VERSION ""

NS_ :

BS_:

BU_: WPC2 RLPSU DPSU APSU PSB SHVU_RR vHS_B2 FCS EMCU SLB ARS RCM CGW_CCU vDummy_HS_B ATS RLHV SGU PFSU ALBCU DSAU SWRC SHVU_FR RCS RRPSU BLTN_CAM SCM DLBCU OHCL RWPC RRHV WPC HOD ASAU

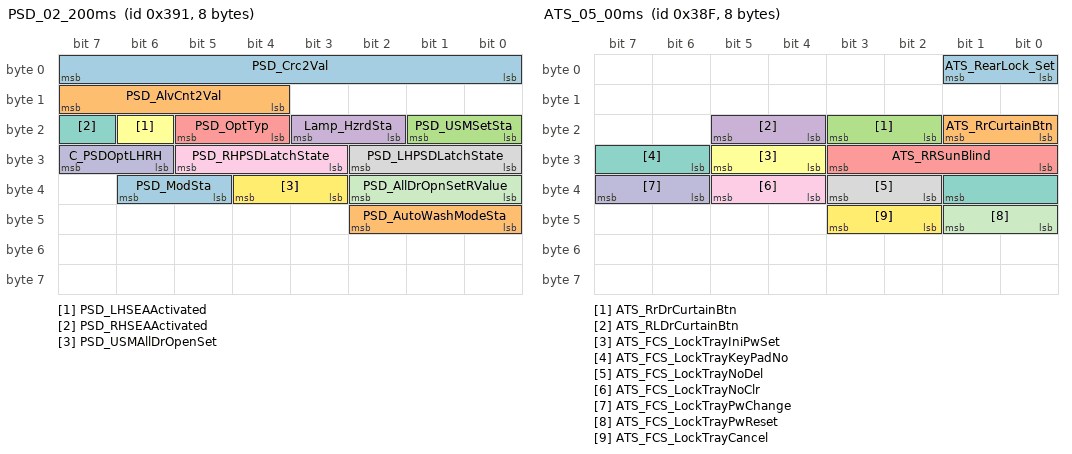
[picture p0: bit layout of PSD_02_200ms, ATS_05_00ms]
BO_ 913 PSD_02_200ms: 8 CGW_CCU
 SG_ PSD_Crc2Val : 0|8@1+ (1,0) [0|0] "" Vector__XXX
 SG_ PSD_AlvCnt2Val : 12|4@1+ (1,0) [0|0] "" Vector__XXX
 SG_ PSD_USMSetSta : 16|2@1+ (1,0) [0|0] "" Vector__XXX
 SG_ Lamp_HzrdSta : 18|2@1+ (1,0) [0|0] "" Vector__XXX
 SG_ PSD_OptTyp : 20|2@1+ (1,0) [0|0] "" Vector__XXX
 SG_ PSD_LHSEAActivated : 22|1@1+ (1,0) [0|0] "" Vector__XXX
 SG_ PSD_RHSEAActivated : 23|1@1+ (1,0) [0|0] "" Vector__XXX
 SG_ PSD_LHPSDLatchState : 24|3@1+ (1,0) [0|0] ""  ARS,PFSU,WPC2
 SG_ PSD_RHPSDLatchState : 27|3@1+ (1,0) [0|0] ""  ARS,PFSU,WPC2
 SG_ C_PSDOptLHRH : 30|2@1+ (1,0) [0|0] "" Vector__XXX
 SG_ PSD_AllDrOpnSetRValue : 32|3@1+ (1,0) [0|0] "" Vector__XXX
 SG_ PSD_USMAllDrOpenSet : 35|2@1+ (1,0) [0|0] "" Vector__XXX
 SG_ PSD_ModSta : 37|2@1+ (1,0) [0|0] "" Vector__XXX
 SG_ PSD_AutoWashModeSta : 40|3@1+ (1,0) [0|0] "" Vector__XXX

BO_ 911 ATS_05_00ms: 8 ATS
 SG_ ATS_RearLock_Set : 0|2@1+ (1,0) [0|0] ""  CGW_CCU
 SG_ ATS_RrCurtainBtn : 16|2@1+ (1,0) [0|0] ""  CGW_CCU
 SG_ ATS_RrDrCurtainBtn : 18|2@1+ (1,0) [0|0] "" Vector__XXX
 SG_ ATS_RLDrCurtainBtn : 20|2@1+ (1,0) [0|0] "" Vector__XXX
 SG_ ATS_RRSunBlind : 24|4@1+ (1,0) [0|0] ""  RCM,CGW_CCU
 SG_ ATS_FCS_LockTrayIniPwSet : 28|2@1+ (1,0) [0|0] ""  FCS
 SG_ ATS_FCS_LockTrayKeyPadNo : 30|4@1+ (1,0) [0|0] ""  FCS
 SG_ ATS_FCS_LockTrayNoDel : 34|2@1+ (1,0) [0|0] ""  FCS
 SG_ ATS_FCS_LockTrayNoClr : 36|2@1+ (1,0) [0|0] ""  FCS
 SG_ ATS_FCS_LockTrayPwChange : 38|2@1+ (1,0) [0|0] ""  FCS
 SG_ ATS_FCS_LockTrayPwReset : 40|2@1+ (1,0) [0|0] ""  FCS
 SG_ ATS_FCS_LockTrayCancel : 42|2@1+ (1,0) [0|0] ""  FCS

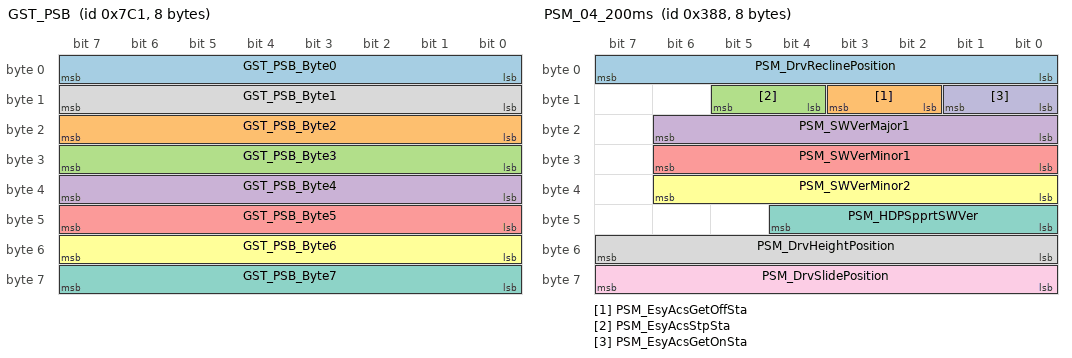
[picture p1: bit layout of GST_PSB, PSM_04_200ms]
BO_ 1985 GST_PSB: 8 CGW_CCU
 SG_ GST_PSB_Byte0 : 0|8@1+ (1,0) [0|0] ""  PSB
 SG_ GST_PSB_Byte2 : 16|8@1+ (1,0) [0|0] ""  PSB
 SG_ GST_PSB_Byte3 : 24|8@1+ (1,0) [0|0] ""  PSB
 SG_ GST_PSB_Byte4 : 32|8@1+ (1,0) [0|0] ""  PSB
 SG_ GST_PSB_Byte5 : 40|8@1+ (1,0) [0|0] ""  PSB
 SG_ GST_PSB_Byte6 : 48|8@1+ (1,0) [0|0] ""  PSB
 SG_ GST_PSB_Byte7 : 56|8@1+ (1,0) [0|0] ""  PSB
 SG_ GST_PSB_Byte1 : 8|8@1+ (1,0) [0|0] ""  PSB

BO_ 2382594817 DATC_06_200ms_1: 8 CGW_CCU
 SG_ DATC_Crc6Val : 0|16@1+ (1,0) [0|0] "" Vector__XXX
 SG_ DATC_AlvCnt6Val : 16|8@1+ (1,0) [0|0] "" Vector__XXX
 SG_ DATC_RrAcDis : 24|2@1+ (1,0) [0|0] "" Vector__XXX
 SG_ DATC_MaxAcDis : 26|2@1+ (1,0) [0|0] "" Vector__XXX
 SG_ DATC_SyncDis : 28|2@1+ (1,0) [0|0] ""  ATS
 SG_ DATC_OpSta : 32|3@1+ (1,0) [0|0] ""  ATS
 SG_ DATC_FrDfgSta : 35|2@1+ (1,0) [0|0] "" Vector__XXX
 SG_ DATC_SmrtVntDis : 37|2@1+ (1,0) [0|0] "" Vector__XXX
 SG_ DATC_AutoDfgBlnkDis : 40|2@1+ (1,0) [0|0] "" Vector__XXX
 SG_ DATC_AutoDfgSysOffDis : 42|2@1+ (1,0) [0|0] "" Vector__XXX
 SG_ DATC_SchdldVntOpSta : 50|2@1+ (1,0) [0|0] "" Vector__XXX
 SG_ DATC_3rdAcDis : 52|2@1+ (1,0) [0|0] "" Vector__XXX
 SG_ DATC_ArClnIND : 54|2@1+ (1,0) [0|0] ""  ATS
 SG_ DATC_RrDfgInd : 56|2@1+ (1,0) [0|0] "" Vector__XXX
 SG_ DATC_FrModDEFInd : 58|2@1+ (1,0) [0|0] "" Vector__XXX
 SG_ DATC_FrModVentInd : 60|2@1+ (1,0) [0|0] "" Vector__XXX
 SG_ DATC_FrModFloorInd : 62|2@1+ (1,0) [0|0] "" Vector__XXX

BO_ 905 SBCM_RR_01_200ms: 8 CGW_CCU
 SG_ SBCM_RR_Crc1Val : 0|8@1+ (1,0) [0|0] "" Vector__XXX
 SG_ RR_CrashUnlockCmd : 10|1@1+ (1,0) [0|0] ""  BLTN_CAM
 SG_ SBCM_RR_AlvCnt1Val : 12|4@1+ (1,0) [0|0] "" Vector__XXX
 SG_ Warn_RrRtDrSwSta_SBCM : 16|2@1+ (1,0) [0|0] ""  WPC,RWPC,APSU,RRPSU,ATS,BLTN_CAM,WPC2
 SG_ DoorLock_RrRtDrUnLkSta_SBCM : 18|2@1+ (1,0) [0|0] ""  ATS
 SG_ RR_SEAActivated : 20|2@1+ (1,0) [0|0] "" Vector__XXX
 SG_ RR_SEAWarn : 22|2@1+ (1,0) [0|0] "" Vector__XXX
 SG_ RR_SEWWarn : 24|2@1+ (1,0) [0|0] "" Vector__XXX
 SG_ RR_ReleaseWarn : 26|2@1+ (1,0) [0|0] "" Vector__XXX
 SG_ RR_SWFailAlarm : 28|2@1+ (1,0) [0|0] "" Vector__XXX
 SG_ RR_ChildLock_ActnFlSta : 30|2@1+ (1,0) [0|0] "" Vector__XXX
 SG_ RR_MRActivationAlarm : 32|2@1+ (1,0) [0|0] "" Vector__XXX
 SG_ RR_ChildLock_Status : 34|2@1+ (1,0) [0|0] "" Vector__XXX
 SG_ USM_RRGhostDoorSta : 36|2@1+ (1,0) [0|0] "" Vector__XXX
 SG_ DoorLock_PDSLkSwSta_RR : 40|2@1+ (1,0) [0|0] "" Vector__XXX
 SG_ PDS_TypeOption_RR : 42|2@1+ (1,0) [0|0] "" Vector__XXX
 SG_ RRDoorPushAlarm : 8|2@1+ (1,0) [0|0] "" Vector__XXX

BO_ 904 PSM_04_200ms: 8 DPSU
 SG_ PSM_DrvReclinePosition : 0|8@1+ (1,0) [0|0] ""  CGW_CCU
 SG_ PSM_EsyAcsGetOffSta : 10|2@1+ (1,0) [0|0] ""  DLBCU,DSAU
 SG_ PSM_EsyAcsStpSta : 12|2@1+ (1,0) [0|0] ""  DLBCU,DSAU
 SG_ PSM_SWVerMajor1 : 16|7@1+ (1,0) [0|0] ""  CGW_CCU
 SG_ PSM_SWVerMinor1 : 24|7@1+ (1,0) [0|0] ""  CGW_CCU
 SG_ PSM_SWVerMinor2 : 32|7@1+ (1,0) [0|0] ""  CGW_CCU
 SG_ PSM_HDPSpprtSWVer : 40|5@1+ (1,0) [0|0] ""  CGW_CCU
 SG_ PSM_DrvHeightPosition : 48|8@1+ (1,0) [0|0] ""  CGW_CCU
 SG_ PSM_DrvSlidePosition : 56|8@1+ (2,0) [0|0] ""  CGW_CCU
 SG_ PSM_EsyAcsGetOnSta : 8|2@1+ (1,0) [0|0] ""  DLBCU,DSAU

BO_ 903 PSM_03_200ms: 8 DPSU
 SG_ PSM_DrvStSldFwdDis : 0|2@1+ (1,0) [0|0] ""  CGW_CCU
 SG_ PSM_DrvStTiltDnDis : 10|2@1+ (1,0) [0|0] ""  CGW_CCU
 SG_ PSM_DrvStHghtUpDis : 12|2@1+ (1,0) [0|0] ""  CGW_CCU
 SG_ PSM_DrvStHghtDnDis : 14|2@1+ (1,0) [0|0] ""  CGW_CCU
 SG_ PSM_DrvStCushExtBckwdDis : 16|2@1+ (1,0) [0|0] ""  CGW_CCU
 SG_ PSM_DrvStCushExtFwdDis : 18|2@1+ (1,0) [0|0] ""  CGW_CCU
 SG_ PSM_DrvStSldBckwdDis : 2|2@1+ (1,0) [0|0] ""  CGW_CCU
 SG_ PSM_DrvStHdRstUpDis : 20|2@1+ (1,0) [0|0] ""  CGW_CCU
 SG_ PSM_DrvStHdRstDnDis : 22|2@1+ (1,0) [0|0] ""  CGW_CCU
 SG_ PSM_DrvStHdRstFwdDis : 24|2@1+ (1,0) [0|0] ""  CGW_CCU
 SG_ PSM_DrvStHdRstBckwdDis : 26|2@1+ (1,0) [0|0] ""  CGW_CCU
 SG_ PSM_DrvStLmbrDefDis : 32|2@1+ (1,0) [0|0] ""  CGW_CCU
 SG_ PSM_DrvStLmbrLoDis : 34|2@1+ (1,0) [0|0] ""  CGW_CCU
 SG_ PSM_DrvStLmbrMdlDis : 36|2@1+ (1,0) [0|0] ""  CGW_CCU
 SG_ PSM_DrvStLmbrUpDis : 38|2@1+ (1,0) [0|0] ""  CGW_CCU
 SG_ PSM_DrvStReclneFwdDis : 4|2@1+ (1,0) [0|0] ""  CGW_CCU
 SG_ PSM_DrvStBlstrDefDis : 40|2@1+ (1,0) [0|0] ""  CGW_CCU
 SG_ PSM_DrvStBlstrInfDis : 42|2@1+ (1,0) [0|0] ""  CGW_CCU
 SG_ PSM_DrvStReclneBckwdDis : 6|2@1+ (1,0) [0|0] ""  CGW_CCU
 SG_ PSM_DrvStTiltUpDis : 8|2@1+ (1,0) [0|0] ""  CGW_CCU

BO_ 902 PSM_02_200ms: 8 DPSU
 SG_ PSM_DrvStEsyAcsUSMSta : 0|3@1+ (1,0) [0|0] ""  DLBCU,DSAU,CGW_CCU
 SG_ PSM_SeatPosPlyBck_Sta : 10|3@1+ (1,0) [0|0] "" Vector__XXX
 SG_ PSM_SeatPos_Sta : 13|3@1+ (1,0) [0|0] "" Vector__XXX
 SG_ PSM_SeatPosSldLmt_Sta : 16|2@1+ (1,0) [0|0] ""  CGW_CCU
 SG_ PSM_SeatPosRclnLmt_Sta : 18|2@1+ (1,0) [0|0] ""  CGW_CCU
 SG_ SmrtIMS_StatureRspVal : 24|4@1+ (1,0) [0|0] ""  CGW_CCU
 SG_ SmrtIMS_SeatedHghtRspVal : 28|4@1+ (1,0) [0|0] ""  CGW_CCU
 SG_ SmrtIMS_WghtRspVal : 32|4@1+ (1,0) [0|0] ""  CGW_CCU
 SG_ SmartIMS_DisReq : 36|3@1+ (1,0) [0|0] ""  CGW_CCU
 SG_ SmrtIMS_ExitSta : 40|3@1+ (1,0) [0|0] ""  CGW_CCU
 SG_ PSM_DrvStRlxTiltUpDis : 43|2@1+ (1,0) [0|0] ""  CGW_CCU
 SG_ PSM_DrvStRlxTiltDnDis : 45|2@1+ (1,0) [0|0] ""  CGW_CCU
 SG_ PSM_DrvStLegUpDis : 47|2@1+ (1,0) [0|0] ""  CGW_CCU
 SG_ PSM_DrvStLegDnDis : 49|2@1+ (1,0) [0|0] ""  CGW_CCU
 SG_ Drv_2ndStAutoRlxEnable : 57|2@1+ (1,0) [0|0] ""  RLPSU,RRPSU
 SG_ Drv_AutoRlxSta : 59|2@1+ (1,0) [0|0] ""  RLPSU,RRPSU,CGW_CCU
 SG_ Drv_AutoReturnSta : 61|2@1+ (1,0) [0|0] ""  CGW_CCU
 SG_ PSM_IMSOptTyp : 8|2@1+ (1,0) [0|0] ""  CGW_CCU

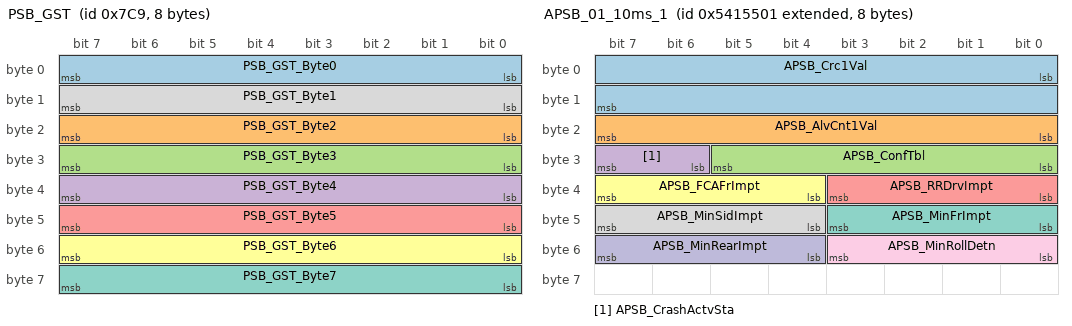
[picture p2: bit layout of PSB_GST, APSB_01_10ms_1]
BO_ 1993 PSB_GST: 8 PSB
 SG_ PSB_GST_Byte0 : 0|8@1+ (1,0) [0|0] ""  CGW_CCU
 SG_ PSB_GST_Byte2 : 16|8@1+ (1,0) [0|0] ""  CGW_CCU
 SG_ PSB_GST_Byte3 : 24|8@1+ (1,0) [0|0] ""  CGW_CCU
 SG_ PSB_GST_Byte4 : 32|8@1+ (1,0) [0|0] ""  CGW_CCU
 SG_ PSB_GST_Byte5 : 40|8@1+ (1,0) [0|0] ""  CGW_CCU
 SG_ PSB_GST_Byte6 : 48|8@1+ (1,0) [0|0] ""  CGW_CCU
 SG_ PSB_GST_Byte7 : 56|8@1+ (1,0) [0|0] ""  CGW_CCU
 SG_ PSB_GST_Byte1 : 8|8@1+ (1,0) [0|0] ""  CGW_CCU

BO_ 1016 HU_GNSS_14_1000ms: 8 CGW_CCU
 SG_ GNSS_MM_type : 0|4@1+ (1,0) [0|0] ""  BLTN_CAM

BO_ 1019 HU_MOOD_E_01: 8 CGW_CCU
 SG_ HU_MoodTherapyDrSeat : 0|2@1+ (1,0) [0|0] ""  DSAU
 SG_ HU_VitalityFragrance : 10|2@1+ (1,0) [0|0] "" Vector__XXX
 SG_ HU_VitalityCurtain : 12|2@1+ (1,0) [0|0] "" Vector__XXX
 SG_ HU_DelightMoodLamp : 14|2@1+ (1,0) [0|0] "" Vector__XXX
 SG_ HU_DelightFragrance : 16|2@1+ (1,0) [0|0] "" Vector__XXX
 SG_ HU_DelightCurtain : 18|2@1+ (1,0) [0|0] "" Vector__XXX
 SG_ HU_MoodTherapyPsSeat : 2|2@1+ (1,0) [0|0] ""  ASAU
 SG_ HU_CareMoodLamp : 20|2@1+ (1,0) [0|0] "" Vector__XXX
 SG_ HU_CareFragrance : 22|2@1+ (1,0) [0|0] "" Vector__XXX
 SG_ HU_CareMassage : 24|2@1+ (1,0) [0|0] ""  DSAU,ASAU
 SG_ HU_CareCurtain : 26|2@1+ (1,0) [0|0] "" Vector__XXX
 SG_ HU_ComfortMoodLamp : 28|2@1+ (1,0) [0|0] "" Vector__XXX
 SG_ HU_ComfortFragrance : 30|2@1+ (1,0) [0|0] "" Vector__XXX
 SG_ HU_ComfortMassage : 32|2@1+ (1,0) [0|0] ""  DSAU,ASAU
 SG_ HU_ComfortCurtain : 34|2@1+ (1,0) [0|0] "" Vector__XXX
 SG_ HU_MoodTherapyMode : 36|3@1+ (1,0) [0|0] ""  DSAU,ASAU
 SG_ HU_MoodTherapyRlSeat : 4|2@1+ (1,0) [0|0] "" Vector__XXX
 SG_ HU_MoodTherapyRrSeat : 6|2@1+ (1,0) [0|0] "" Vector__XXX
 SG_ HU_VitalityMoodLamp : 8|2@1+ (1,0) [0|0] "" Vector__XXX

BO_ 2235651330 APSB_01_10ms_2: 8 CGW_CCU

BO_ 2235651329 APSB_01_10ms_1: 8 CGW_CCU
 SG_ APSB_Crc1Val : 0|16@1+ (1,0) [0|0] "" Vector__XXX
 SG_ APSB_AlvCnt1Val : 16|8@1+ (1,0) [0|0] "" Vector__XXX
 SG_ APSB_ConfTbl : 24|6@1+ (1,0) [0|0] ""  PSB
 SG_ APSB_CrashActvSta : 30|2@1+ (1,0) [0|0] ""  PSB
 SG_ APSB_RRDrvImpt : 32|4@1+ (1,0) [0|0] ""  PSB
 SG_ APSB_FCAFrImpt : 36|4@1+ (1,0) [0|0] ""  PSB
 SG_ APSB_MinFrImpt : 40|4@1+ (1,0) [0|0] ""  PSB
 SG_ APSB_MinSidImpt : 44|4@1+ (1,0) [0|0] ""  PSB
 SG_ APSB_MinRollDetn : 48|4@1+ (1,0) [0|0] ""  PSB
 SG_ APSB_MinRearImpt : 52|4@1+ (1,0) [0|0] ""  PSB

BO_ 1015 HU_GNSS_13_1000ms: 8 CGW_CCU
 SG_ HU_MM_Altitude : 0|32@1- (0.01,0) [0|0] "m"  BLTN_CAM
 SG_ HU_MM_Heading : 32|32@1+ (1,0) [0|0] "¢ª"  BLTN_CAM

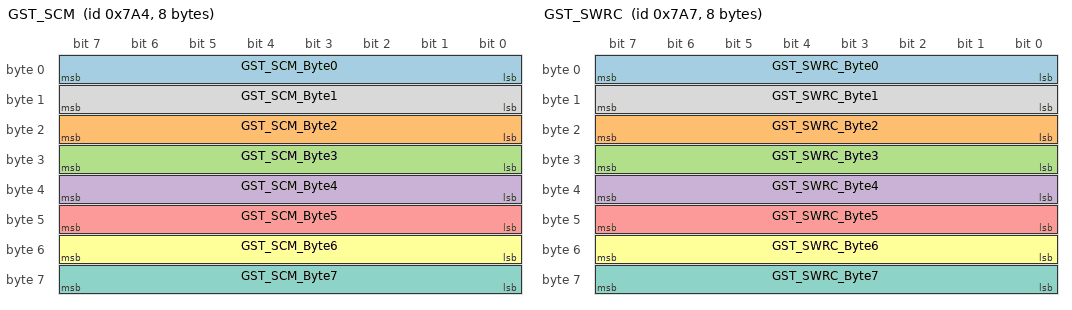
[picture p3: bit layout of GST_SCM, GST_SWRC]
BO_ 1956 GST_SCM: 8 CGW_CCU
 SG_ GST_SCM_Byte0 : 0|8@1+ (1,0) [0|0] ""  SCM
 SG_ GST_SCM_Byte2 : 16|8@1+ (1,0) [0|0] ""  SCM
 SG_ GST_SCM_Byte3 : 24|8@1+ (1,0) [0|0] ""  SCM
 SG_ GST_SCM_Byte4 : 32|8@1+ (1,0) [0|0] ""  SCM
 SG_ GST_SCM_Byte5 : 40|8@1+ (1,0) [0|0] ""  SCM
 SG_ GST_SCM_Byte6 : 48|8@1+ (1,0) [0|0] ""  SCM
 SG_ GST_SCM_Byte7 : 56|8@1+ (1,0) [0|0] ""  SCM
 SG_ GST_SCM_Byte1 : 8|8@1+ (1,0) [0|0] ""  SCM

BO_ 1959 GST_SWRC: 8 CGW_CCU
 SG_ GST_SWRC_Byte0 : 0|8@1+ (1,0) [0|0] ""  SWRC
 SG_ GST_SWRC_Byte2 : 16|8@1+ (1,0) [0|0] ""  SWRC
 SG_ GST_SWRC_Byte3 : 24|8@1+ (1,0) [0|0] ""  SWRC
 SG_ GST_SWRC_Byte4 : 32|8@1+ (1,0) [0|0] ""  SWRC
 SG_ GST_SWRC_Byte5 : 40|8@1+ (1,0) [0|0] ""  SWRC
 SG_ GST_SWRC_Byte6 : 48|8@1+ (1,0) [0|0] ""  SWRC
 SG_ GST_SWRC_Byte7 : 56|8@1+ (1,0) [0|0] ""  SWRC
 SG_ GST_SWRC_Byte1 : 8|8@1+ (1,0) [0|0] ""  SWRC

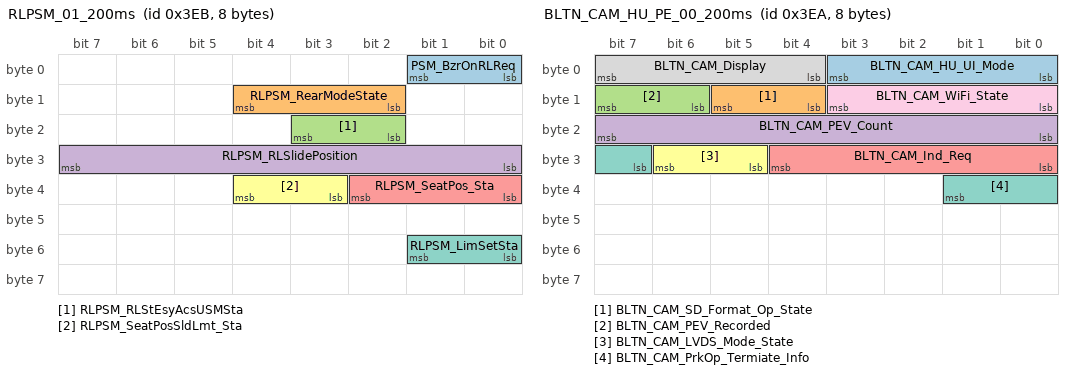
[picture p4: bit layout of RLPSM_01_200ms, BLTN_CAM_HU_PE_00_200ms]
BO_ 1003 RLPSM_01_200ms: 8 RRPSU
 SG_ PSM_BzrOnRLReq : 0|2@1+ (1,0) [0|0] ""  ATS,DPSU
 SG_ RLPSM_RearModeState : 10|3@1+ (1,0) [0|0] ""  APSU,ATS,DPSU,OHCL,CGW_CCU
 SG_ RLPSM_RLStEsyAcsUSMSta : 18|2@1+ (1,0) [0|0] ""  ATS,CGW_CCU
 SG_ RLPSM_RLSlidePosition : 24|8@1+ (2,0) [0|0] ""  APSU,RRPSU
 SG_ RLPSM_SeatPos_Sta : 32|3@1+ (1,0) [0|0] ""  RRPSU
 SG_ RLPSM_SeatPosSldLmt_Sta : 35|2@1+ (1,0) [0|0] "" Vector__XXX
 SG_ RLPSM_LimSetSta : 48|2@1+ (1,0) [0|0] "" Vector__XXX

BO_ 1002 BLTN_CAM_HU_PE_00_200ms: 8 BLTN_CAM
 SG_ BLTN_CAM_HU_UI_Mode : 0|4@1+ (1,0) [0|0] ""  CGW_CCU
 SG_ BLTN_CAM_SD_Format_Op_State : 12|2@1+ (1,0) [0|0] ""  CGW_CCU
 SG_ BLTN_CAM_PEV_Recorded : 14|2@1+ (1,0) [0|0] ""  CGW_CCU
 SG_ BLTN_CAM_PEV_Count : 16|8@1+ (1,0) [0|0] ""  CGW_CCU
 SG_ BLTN_CAM_Ind_Req : 24|5@1+ (1,0) [0|0] ""  CGW_CCU
 SG_ BLTN_CAM_LVDS_Mode_State : 29|2@1+ (1,0) [0|0] ""  CGW_CCU
 SG_ BLTN_CAM_PrkOp_Termiate_Info : 31|3@1+ (1,0) [0|0] ""  CGW_CCU
 SG_ BLTN_CAM_Display : 4|4@1+ (1,0) [0|0] ""  CGW_CCU
 SG_ BLTN_CAM_WiFi_State : 8|4@1+ (1,0) [0|0] ""  CGW_CCU

BO_ 1005 RLPSU_01_200ms: 8 RLPSU
 SG_ RLPSU_FldDis : 0|2@1+ (1,0) [0|0] ""  CGW_CCU
 SG_ RLPSU_TiltDownDis : 10|2@1+ (1,0) [0|0] ""  CGW_CCU
 SG_ RLPSU_RclFwdDis : 12|2@1+ (1,0) [0|0] ""  CGW_CCU
 SG_ RLPSU_RclBwdDis : 14|2@1+ (1,0) [0|0] ""  CGW_CCU
 SG_ RLPSU_RlxModeDis : 16|2@1+ (1,0) [0|0] "" Vector__XXX
 SG_ RLPSU_Folding_SW : 18|2@1+ (1,0) [0|0] "" Vector__XXX
 SG_ RLPSU_UnFldDis : 2|2@1+ (1,0) [0|0] "" Vector__XXX
 SG_ RLPSU_Unfolding_SW : 20|2@1+ (1,0) [0|0] "" Vector__XXX
 SG_ RLPSU_WalkIn_SW : 22|2@1+ (1,0) [0|0] "" Vector__XXX
 SG_ RLPSU_UnwalkIn_SW : 24|2@1+ (1,0) [0|0] "" Vector__XXX
 SG_ RLPSU_Folding_Postion : 26|4@1+ (1,0) [0|0] ""  CGW_CCU
 SG_ RLPSU_Folding_State_PopUp : 30|3@1+ (1,0) [0|0] "" Vector__XXX
 SG_ RLPSU_Relax_State_Popup : 33|3@1+ (1,0) [0|0] "" Vector__XXX
 SG_ RLPSU_SlideFwdDis : 36|2@1+ (1,0) [0|0] ""  CGW_CCU
 SG_ RLPSU_SlideBwdDis : 38|2@1+ (1,0) [0|0] ""  CGW_CCU
 SG_ RLPSU_WalkInDis : 4|2@1+ (1,0) [0|0] "" Vector__XXX
 SG_ RLPSU_WalkInState : 40|2@1+ (1,0) [0|0] "" Vector__XXX
 SG_ RLPSU_UnWalkInDis : 6|2@1+ (1,0) [0|0] "" Vector__XXX
 SG_ RLPSU_TiltUpDis : 8|2@1+ (1,0) [0|0] ""  CGW_CCU

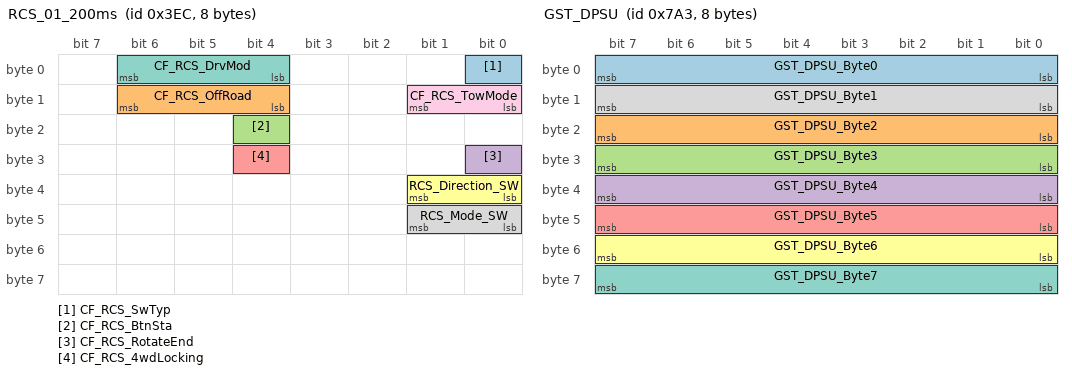
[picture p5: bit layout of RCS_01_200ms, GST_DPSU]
BO_ 1004 RCS_01_200ms: 8 RCS
 SG_ CF_RCS_SwTyp : 0|1@1+ (1,0) [0|0] "Watt"  CGW_CCU
 SG_ CF_RCS_OffRoad : 12|3@1+ (1,0) [0|0] "Watt"  CGW_CCU
 SG_ CF_RCS_BtnSta : 20|1@1+ (1,0) [0|0] "Watt"  CGW_CCU
 SG_ CF_RCS_RotateEnd : 24|1@1+ (1,0) [0|0] "Watt"  CGW_CCU
 SG_ CF_RCS_4wdLocking : 28|1@1+ (1,0) [0|0] "Watt"  CGW_CCU
 SG_ RCS_Direction_SW : 32|2@1+ (1,0) [0|0] ""  CGW_CCU
 SG_ CF_RCS_DrvMod : 4|3@1+ (1,0) [0|0] "Watt"  CGW_CCU
 SG_ RCS_Mode_SW : 40|2@1+ (1,0) [0|0] ""  CGW_CCU
 SG_ CF_RCS_TowMode : 8|2@1+ (1,0) [0|0] ""  CGW_CCU

BO_ 1955 GST_DPSU: 8 CGW_CCU
 SG_ GST_DPSU_Byte0 : 0|8@1+ (1,0) [0|0] ""  DPSU
 SG_ GST_DPSU_Byte2 : 16|8@1+ (1,0) [0|0] ""  DPSU
 SG_ GST_DPSU_Byte3 : 24|8@1+ (1,0) [0|0] ""  DPSU
 SG_ GST_DPSU_Byte4 : 32|8@1+ (1,0) [0|0] ""  DPSU
 SG_ GST_DPSU_Byte5 : 40|8@1+ (1,0) [0|0] ""  DPSU
 SG_ GST_DPSU_Byte6 : 48|8@1+ (1,0) [0|0] ""  DPSU
 SG_ GST_DPSU_Byte7 : 56|8@1+ (1,0) [0|0] ""  DPSU
 SG_ GST_DPSU_Byte1 : 8|8@1+ (1,0) [0|0] ""  DPSU

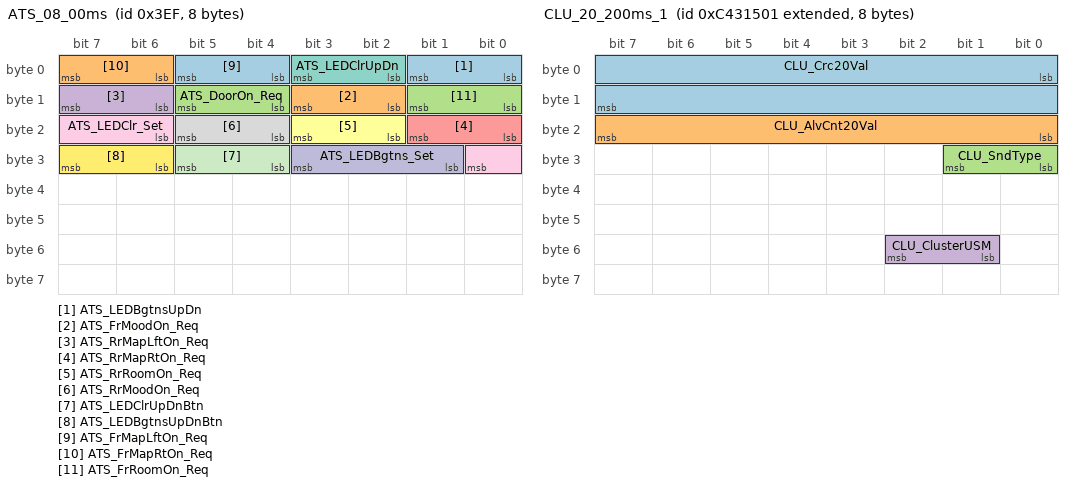
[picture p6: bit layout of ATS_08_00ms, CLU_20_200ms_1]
BO_ 1007 ATS_08_00ms: 8 ATS
 SG_ ATS_LEDBgtnsUpDn : 0|2@1+ (1,0) [0|0] ""  OHCL
 SG_ ATS_FrMoodOn_Req : 10|2@1+ (1,0) [0|0] ""  OHCL
 SG_ ATS_DoorOn_Req : 12|2@1+ (1,0) [0|0] ""  OHCL
 SG_ ATS_RrMapLftOn_Req : 14|2@1+ (1,0) [0|0] ""  OHCL
 SG_ ATS_RrMapRtOn_Req : 16|2@1+ (1,0) [0|0] ""  OHCL
 SG_ ATS_RrRoomOn_Req : 18|2@1+ (1,0) [0|0] ""  OHCL
 SG_ ATS_LEDClrUpDn : 2|2@1+ (1,0) [0|0] ""  OHCL
 SG_ ATS_RrMoodOn_Req : 20|2@1+ (1,0) [0|0] ""  OHCL
 SG_ ATS_LEDClr_Set : 22|3@1+ (1,0) [0|0] ""  OHCL
 SG_ ATS_LEDBgtns_Set : 25|3@1+ (1,0) [0|0] ""  OHCL
 SG_ ATS_LEDClrUpDnBtn : 28|2@1+ (1,0) [0|0] "" Vector__XXX
 SG_ ATS_LEDBgtnsUpDnBtn : 30|2@1+ (1,0) [0|0] "" Vector__XXX
 SG_ ATS_FrMapLftOn_Req : 4|2@1+ (1,0) [0|0] ""  OHCL
 SG_ ATS_FrMapRtOn_Req : 6|2@1+ (1,0) [0|0] ""  OHCL
 SG_ ATS_FrRoomOn_Req : 8|2@1+ (1,0) [0|0] ""  OHCL

BO_ 1006 RRPSU_01_200ms: 8 RRPSU
 SG_ RRPSU_FldDis : 0|2@1+ (1,0) [0|0] ""  CGW_CCU
 SG_ RRPSU_TiltDnDis : 10|2@1+ (1,0) [0|0] ""  CGW_CCU
 SG_ RRPSU_RecFwdDis : 12|2@1+ (1,0) [0|0] ""  CGW_CCU
 SG_ RRPSU_RecBwdDis : 14|2@1+ (1,0) [0|0] ""  CGW_CCU
 SG_ RRPSU_RlxModeDis : 16|2@1+ (1,0) [0|0] "" Vector__XXX
 SG_ RRPSU_Folding_SW : 18|2@1+ (1,0) [0|0] "" Vector__XXX
 SG_ RRPSU_UnFldDis : 2|2@1+ (1,0) [0|0] "" Vector__XXX
 SG_ RRPSU_Unfolding_SW : 20|2@1+ (1,0) [0|0] "" Vector__XXX
 SG_ RRPSU_WalkIn_SW : 22|2@1+ (1,0) [0|0] "" Vector__XXX
 SG_ RRPSU_UnwalkIn_SW : 24|2@1+ (1,0) [0|0] "" Vector__XXX
 SG_ RRPSU_Folding_Postion : 26|4@1+ (1,0) [0|0] ""  CGW_CCU
 SG_ RRPSU_Folding_State_Popup : 30|3@1+ (1,0) [0|0] "" Vector__XXX
 SG_ RRPSU_Relax_State_Popup : 33|3@1+ (1,0) [0|0] "" Vector__XXX
 SG_ RRPSU_SlideFwdDis : 36|2@1+ (1,0) [0|0] ""  CGW_CCU
 SG_ RRPSU_SlideBwdDis : 38|2@1+ (1,0) [0|0] ""  CGW_CCU
 SG_ RRPSU_WalkinDis : 4|2@1+ (1,0) [0|0] "" Vector__XXX
 SG_ RRPSU_WalkInState : 40|2@1+ (1,0) [0|0] "" Vector__XXX
 SG_ RRPSU_UnwalkinDis : 6|2@1+ (1,0) [0|0] "" Vector__XXX
 SG_ RRPSU_TiltUpDis : 8|2@1+ (1,0) [0|0] ""  CGW_CCU

BO_ 2353206529 CLU_20_200ms_1: 8 CGW_CCU
 SG_ CLU_Crc20Val : 0|16@1+ (1,0) [0|0] "" Vector__XXX
 SG_ CLU_AlvCnt20Val : 16|8@1+ (1,0) [0|0] "" Vector__XXX
 SG_ CLU_SndType : 24|2@1- (1,0) [0|0] "" Vector__XXX
 SG_ CLU_ClusterUSM : 49|2@1+ (1,0) [0|0] ""  WPC,WPC2

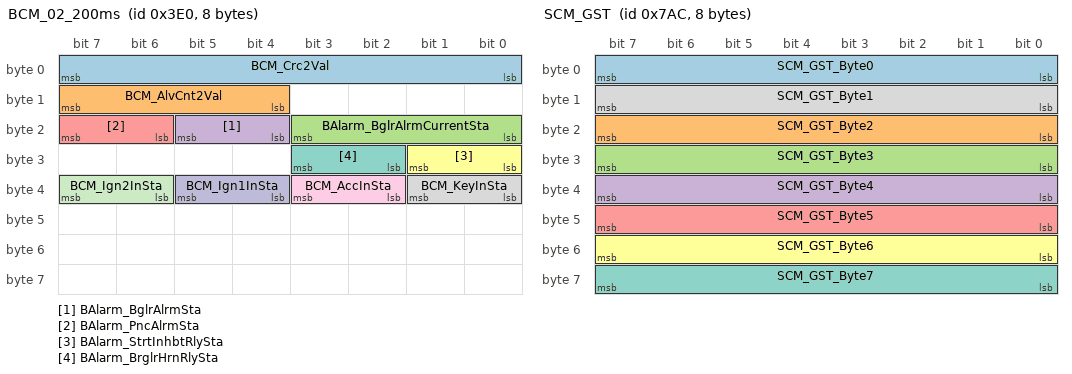
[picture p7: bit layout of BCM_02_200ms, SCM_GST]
BO_ 992 BCM_02_200ms: 8 CGW_CCU
 SG_ BCM_Crc2Val : 0|8@1+ (1,0) [0|0] "" Vector__XXX
 SG_ BCM_AlvCnt2Val : 12|4@1+ (1,0) [0|0] "" Vector__XXX
 SG_ BAlarm_BglrAlrmCurrentSta : 16|4@1+ (1,0) [0|0] ""  BLTN_CAM
 SG_ BAlarm_BglrAlrmSta : 20|2@1+ (1,0) [0|0] "" Vector__XXX
 SG_ BAlarm_PncAlrmSta : 22|2@1+ (1,0) [0|0] "" Vector__XXX
 SG_ BAlarm_StrtInhbtRlySta : 24|2@1+ (1,0) [0|0] "" Vector__XXX
 SG_ BAlarm_BrglrHrnRlySta : 26|2@1+ (1,0) [0|0] "" Vector__XXX
 SG_ BCM_KeyInSta : 32|2@1+ (1,0) [0|0] ""  SWRC,APSU,RLHV,RRHV,SHVU_FR,SHVU_RR,DPSU,DLBCU,PFSU,RRPSU,RLPSU,SGU,ALBCU
 SG_ BCM_AccInSta : 34|2@1+ (1,0) [0|0] ""  SCM,SWRC,APSU,RLHV,RRHV,SHVU_FR,SHVU_RR,DPSU,DLBCU,PFSU,RRPSU,RLPSU,ATS,DSAU,ASAU,SGU,ALBCU,WPC2
 SG_ BCM_Ign1InSta : 36|2@1+ (1,0) [0|0] ""  SCM,SWRC,APSU,RLHV,RRHV,SHVU_FR,SHVU_RR,DPSU,DLBCU,PFSU,RRPSU,RLPSU,HOD,ATS,DSAU,ASAU,RCM,SGU,ALBCU
 SG_ BCM_Ign2InSta : 38|2@1+ (1,0) [0|0] ""  SCM,SWRC,APSU,RLHV,RRHV,SHVU_FR,SHVU_RR,DPSU,DLBCU,PFSU,RRPSU,RLPSU,ATS,DSAU,ASAU,RCM,SGU,ALBCU

BO_ 1964 SCM_GST: 8 SCM
 SG_ SCM_GST_Byte0 : 0|8@1+ (1,0) [0|0] ""  CGW_CCU
 SG_ SCM_GST_Byte2 : 16|8@1+ (1,0) [0|0] ""  CGW_CCU
 SG_ SCM_GST_Byte3 : 24|8@1+ (1,0) [0|0] ""  CGW_CCU
 SG_ SCM_GST_Byte4 : 32|8@1+ (1,0) [0|0] ""  CGW_CCU
 SG_ SCM_GST_Byte5 : 40|8@1+ (1,0) [0|0] ""  CGW_CCU
 SG_ SCM_GST_Byte6 : 48|8@1+ (1,0) [0|0] ""  CGW_CCU
 SG_ SCM_GST_Byte7 : 56|8@1+ (1,0) [0|0] ""  CGW_CCU
 SG_ SCM_GST_Byte1 : 8|8@1+ (1,0) [0|0] ""  CGW_CCU

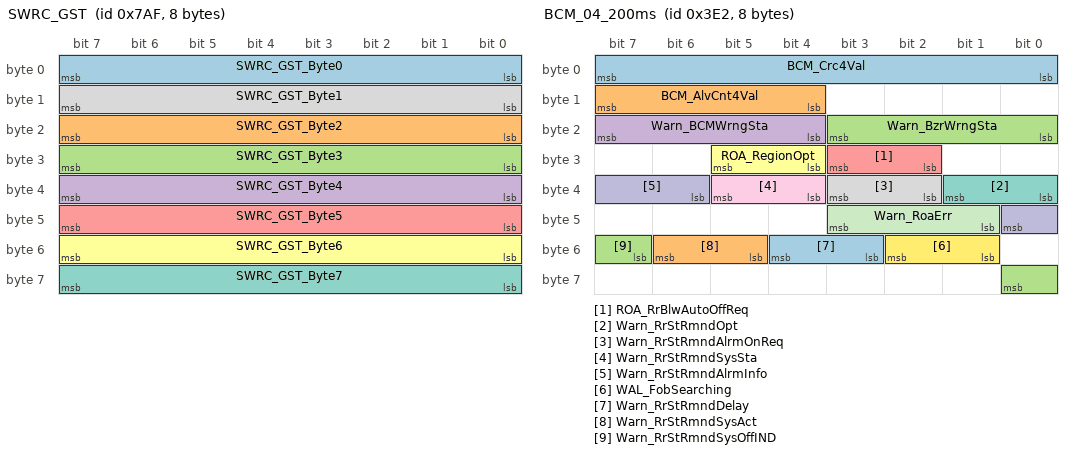
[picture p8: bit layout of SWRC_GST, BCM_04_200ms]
BO_ 1967 SWRC_GST: 8 SWRC
 SG_ SWRC_GST_Byte0 : 0|8@1+ (1,0) [0|0] ""  CGW_CCU
 SG_ SWRC_GST_Byte2 : 16|8@1+ (1,0) [0|0] ""  CGW_CCU
 SG_ SWRC_GST_Byte3 : 24|8@1+ (1,0) [0|0] ""  CGW_CCU
 SG_ SWRC_GST_Byte4 : 32|8@1+ (1,0) [0|0] ""  CGW_CCU
 SG_ SWRC_GST_Byte5 : 40|8@1+ (1,0) [0|0] ""  CGW_CCU
 SG_ SWRC_GST_Byte6 : 48|8@1+ (1,0) [0|0] ""  CGW_CCU
 SG_ SWRC_GST_Byte7 : 56|8@1+ (1,0) [0|0] ""  CGW_CCU
 SG_ SWRC_GST_Byte1 : 8|8@1+ (1,0) [0|0] ""  CGW_CCU

BO_ 2353206530 CLU_20_200ms_2: 8 CGW_CCU

BO_ 994 BCM_04_200ms: 8 CGW_CCU
 SG_ BCM_Crc4Val : 0|8@1+ (1,0) [0|0] "" Vector__XXX
 SG_ BCM_AlvCnt4Val : 12|4@1+ (1,0) [0|0] "" Vector__XXX
 SG_ Warn_BzrWrngSta : 16|4@1+ (1,0) [0|0] "" Vector__XXX
 SG_ Warn_BCMWrngSta : 20|4@1+ (1,0) [0|0] "" Vector__XXX
 SG_ ROA_RrBlwAutoOffReq : 26|2@1+ (1,0) [0|0] "" Vector__XXX
 SG_ ROA_RegionOpt : 28|2@1+ (1,0) [0|0] "" Vector__XXX
 SG_ Warn_RrStRmndOpt : 32|2@1+ (1,0) [0|0] "" Vector__XXX
 SG_ Warn_RrStRmndAlrmOnReq : 34|2@1+ (1,0) [0|0] "" Vector__XXX
 SG_ Warn_RrStRmndSysSta : 36|2@1+ (1,0) [0|0] "" Vector__XXX
 SG_ Warn_RrStRmndAlrmInfo : 38|3@1+ (1,0) [0|0] ""  SWRC
 SG_ Warn_RoaErr : 41|3@1+ (1,0) [0|0] "" Vector__XXX
 SG_ WAL_FobSearching : 49|2@1+ (1,0) [0|0] "" Vector__XXX
 SG_ Warn_RrStRmndDelay : 51|2@1+ (1,0) [0|0] "" Vector__XXX
 SG_ Warn_RrStRmndSysAct : 53|2@1+ (1,0) [0|0] "" Vector__XXX
 SG_ Warn_RrStRmndSysOffIND : 55|2@1+ (1,0) [0|0] "" Vector__XXX

BO_TX_BU_ 1003 : RRPSU,RLPSU;
BO_TX_BU_ 1005 : RLPSU,RRPSU;
CM_ BO_ 913 "[PE] Periodic and On Event";
CM_ SG_ 913 PSD_Crc2Val "PSD_CyclicRedundancyCheck2Value";
CM_ SG_ 913 PSD_AlvCnt2Val "PSD_AliveCounter2Value";
CM_ SG_ 913 Lamp_HzrdSta "Lamp_HazardStatus";
CM_ SG_ 913 PSD_OptTyp "PSD_OptionType";
CM_ SG_ 913 PSD_AllDrOpnSetRValue "All Door(PSD PTG) Open Function by FOB Unlock Long Key USM Setting Signal";
CM_ SG_ 913 PSD_USMAllDrOpenSet "All Door Open Function by FOB Unlock Long Key Setting Signal for PTG by PSD";
CM_ SG_ 913 PSD_ModSta "PSD Module Status";
CM_ BO_ 911 "[EC] On Event and On Change";
CM_ SG_ 911 ATS_RearLock_Set "RRC and RSE Lock Touch Button";
CM_ SG_ 911 ATS_RrCurtainBtn "Rear Curtain Touch Button";
CM_ SG_ 911 ATS_RrDrCurtainBtn "Rear Door and Curtain Touch Button";
CM_ SG_ 911 ATS_RLDrCurtainBtn "Rear Door and Curtain Touch Button";
CM_ SG_ 911 ATS_RRSunBlind "SunBlind Touch Botton";
CM_ SG_ 911 ATS_FCS_LockTrayIniPwSet "Locking Tray ºñ¹Ð¹øÈ£ ¼³Á¤ ÁøÀÔ ¹öÆ°";
CM_ SG_ 911 ATS_FCS_LockTrayKeyPadNo "Locking Tray ºñ¹Ð¹øÈ£ ¼³Á¤ key Pad ¹öÆ°";
CM_ SG_ 911 ATS_FCS_LockTrayNoDel "Locking Tray ºñ¹Ð¹øÈ£ ¼³Á¤ ¼ýÀÚ »èÁ¦ ¹öÆ°";
CM_ SG_ 911 ATS_FCS_LockTrayNoClr "Locking Tray ºñ¹Ð¹øÈ£ ¼³Á¤ ¼ýÀÚ Clear ¹öÆ°";
CM_ SG_ 911 ATS_FCS_LockTrayPwChange "Locking Tray ºñ¹Ð¹øÈ£ º¯°æ ÁøÀÔ ¹öÆ°";
CM_ SG_ 911 ATS_FCS_LockTrayPwReset "Locking Tray ºñ¹Ð¹øÈ£ ÃÊ±âÈ­ ÁøÀÔ ¹öÆ° (ºñ¹Ð¹øÈ£ ¾ø´Â »óÅÂ·Î ¿øº¹)";
CM_ SG_ 911 ATS_FCS_LockTrayCancel "Locking Tray ºñ¹Ð¹øÈ£ ÀÔ·Â È­¸é Cancel ¹öÆ°";
CM_ BO_ 1985 "[TP] Transport Protocol";
CM_ BO_ 2382594817 "[PE] Periodic and On Event";
CM_ SG_ 2382594817 DATC_Crc6Val "DATC_CyclicRedundancyCheck6Value";
CM_ SG_ 2382594817 DATC_AlvCnt6Val "DATC_AliveCounter6Value";
CM_ SG_ 2382594817 DATC_RrAcDis "DATC_RearAirconDisplay";
CM_ SG_ 2382594817 DATC_MaxAcDis "DATC_MaxACDisplay";
CM_ SG_ 2382594817 DATC_SyncDis "DATC_SyncDisplay";
CM_ SG_ 2382594817 DATC_OpSta "DATC_OperationStatus";
CM_ SG_ 2382594817 DATC_FrDfgSta "DATC_FrontDefogStatus";
CM_ SG_ 2382594817 DATC_SmrtVntDis "DATC_SmartVentilationDisplay";
CM_ SG_ 2382594817 DATC_AutoDfgBlnkDis "DATC_AutoDefogBlinkDisplay";
CM_ SG_ 2382594817 DATC_AutoDfgSysOffDis "DATC_AutoDefogSystemOffDisplay";
CM_ SG_ 2382594817 DATC_SchdldVntOpSta "Operating Status of Scheduled Ventilation";
CM_ SG_ 2382594817 DATC_3rdAcDis "DATC_3rdAirconDisplay";
CM_ SG_ 2382594817 DATC_ArClnIND "DATC_AirCleanIndicator";
CM_ SG_ 2382594817 DATC_RrDfgInd "Rear Defog Switch indicator signal";
CM_ SG_ 2382594817 DATC_FrModDEFInd "Mode DEF button indicator status signal in case All Mode Button Type";
CM_ SG_ 2382594817 DATC_FrModVentInd "Mode VENT button indicator status signal in case ALL Mode Button Type";
CM_ SG_ 2382594817 DATC_FrModFloorInd "Mode FLOOR button indicator status signal in case ALL Mode Button Type";
CM_ BO_ 905 "[PE] Periodic and On Event";
CM_ SG_ 905 SBCM_RR_Crc1Val "SBCM_RR_CyclicRedundancyCheck1Value";
CM_ SG_ 905 RR_CrashUnlockCmd "Rear Right Crash Unlock Command";
CM_ SG_ 905 SBCM_RR_AlvCnt1Val "SBCM_RR_AliveCounter1Value";
CM_ SG_ 905 Warn_RrRtDrSwSta_SBCM "Warn_RearRightDoorSwitchStatus ##2G## -  - C_RRDrSw,CF_Gway_RRDrSw,Warn_RrRtDrSwSta";
CM_ SG_ 905 DoorLock_RrRtDrUnLkSta_SBCM "DoorLock_RearRightDoorUnLockStatus ##2G## -  - C_RRUnlockState,DoorLock_RrRtDrUnLkSta";
CM_ SG_ 905 RR_SEAActivated "Rear Right SEA Activated";
CM_ SG_ 905 RR_SEAWarn "Rear Righr SEA Warning";
CM_ BO_ 904 "[PE] Periodic and On Event";
CM_ SG_ 904 PSM_EsyAcsGetOffSta "Easy Access Get Off Information";
CM_ SG_ 904 PSM_EsyAcsStpSta "Easy Access Stop Information";
CM_ SG_ 904 PSM_SWVerMajor1 "First Word(ASCII) in PSM S/W Ver";
CM_ SG_ 904 PSM_SWVerMinor1 "Second Word(ASCII) in PSM S/W Ver";
CM_ SG_ 904 PSM_SWVerMinor2 "Third Word(ASCII) in PSM S/W Ver";
CM_ SG_ 904 PSM_HDPSpprtSWVer "Requirement Spec Version about PSM by HDP";
CM_ SG_ 904 PSM_EsyAcsGetOnSta "Easy Access Get On Information";
CM_ BO_ 903 "[PE] Periodic and On Event";
CM_ SG_ 903 PSM_DrvStSldFwdDis "PSM_DriverSlideForwardDisplay";
CM_ SG_ 903 PSM_DrvStTiltDnDis "PSM_DriverTiltDownSwitchDisplay";
CM_ SG_ 903 PSM_DrvStHghtUpDis "PSM_DriverHeightUpSwitchDisplay";
CM_ SG_ 903 PSM_DrvStHghtDnDis "PSM_DriverHeightDownSwitchDisplay";
CM_ SG_ 903 PSM_DrvStCushExtBckwdDis "PSM_DriverCushionExtendedBackwardSwitchDisplay";
CM_ SG_ 903 PSM_DrvStCushExtFwdDis "PSM_DriverCushionExtendedForwardSwitchDisplay";
CM_ SG_ 903 PSM_DrvStSldBckwdDis "PSM_DriverSlideBackwardSwitchDisplay";
CM_ SG_ 903 PSM_DrvStHdRstUpDis "PSM_DriverHeadRestUpSwitchDisplay";
CM_ SG_ 903 PSM_DrvStHdRstDnDis "PSM_DriverHeadRestDownSwitchDisplay";
CM_ SG_ 903 PSM_DrvStHdRstFwdDis "PSM_DriverHeadRestForwardSwitchDisplay";
CM_ SG_ 903 PSM_DrvStHdRstBckwdDis "PSM_DriverHeadRestBackwardSwitchDisplay";
CM_ SG_ 903 PSM_DrvStLmbrDefDis "PSM_DriverLumbarDeFlateSwitchDisplay";
CM_ SG_ 903 PSM_DrvStLmbrLoDis "PSM_DriverLumbarLowSwitchDisplay";
CM_ SG_ 903 PSM_DrvStLmbrMdlDis "PSM_DriverLumbarMiddleSwitchDisplay";
CM_ SG_ 903 PSM_DrvStLmbrUpDis "PSM_DriverLumbarUpSwitchDisplay";
CM_ SG_ 903 PSM_DrvStReclneFwdDis "PSM_DriverSeatReclineForwardSwitchDisplay";
CM_ SG_ 903 PSM_DrvStBlstrDefDis "PSM_DriverBolsterDeflateSwitchDisplay";
CM_ SG_ 903 PSM_DrvStBlstrInfDis "PSM_DriverBolsterInflateSwitchDisplay";
CM_ SG_ 903 PSM_DrvStReclneBckwdDis "PSM_DriverSeatReclineBackwardSwitchDisplay";
CM_ SG_ 903 PSM_DrvStTiltUpDis "PSM_DriverTiltUpSwitchDisplay";
CM_ BO_ 902 "[PE] Periodic and On Event";
CM_ SG_ 902 PSM_DrvStEsyAcsUSMSta "USM_MovingValue";
CM_ SG_ 902 PSM_SeatPosPlyBck_Sta "PSM_SeatPositionPlayBack_State";
CM_ SG_ 902 PSM_SeatPos_Sta "PSM_SeatPosition_State";
CM_ SG_ 902 PSM_SeatPosSldLmt_Sta "PSM_SeatPositionSlideLimitState";
CM_ SG_ 902 PSM_SeatPosRclnLmt_Sta "PSM_SeatPositionReclineLimitState";
CM_ SG_ 902 SmrtIMS_StatureRspVal "HCIMS_HeightRsponseValue";
CM_ SG_ 902 SmrtIMS_SeatedHghtRspVal "HCIMS_SitHeightRsponseValue";
CM_ SG_ 902 SmrtIMS_WghtRspVal "HCIMS_WeightRsponseValue";
CM_ SG_ 902 SmartIMS_DisReq "PSM_MoveStatusDisplay";
CM_ SG_ 902 SmrtIMS_ExitSta "Smart IMS exit condition";
CM_ SG_ 902 PSM_DrvStRlxTiltUpDis "PSM_DriverSeatRelexTiltUpDisplay";
CM_ SG_ 902 PSM_DrvStRlxTiltDnDis "PSM_DriverSeatRelexTiltDownDisplay";
CM_ SG_ 902 PSM_DrvStLegUpDis "PSM_DriverSeatLegUpDisplay";
CM_ SG_ 902 PSM_DrvStLegDnDis "PSM_DriverSeatLegDownDisplay";
CM_ SG_ 902 PSM_IMSOptTyp "Option flag for IMS system";
CM_ BO_ 1993 "[TP] Transport Protocol";
CM_ BO_ 1016 "[P] Periodic";
CM_ SG_ 1016 GNSS_MM_type "Map matching type info.";
CM_ BO_ 1019 "[EC] On Event and On Change";
CM_ SG_ 1019 HU_MoodTherapyDrSeat "Moodtherapy Driver Seat On/Off";
CM_ SG_ 1019 HU_VitalityFragrance "Vitality Fragrance On/Off";
CM_ SG_ 1019 HU_VitalityCurtain "Vitality Curtain On/Off";
CM_ SG_ 1019 HU_DelightMoodLamp "Delight MoodLamp On/Off";
CM_ SG_ 1019 HU_DelightFragrance "Delight Fragrance On/Off";
CM_ SG_ 1019 HU_DelightCurtain "Delight Curtain On/Off";
CM_ SG_ 1019 HU_MoodTherapyPsSeat "Moodtherapy Passenger Seat On/Off";
CM_ SG_ 1019 HU_CareMoodLamp "Care MoodLamp On/Off";
CM_ SG_ 1019 HU_CareFragrance "Care Fragrance On/Off";
CM_ SG_ 1019 HU_CareMassage "Care Massage On/Off";
CM_ SG_ 1019 HU_CareCurtain "Care Curtain On/Off";
CM_ SG_ 1019 HU_ComfortMoodLamp "Comfort MoodLamp On/Off";
CM_ SG_ 1019 HU_ComfortFragrance "Comfort Fragrance On/Off";
CM_ SG_ 1019 HU_ComfortMassage "Comfort Massage On/Off";
CM_ SG_ 1019 HU_ComfortCurtain "Comfort Curtain On/Off";
CM_ SG_ 1019 HU_MoodTherapyMode "Moodtherapy Mode Change Signal";
CM_ SG_ 1019 HU_MoodTherapyRlSeat "Moodtherapy RearLeft Seat On/Off";
CM_ SG_ 1019 HU_MoodTherapyRrSeat "Moodtherapy Rear Right Seat On/Off";
CM_ SG_ 1019 HU_VitalityMoodLamp "Vitality MoodLamp On/Off";
CM_ BO_ 2235651330 "[P] Periodic";
CM_ BO_ 2235651329 "[P] Periodic";
CM_ SG_ 2235651329 APSB_Crc1Val "APSB_CyclicRedundancyCheck1Value";
CM_ SG_ 2235651329 APSB_AlvCnt1Val "APSB_AliveCounter1Value";
CM_ SG_ 2235651329 APSB_ConfTbl "APSB_ConfigurationTable";
CM_ SG_ 2235651329 APSB_CrashActvSta "APSB_CrashActiveStatus";
CM_ SG_ 2235651329 APSB_RRDrvImpt "APSB RoughRoadDrvingImpact";
CM_ SG_ 2235651329 APSB_FCAFrImpt "APSB FCAFrontImpact";
CM_ SG_ 2235651329 APSB_MinFrImpt "APSB MinorFrontImpact";
CM_ SG_ 2235651329 APSB_MinSidImpt "APSB MinorSideImpact";
CM_ SG_ 2235651329 APSB_MinRollDetn "APSB MinorRollDetection";
CM_ SG_ 2235651329 APSB_MinRearImpt "APSB MinorRearImpact";
CM_ BO_ 1015 "[P] Periodic";
CM_ SG_ 1015 HU_MM_Altitude "Mapmatching Altitude";
CM_ SG_ 1015 HU_MM_Heading "Map matching heading";
CM_ BO_ 1956 "[TP] Transport Protocol";
CM_ BO_ 1959 "[TP] Transport Protocol";
CM_ BO_ 1003 "[PE] Periodic and On Event";
CM_ SG_ 1003 PSM_BzrOnRLReq "PSM_BuzzerOnRLRequest";
CM_ SG_ 1003 RLPSM_RLStEsyAcsUSMSta "RLPSM_USM_MovingValue";
CM_ SG_ 1003 RLPSM_SeatPos_Sta "RLPSM_SeatPosition_State";
CM_ SG_ 1003 RLPSM_SeatPosSldLmt_Sta "RLPSM_SeatPositionSlideLimitState";
CM_ SG_ 1003 RLPSM_LimSetSta "RLPSM limit setting state";
CM_ BO_ 1002 "[PE] Periodic and On Event";
CM_ SG_ 1002 BLTN_CAM_HU_UI_Mode "Display control of Built-in Cam UI mode. This Signal for Ethernet Type Built-in Cam.";
CM_ SG_ 1002 BLTN_CAM_SD_Format_Op_State "BLTN_CAM SD card format operation status.";
CM_ SG_ 1002 BLTN_CAM_PEV_Recorded "This Signal is sent just after the park event recorded.";
CM_ SG_ 1002 BLTN_CAM_PEV_Count "This Signal is count of park event record.";
CM_ SG_ 1002 BLTN_CAM_Ind_Req "This Signal is for HU Display Built-in Cam Indicator.";
CM_ SG_ 1002 BLTN_CAM_LVDS_Mode_State "This Signal is for LVDS output status";
CM_ SG_ 1002 BLTN_CAM_PrkOp_Termiate_Info "0x0:Default/0x01: Park operation terminated earlier than user set because of Bat. SoC/0x2 : Park operation terminated earlier than user set because of SD Card Problem /0x3 : Park operation terminated earlier than user set because of Built-in Cam internal Error /0x04~0x6:Reserved/0x07 : Park operation terminate on time which user se";
CM_ SG_ 1002 BLTN_CAM_Display "Display control of Built-in Cam UI mode. This Signal for CAN Type Built-in Cam.(with Standard 5th Wide AVNT)";
CM_ SG_ 1002 BLTN_CAM_WiFi_State "BLTN_CAM WiFi Stattus";
CM_ BO_ 1005 "[PE] Periodic and On Event";
CM_ SG_ 1005 RLPSU_FldDis "2nd Left side seat moving state  : Folding";
CM_ SG_ 1005 RLPSU_TiltDownDis "2nd Left side seat moving state  : Tilt down";
CM_ SG_ 1005 RLPSU_RclFwdDis "2nd Left side seat moving state  : Recline Forward";
CM_ SG_ 1005 RLPSU_RclBwdDis "2nd Left side seat moving state  : Recline Backward";
CM_ SG_ 1005 RLPSU_RlxModeDis "2nd Left side seat moving state  : Relax mode";
CM_ SG_ 1005 RLPSU_Folding_SW "Interlocking signal between DPSM and RLPSU";
CM_ SG_ 1005 RLPSU_UnFldDis "2nd Left side seat moving state  : UnFolding";
CM_ SG_ 1005 RLPSU_Unfolding_SW "Interlocking signal between DPSM and RLPSU";
CM_ SG_ 1005 RLPSU_WalkIn_SW "Interlocking signal between DPSM and RLPSU";
CM_ SG_ 1005 RLPSU_UnwalkIn_SW "Interlocking signal between DPSM and RLPSU";
CM_ SG_ 1005 RLPSU_Folding_Postion "RLPSU Position Information";
CM_ SG_ 1005 RLPSU_Folding_State_PopUp "Rear LH seat Folding State information";
CM_ SG_ 1005 RLPSU_Relax_State_Popup "Rear LH seat Relax State information";
CM_ SG_ 1005 RLPSU_SlideFwdDis "2nd Left side seat moving state  : Slide Forward";
CM_ SG_ 1005 RLPSU_SlideBwdDis "2nd Left side seat moving state  : Slide Backward";
CM_ SG_ 1005 RLPSU_WalkInDis "2nd Left side seat moving state : Walk In";
CM_ SG_ 1005 RLPSU_WalkInState "2nd Left side seat Walk-in Ready state";
CM_ SG_ 1005 RLPSU_UnWalkInDis "2nd Left side seat moving state : Un Walk In";
CM_ SG_ 1005 RLPSU_TiltUpDis "2nd Left side seat moving state  : Tilt up";
CM_ BO_ 1004 "[PE] Periodic and On Event";
CM_ SG_ 1004 CF_RCS_SwTyp "RCS type";
CM_ SG_ 1004 CF_RCS_OffRoad "OffRoad mode";
CM_ SG_ 1004 CF_RCS_BtnSta "RCS Button Status";
CM_ SG_ 1004 CF_RCS_RotateEnd "signal to inform end of rotate";
CM_ SG_ 1004 CF_RCS_4wdLocking "4wd locking on/off signal";
CM_ SG_ 1004 RCS_Direction_SW "RCS_Direction_SW";
CM_ SG_ 1004 CF_RCS_DrvMod "Drive mode select";
CM_ SG_ 1004 RCS_Mode_SW "RCS_Mode_SW";
CM_ BO_ 1955 "[TP] Transport Protocol";
CM_ BO_ 1007 "[EC] On Event and On Change";
CM_ SG_ 1007 ATS_LEDBgtnsUpDn "Interior Light Brightness Up/Down Request";
CM_ SG_ 1007 ATS_FrMoodOn_Req "Front mood lamp On/Off request";
CM_ SG_ 1007 ATS_DoorOn_Req "Front Door switch On/Off request";
CM_ SG_ 1007 ATS_RrMapLftOn_Req "Rear left map lamp On/Off request";
CM_ SG_ 1007 ATS_RrMapRtOn_Req "Rear right map lamp On/Off request";
CM_ SG_ 1007 ATS_RrRoomOn_Req "Rear room lamp On/Off request";
CM_ SG_ 1007 ATS_LEDClrUpDn "Interior Light Color Up/Down Request";
CM_ SG_ 1007 ATS_RrMoodOn_Req "Rear mood lamp On/Off request";
CM_ SG_ 1007 ATS_LEDClr_Set "Interior Lamp LED Color Request";
CM_ SG_ 1007 ATS_LEDBgtns_Set "Interior Lamp LED Brightness Request";
CM_ SG_ 1007 ATS_LEDClrUpDnBtn "Interior Light Color Up/Down Request";
CM_ SG_ 1007 ATS_LEDBgtnsUpDnBtn "Interior Light Brightness Up/Down Request";
CM_ SG_ 1007 ATS_FrMapLftOn_Req "Front left map lamp On/Off request";
CM_ SG_ 1007 ATS_FrMapRtOn_Req "Front right map lamp On/Off request";
CM_ SG_ 1007 ATS_FrRoomOn_Req "Front room lamp On/Off request";
CM_ BO_ 1006 "[PE] Periodic and On Event";
CM_ SG_ 1006 RRPSU_FldDis "2nd Right side seat moving state  : Folding";
CM_ SG_ 1006 RRPSU_TiltDnDis "2nd Right side seat moving state  : Tilt down";
CM_ SG_ 1006 RRPSU_RecFwdDis "2nd Right side seat moving state  : Recline Forward";
CM_ SG_ 1006 RRPSU_RecBwdDis "2nd Right side seat moving state  : Recline Backward";
CM_ SG_ 1006 RRPSU_RlxModeDis "2nd Right side seat moving state  : Relax mode";
CM_ SG_ 1006 RRPSU_Folding_SW "Interlocking signal between DPSM and RRPSU";
CM_ SG_ 1006 RRPSU_UnFldDis "2nd Right side seat moving state  : UnFolding";
CM_ SG_ 1006 RRPSU_Unfolding_SW "Interlocking signal between DPSM and RRPSU";
CM_ SG_ 1006 RRPSU_WalkIn_SW "Interlocking signal between DPSM and RRPSU";
CM_ SG_ 1006 RRPSU_UnwalkIn_SW "Interlocking signal between DPSM and RRPSU";
CM_ SG_ 1006 RRPSU_Folding_Postion "RRPSU Position Information";
CM_ SG_ 1006 RRPSU_Folding_State_Popup "Rear RH seat Folding State information";
CM_ SG_ 1006 RRPSU_Relax_State_Popup "Rear RH seat Relax State information";
CM_ SG_ 1006 RRPSU_SlideFwdDis "2nd Right side seat moving state  : Slide Forward";
CM_ SG_ 1006 RRPSU_SlideBwdDis "2nd Right side seat moving state  : Slide Backward";
CM_ SG_ 1006 RRPSU_WalkinDis "2nd Right side seat moving state : Walk In";
CM_ SG_ 1006 RRPSU_WalkInState "2nd Right side seat Walk-in Ready state";
CM_ SG_ 1006 RRPSU_UnwalkinDis "2nd Right side seat moving state : Un Walk In";
CM_ SG_ 1006 RRPSU_TiltUpDis "2nd Right side seat moving state  : Tilt up";
CM_ BO_ 2353206529 "[P] Periodic";
CM_ SG_ 2353206529 CLU_Crc20Val "CLU_CyclicRedundancyCheck20Value";
CM_ SG_ 2353206529 CLU_AlvCnt20Val "CLU_AliveCounter20Value";
CM_ SG_ 2353206529 CLU_SndType "CLU_SoundType";
CM_ BO_ 992 "[PE] Periodic and On Event";
CM_ SG_ 992 BCM_Crc2Val "BCM_CyclicRedundancyCheck2Value";
CM_ SG_ 992 BCM_AlvCnt2Val "BCM_AliveCounter2Value";
CM_ SG_ 992 BAlarm_BglrAlrmCurrentSta "BAlarm_BuglarAlarmCurrentStatus ##2G##BCM - BCMmsg17 - C_BAlarmState";
CM_ SG_ 992 BAlarm_BglrAlrmSta "BAlarm_BuglarAlarmStatus ##2G##BCM - BCMmsg17 - C_BAState";
CM_ SG_ 992 BAlarm_PncAlrmSta "BAlarm_PanicAlarmStatus ##2G##BCM - BCMmsg17 - C_PanicState";
CM_ SG_ 992 BAlarm_StrtInhbtRlySta "BAlarm_StartInhibitRelayStatus ##2G##BCM - BCMmsg19 - C_StartINHRly";
CM_ SG_ 992 BAlarm_BrglrHrnRlySta "BAlarm_BurglarHornRelayStatus ##2G##BCM - BCMmsg19 - C_BurglarHornRly";
CM_ SG_ 992 BCM_KeyInSta "BCM_KeyInStatus ##2G##BCM - BCMmsg17 - C_KeyInSW";
CM_ SG_ 992 BCM_AccInSta "BCM_AccInputStatus ##2G##BCM - BCMmsg17 - C_Acc";
CM_ SG_ 992 BCM_Ign1InSta "BCM_Ignition1InputStatus ##2G##BCM - BCMmsg17 - C_Ign1";
CM_ SG_ 992 BCM_Ign2InSta "BCM_Ignition1InputStatus ##2G##BCM - BCMmsg17 - C_Ign2";
CM_ BO_ 1964 "[TP] Transport Protocol";
CM_ BO_ 1967 "[TP] Transport Protocol";
CM_ BO_ 2353206530 "[P] Periodic";
CM_ BO_ 994 "[PE] Periodic and On Event";
CM_ SG_ 994 BCM_Crc4Val "BCM_CyclicRedundancyCheck4Value";
CM_ SG_ 994 BCM_AlvCnt4Val "BCM_AliveCounter4Value";
CM_ SG_ 994 Warn_BzrWrngSta "Warn_BuzzerWarningStatus ##2G##BCM - BCMmsg18 - C_WngBuz";
CM_ SG_ 994 Warn_BCMWrngSta "Warn_BCMWarningStatus ##2G##BCM - BCMmsg19 - C_BCMWarning";
CM_ SG_ 994 ROA_RegionOpt "A Euro NCAP Option signal (BDC only)";
CM_ SG_ 994 Warn_RrStRmndOpt "Warn_RearSeatReminderOption ##2G##BCM - BCMmsg22 - C_RrSeatRemindOpt";
CM_ SG_ 994 Warn_RrStRmndAlrmOnReq "Warn_RearSeatReminderAlarmOnRequest ##2G##BCM - BCMmsg22 - C_RrSeatRemindAlarm";
CM_ SG_ 994 Warn_RrStRmndSysSta "Warn_RearSeatReminderSystemStatus ##2G##BCM - BCMmsg22 - C_RrSeatRemindState";
CM_ SG_ 994 Warn_RrStRmndAlrmInfo "Warn_RearSeatReminderAlarmInformaion ##2G##BCM - BCMmsg22 - C_RrSeatRemindInfo";
CM_ SG_ 994 Warn_RoaErr "Warn_RoaError##2G##BCM - BCMmsg22 - C_RoaError";
CM_ SG_ 994 WAL_FobSearching "IBU Walk Away Lock Fob Searching State for Radar ROA";
CM_ SG_ 994 Warn_RrStRmndDelay "Warn_RStRmndDelay";
CM_ SG_ 994 Warn_RrStRmndSysAct "Warn_RrStRmndSysAct";
CM_ SG_ 994 Warn_RrStRmndSysOffIND "Warning_RearSeatRemindSystemOffIND";
BA_DEF_ BO_  "DiagState" ENUM  "No","Yes";
BA_DEF_ BO_  "DiagResponse" ENUM  "No","Yes";
BA_DEF_ BO_  "DiagRequest" ENUM  "No","Yes";
BA_DEF_ BO_  "TpMessage" ENUM  "No","Yes";
BA_DEF_ BO_  "UsrMsgIDSforwardDeviation" INT 0 100;
BA_DEF_ BO_  "UsrMsgIDSbackwardDeviation" INT 50 1000;
BA_DEF_ BO_  "GenMsgCycleTime" INT 0 2000;
BA_DEF_ BO_  "GenMsgStartDelayTime" INT 0 2000;
BA_DEF_ BO_  "GenMsgSendType" ENUM  "Cyclic","NoMsgSendType";
BA_DEF_ BO_  "GenMsgCycleTimeFast" INT 0 500;
BA_DEF_ BO_  "GenMsgDelayTime" INT 0 20;
BA_DEF_ BO_  "GenMsgILSupport" ENUM  "No","Yes";
BA_DEF_ BO_  "GenMsgNrOfRepetition" INT 0 3;
BA_DEF_ BO_  "NmMessage" ENUM  "No","Yes";
BA_DEF_ BO_  "NWM-Botschaft" ENUM  "No","Yes";
BA_DEF_ BO_  "TpTxIndex" INT 0 65535;
BA_DEF_ BO_  "VFrameFormat" ENUM  "StandardCAN","ExtendedCAN","reserved","reserved","reserved","reserved","reserved","reserved","reserved","reserved","reserved","reserved","reserved","reserved","StandardCAN_FD","ExtendedCAN_FD";
BA_DEF_ SG_  "UserSigValidity" ENUM  "B+","ACC","IG","IG1","IG2","IG3","IG1 or IG2","IG1 or IG3","Undef";
BA_DEF_ SG_  "TimeoutValue" STRING ;
BA_DEF_ SG_  "UsrSigPurpose" ENUM  "Undef","FN","DIAG","DIAG(Req)","DIAG(Res)","DIAG(Phy)","DEV","CCP(Req)","CCP(Res)","NM","TP";
BA_DEF_ SG_  "GenSigStartValue" INT 0 1215752192;
BA_DEF_ SG_  "NetworkRequest" ENUM  "Yes","No";
BA_DEF_ SG_  "NetworkRequestHoldingTime" INT 0 65535;
BA_DEF_ SG_  "Description" STRING ;
BA_DEF_ SG_  "Version" STRING ;
BA_DEF_ SG_  "GenSigEnvVarType" ENUM  "Int","Float","Undef";
BA_DEF_ SG_  "GenSigSendType" ENUM  "Cyclic","OnWrite","OnWriteWithRepetition","OnChange","OnChangeWithRepetition","IfActive","IfActiveWithRepetition","NoSigSendType","OnChangeAndIfActive","OnChangeAndIfActiveWithRepetition";
BA_DEF_ SG_  "GwSigLatencyTime" INT 0 65536;
BA_DEF_ SG_  "GwSigMissingSourceType" ENUM  "Undef","OldValue","DefaultValue","InitialValue";
BA_DEF_ SG_  "NWM-WakeupAllowed" ENUM  "<n.a.>";
BA_DEF_ SG_  "RoutingFactor" INT 1 1215752192;
BA_DEF_ SG_  "SystemSignalLongSymbol" STRING ;
BA_DEF_REL_ BU_SG_REL_  "GenSigTimeoutTime" INT 0 7000;
BA_DEF_DEF_  "DiagState" "No";
BA_DEF_DEF_  "DiagResponse" "No";
BA_DEF_DEF_  "DiagRequest" "No";
BA_DEF_DEF_  "TpMessage" "No";
BA_DEF_DEF_  "UsrMsgIDSforwardDeviation" 10;
BA_DEF_DEF_  "UsrMsgIDSbackwardDeviation" 100;
BA_DEF_DEF_  "GenMsgCycleTime" 200;
BA_DEF_DEF_  "GenMsgStartDelayTime" 0;
BA_DEF_DEF_  "GenMsgSendType" "NoMsgSendType";
BA_DEF_DEF_  "GenMsgCycleTimeFast" 40;
BA_DEF_DEF_  "GenMsgDelayTime" 20;
BA_DEF_DEF_  "GenMsgILSupport" "Yes";
BA_DEF_DEF_  "GenMsgNrOfRepetition" 3;
BA_DEF_DEF_  "NmMessage" "No";
BA_DEF_DEF_  "NWM-Botschaft" "No";
BA_DEF_DEF_  "TpTxIndex" 0;
BA_DEF_DEF_  "VFrameFormat" "StandardCAN";
BA_DEF_DEF_  "UserSigValidity" "IG";
BA_DEF_DEF_  "TimeoutValue" "";
BA_DEF_DEF_  "UsrSigPurpose" "FN";
BA_DEF_DEF_  "GenSigStartValue" 0;
BA_DEF_DEF_  "NetworkRequest" "No";
BA_DEF_DEF_  "NetworkRequestHoldingTime" 0;
BA_DEF_DEF_  "Description" "";
BA_DEF_DEF_  "Version" "";
BA_DEF_DEF_  "GenSigEnvVarType" "Undef";
BA_DEF_DEF_  "GenSigSendType" "NoSigSendType";
BA_DEF_DEF_  "GwSigLatencyTime" 40;
BA_DEF_DEF_  "GwSigMissingSourceType" "Undef";
BA_DEF_DEF_  "NWM-WakeupAllowed" "<n.a.>";
BA_DEF_DEF_  "RoutingFactor" 1;
BA_DEF_DEF_REL_ "GenSigTimeoutTime" 500;
BA_DEF_DEF_  "SystemSignalLongSymbol" "";
BA_ "GenMsgSendType" BO_ 913 0;
BA_ "GenMsgCycleTime" BO_ 911 0;
BA_ "GenMsgCycleTime" BO_ 1985 0;
BA_ "GenMsgCycleTimeFast" BO_ 1985 0;
BA_ "GenMsgNrOfRepetition" BO_ 1985 0;
BA_ "DiagRequest" BO_ 1985 1;
BA_ "GenMsgILSupport" BO_ 1985 0;
BA_ "TpMessage" BO_ 1985 1;
BA_ "TpTxIndex" BO_ 1985 154;
BA_ "GenMsgSendType" BO_ 2382594817 0;
BA_ "VFrameFormat" BO_ 2382594817 1;
BA_ "GenMsgSendType" BO_ 905 0;
BA_ "GenMsgSendType" BO_ 904 0;
BA_ "GenMsgSendType" BO_ 903 0;
BA_ "GenMsgSendType" BO_ 902 0;
BA_ "GenMsgCycleTime" BO_ 1993 0;
BA_ "GenMsgCycleTimeFast" BO_ 1993 0;
BA_ "GenMsgNrOfRepetition" BO_ 1993 0;
BA_ "DiagResponse" BO_ 1993 1;
BA_ "GenMsgILSupport" BO_ 1993 0;
BA_ "TpMessage" BO_ 1993 1;
BA_ "TpTxIndex" BO_ 1993 154;
BA_ "GenMsgSendType" BO_ 1016 0;
BA_ "GenMsgCycleTime" BO_ 1016 1000;
BA_ "GenMsgCycleTimeFast" BO_ 1016 0;
BA_ "GenMsgNrOfRepetition" BO_ 1016 0;
BA_ "GenMsgCycleTime" BO_ 1019 0;
BA_ "GenMsgSendType" BO_ 2235651330 0;
BA_ "GenMsgCycleTime" BO_ 2235651330 10;
BA_ "GenMsgCycleTimeFast" BO_ 2235651330 0;
BA_ "GenMsgNrOfRepetition" BO_ 2235651330 0;
BA_ "GenMsgDelayTime" BO_ 2235651330 0;
BA_ "VFrameFormat" BO_ 2235651330 1;
BA_ "GenMsgSendType" BO_ 2235651329 0;
BA_ "GenMsgCycleTime" BO_ 2235651329 10;
BA_ "GenMsgCycleTimeFast" BO_ 2235651329 0;
BA_ "GenMsgNrOfRepetition" BO_ 2235651329 0;
BA_ "GenMsgDelayTime" BO_ 2235651329 0;
BA_ "VFrameFormat" BO_ 2235651329 1;
BA_ "GenMsgSendType" BO_ 1015 0;
BA_ "GenMsgCycleTime" BO_ 1015 1000;
BA_ "GenMsgCycleTimeFast" BO_ 1015 0;
BA_ "GenMsgNrOfRepetition" BO_ 1015 0;
BA_ "GenMsgCycleTime" BO_ 1956 0;
BA_ "GenMsgCycleTimeFast" BO_ 1956 0;
BA_ "GenMsgNrOfRepetition" BO_ 1956 0;
BA_ "DiagRequest" BO_ 1956 1;
BA_ "GenMsgILSupport" BO_ 1956 0;
BA_ "TpMessage" BO_ 1956 1;
BA_ "TpTxIndex" BO_ 1956 172;
BA_ "GenMsgCycleTime" BO_ 1959 0;
BA_ "GenMsgCycleTimeFast" BO_ 1959 0;
BA_ "GenMsgNrOfRepetition" BO_ 1959 0;
BA_ "DiagRequest" BO_ 1959 1;
BA_ "GenMsgILSupport" BO_ 1959 0;
BA_ "TpMessage" BO_ 1959 1;
BA_ "TpTxIndex" BO_ 1959 175;
BA_ "GenMsgSendType" BO_ 1003 0;
BA_ "GenMsgSendType" BO_ 1002 0;
BA_ "GenMsgSendType" BO_ 1005 0;
BA_ "GenMsgSendType" BO_ 1004 0;
BA_ "GenMsgCycleTime" BO_ 1955 0;
BA_ "GenMsgCycleTimeFast" BO_ 1955 0;
BA_ "GenMsgNrOfRepetition" BO_ 1955 0;
BA_ "DiagRequest" BO_ 1955 1;
BA_ "GenMsgILSupport" BO_ 1955 0;
BA_ "TpMessage" BO_ 1955 1;
BA_ "TpTxIndex" BO_ 1955 156;
BA_ "GenMsgCycleTime" BO_ 1007 0;
BA_ "GenMsgSendType" BO_ 1006 0;
BA_ "GenMsgSendType" BO_ 2353206529 0;
BA_ "GenMsgCycleTimeFast" BO_ 2353206529 0;
BA_ "GenMsgNrOfRepetition" BO_ 2353206529 0;
BA_ "VFrameFormat" BO_ 2353206529 1;
BA_ "GenMsgSendType" BO_ 992 0;
BA_ "GenMsgCycleTime" BO_ 1964 0;
BA_ "GenMsgCycleTimeFast" BO_ 1964 0;
BA_ "GenMsgNrOfRepetition" BO_ 1964 0;
BA_ "DiagResponse" BO_ 1964 1;
BA_ "GenMsgILSupport" BO_ 1964 0;
BA_ "TpMessage" BO_ 1964 1;
BA_ "TpTxIndex" BO_ 1964 172;
BA_ "GenMsgCycleTime" BO_ 1967 0;
BA_ "GenMsgCycleTimeFast" BO_ 1967 0;
BA_ "GenMsgNrOfRepetition" BO_ 1967 0;
BA_ "DiagResponse" BO_ 1967 1;
BA_ "GenMsgILSupport" BO_ 1967 0;
BA_ "TpMessage" BO_ 1967 1;
BA_ "TpTxIndex" BO_ 1967 175;
BA_ "GenMsgSendType" BO_ 2353206530 0;
BA_ "GenMsgCycleTimeFast" BO_ 2353206530 0;
BA_ "GenMsgNrOfRepetition" BO_ 2353206530 0;
BA_ "VFrameFormat" BO_ 2353206530 1;
BA_ "GenMsgSendType" BO_ 994 0;
BA_ "Description" SG_ 913 PSD_Crc2Val "The data area for CRC calculation is based on the data length (DLC) of the message DB.

The CRC shall be calculated over the entire data block (excluding the CRC bytes) including the user data, alive counter and Data ID 

 

- CRC Polynomial (0x1D) , Ini";
BA_ "GenSigSendType" SG_ 913 PSD_Crc2Val 4;
BA_ "GenSigStartValue" SG_ 913 PSD_Crc2Val 255;
BA_ "UserSigValidity" SG_ 913 PSD_Crc2Val 0;
BA_ "NetworkRequest" SG_ 913 PSD_Crc2Val 0;
BA_ "NetworkRequestHoldingTime" SG_ 913 PSD_Crc2Val 5000;
BA_ "Version" SG_ 913 PSD_Crc2Val "19.01.09";
BA_ "Description" SG_ 913 PSD_AlvCnt2Val "For the first transmission request for a data element the counter shall be initialized with 0 and shall be incremented by 1

for every subsequent send request. When the counter reaches the maximum value(0xE), then it shall restart with 0 for the next sen";
BA_ "GenSigSendType" SG_ 913 PSD_AlvCnt2Val 4;
BA_ "UserSigValidity" SG_ 913 PSD_AlvCnt2Val 0;
BA_ "NetworkRequest" SG_ 913 PSD_AlvCnt2Val 0;
BA_ "NetworkRequestHoldingTime" SG_ 913 PSD_AlvCnt2Val 5000;
BA_ "Version" SG_ 913 PSD_AlvCnt2Val "19.01.09";
BA_ "Description" SG_ 913 PSD_USMSetSta "PSD USM Setting Signal";
BA_ "GenSigSendType" SG_ 913 PSD_USMSetSta 4;
BA_ "UserSigValidity" SG_ 913 PSD_USMSetSta 3;
BA_ "NetworkRequest" SG_ 913 PSD_USMSetSta 0;
BA_ "NetworkRequestHoldingTime" SG_ 913 PSD_USMSetSta 5000;
BA_ "Version" SG_ 913 PSD_USMSetSta "18.12.07";
BA_ "Description" SG_ 913 Lamp_HzrdSta "- Hazard Flashing when PSD is opening

- Initial Value: 2";
BA_ "GenSigSendType" SG_ 913 Lamp_HzrdSta 4;
BA_ "GenSigStartValue" SG_ 913 Lamp_HzrdSta 2;
BA_ "UserSigValidity" SG_ 913 Lamp_HzrdSta 0;
BA_ "NetworkRequest" SG_ 913 Lamp_HzrdSta 0;
BA_ "NetworkRequestHoldingTime" SG_ 913 Lamp_HzrdSta 5000;
BA_ "Version" SG_ 913 Lamp_HzrdSta "21.07.05";
BA_ "GenSigSendType" SG_ 913 PSD_OptTyp 4;
BA_ "UserSigValidity" SG_ 913 PSD_OptTyp 0;
BA_ "NetworkRequest" SG_ 913 PSD_OptTyp 0;
BA_ "NetworkRequestHoldingTime" SG_ 913 PSD_OptTyp 5000;
BA_ "Version" SG_ 913 PSD_OptTyp "21.07.05";
BA_ "Description" SG_ 913 PSD_LHSEAActivated "LH SEA Activation State";
BA_ "GenSigSendType" SG_ 913 PSD_LHSEAActivated 4;
BA_ "UserSigValidity" SG_ 913 PSD_LHSEAActivated 0;
BA_ "NetworkRequest" SG_ 913 PSD_LHSEAActivated 0;
BA_ "NetworkRequestHoldingTime" SG_ 913 PSD_LHSEAActivated 5000;
BA_ "Version" SG_ 913 PSD_LHSEAActivated "19.01.08";
BA_ "Description" SG_ 913 PSD_RHSEAActivated "RH SEA Activation State";
BA_ "GenSigSendType" SG_ 913 PSD_RHSEAActivated 4;
BA_ "UserSigValidity" SG_ 913 PSD_RHSEAActivated 0;
BA_ "NetworkRequest" SG_ 913 PSD_RHSEAActivated 0;
BA_ "NetworkRequestHoldingTime" SG_ 913 PSD_RHSEAActivated 5000;
BA_ "Version" SG_ 913 PSD_RHSEAActivated "19.01.08";
BA_ "Description" SG_ 913 PSD_LHPSDLatchState "LH PSD LatchState

- 0x0 : Close status

- 0x1~0x4 : Open status

- 0x5 : Unknown status

- 0x6 : Error status";
BA_ "GenSigSendType" SG_ 913 PSD_LHPSDLatchState 4;
BA_ "GenSigStartValue" SG_ 913 PSD_LHPSDLatchState 5;
BA_ "UserSigValidity" SG_ 913 PSD_LHPSDLatchState 0;
BA_ "NetworkRequest" SG_ 913 PSD_LHPSDLatchState 0;
BA_ "NetworkRequestHoldingTime" SG_ 913 PSD_LHPSDLatchState 5000;
BA_ "Version" SG_ 913 PSD_LHPSDLatchState "21.07.05";
BA_ "Description" SG_ 913 PSD_RHPSDLatchState "RH PSD Latch state

- 0x0 : Close status

- 0x1~0x4 : Open status

- 0x5 : Unknown status

- 0x6 : Error status";
BA_ "GenSigSendType" SG_ 913 PSD_RHPSDLatchState 4;
BA_ "GenSigStartValue" SG_ 913 PSD_RHPSDLatchState 5;
BA_ "UserSigValidity" SG_ 913 PSD_RHPSDLatchState 0;
BA_ "NetworkRequest" SG_ 913 PSD_RHPSDLatchState 0;
BA_ "NetworkRequestHoldingTime" SG_ 913 PSD_RHPSDLatchState 5000;
BA_ "Version" SG_ 913 PSD_RHPSDLatchState "21.07.05";
BA_ "Description" SG_ 913 C_PSDOptLHRH "PSD LH/RH Option";
BA_ "GenSigSendType" SG_ 913 C_PSDOptLHRH 4;
BA_ "UserSigValidity" SG_ 913 C_PSDOptLHRH 0;
BA_ "Version" SG_ 913 C_PSDOptLHRH "21.07.05";
BA_ "Description" SG_ 913 PSD_AllDrOpnSetRValue "All Door(PSD PTG) Open Function by FOB Unlock Long Key USM Setting Signal

0x0 : Not Display in USM

0x1 : All Door Open Function Off

0x2 : Only PSD Open by FOB Unlock Long Key

0x3 : PSD and PTG Open by FOB Unlock Long Key

0x4~0x6 : Reserved

0x7 : Gr";
BA_ "GenSigSendType" SG_ 913 PSD_AllDrOpnSetRValue 4;
BA_ "UserSigValidity" SG_ 913 PSD_AllDrOpnSetRValue 0;
BA_ "NetworkRequest" SG_ 913 PSD_AllDrOpnSetRValue 0;
BA_ "NetworkRequestHoldingTime" SG_ 913 PSD_AllDrOpnSetRValue 5000;
BA_ "Version" SG_ 913 PSD_AllDrOpnSetRValue "21.07.05";
BA_ "Description" SG_ 913 PSD_USMAllDrOpenSet "All Door Open Function by FOB Unlock Long Key Setting Signal for PTG by PSD";
BA_ "GenSigSendType" SG_ 913 PSD_USMAllDrOpenSet 4;
BA_ "UserSigValidity" SG_ 913 PSD_USMAllDrOpenSet 0;
BA_ "NetworkRequest" SG_ 913 PSD_USMAllDrOpenSet 0;
BA_ "NetworkRequestHoldingTime" SG_ 913 PSD_USMAllDrOpenSet 5000;
BA_ "Version" SG_ 913 PSD_USMAllDrOpenSet "19.11.05";
BA_ "Description" SG_ 913 PSD_ModSta "PSD Moudule Status";
BA_ "GenSigSendType" SG_ 913 PSD_ModSta 4;
BA_ "UserSigValidity" SG_ 913 PSD_ModSta 0;
BA_ "NetworkRequest" SG_ 913 PSD_ModSta 0;
BA_ "NetworkRequestHoldingTime" SG_ 913 PSD_ModSta 5000;
BA_ "Version" SG_ 913 PSD_ModSta "21.07.05";
BA_ "Description" SG_ 913 PSD_AutoWashModeSta "PSD Auto Wash Mode Status";
BA_ "GenSigSendType" SG_ 913 PSD_AutoWashModeSta 4;
BA_ "TimeoutValue" SG_ 913 PSD_AutoWashModeSta "0x0";
BA_ "UserSigValidity" SG_ 913 PSD_AutoWashModeSta 0;
BA_ "Version" SG_ 913 PSD_AutoWashModeSta "22.01.03";
BA_ "Description" SG_ 911 ATS_RearLock_Set "RRC and RSE Lock Touch Button";
BA_ "GenSigSendType" SG_ 911 ATS_RearLock_Set 4;
BA_ "GenSigStartValue" SG_ 911 ATS_RearLock_Set 3;
BA_ "UserSigValidity" SG_ 911 ATS_RearLock_Set 3;
BA_ "NetworkRequest" SG_ 911 ATS_RearLock_Set 0;
BA_ "NetworkRequestHoldingTime" SG_ 911 ATS_RearLock_Set 5000;
BA_ "Version" SG_ 911 ATS_RearLock_Set "20.07.08";
BA_ "Description" SG_ 911 ATS_RrCurtainBtn "Rear Curtain Touch Button";
BA_ "GenSigSendType" SG_ 911 ATS_RrCurtainBtn 4;
BA_ "UserSigValidity" SG_ 911 ATS_RrCurtainBtn 3;
BA_ "NetworkRequest" SG_ 911 ATS_RrCurtainBtn 0;
BA_ "NetworkRequestHoldingTime" SG_ 911 ATS_RrCurtainBtn 5000;
BA_ "Version" SG_ 911 ATS_RrCurtainBtn "20.07.05";
BA_ "Description" SG_ 911 ATS_RrDrCurtainBtn "Rear Door and Curtain Touch Button";
BA_ "GenSigSendType" SG_ 911 ATS_RrDrCurtainBtn 4;
BA_ "UserSigValidity" SG_ 911 ATS_RrDrCurtainBtn 3;
BA_ "NetworkRequest" SG_ 911 ATS_RrDrCurtainBtn 0;
BA_ "NetworkRequestHoldingTime" SG_ 911 ATS_RrDrCurtainBtn 5000;
BA_ "Version" SG_ 911 ATS_RrDrCurtainBtn "20.07.05";
BA_ "Description" SG_ 911 ATS_RLDrCurtainBtn "Rear Door and Curtain Touch Button";
BA_ "GenSigSendType" SG_ 911 ATS_RLDrCurtainBtn 4;
BA_ "UserSigValidity" SG_ 911 ATS_RLDrCurtainBtn 3;
BA_ "NetworkRequest" SG_ 911 ATS_RLDrCurtainBtn 0;
BA_ "NetworkRequestHoldingTime" SG_ 911 ATS_RLDrCurtainBtn 5000;
BA_ "Version" SG_ 911 ATS_RLDrCurtainBtn "20.07.05";
BA_ "Description" SG_ 911 ATS_RRSunBlind "SunBlind Touch Botton";
BA_ "GenSigSendType" SG_ 911 ATS_RRSunBlind 4;
BA_ "UserSigValidity" SG_ 911 ATS_RRSunBlind 3;
BA_ "NetworkRequest" SG_ 911 ATS_RRSunBlind 0;
BA_ "NetworkRequestHoldingTime" SG_ 911 ATS_RRSunBlind 5000;
BA_ "Version" SG_ 911 ATS_RRSunBlind "20.07.05";
BA_ "Description" SG_ 911 ATS_FCS_LockTrayIniPwSet "Locking Tray ºñ¹Ð¹øÈ£ ¼³Á¤ ÁøÀÔ ¹öÆ°";
BA_ "GenSigSendType" SG_ 911 ATS_FCS_LockTrayIniPwSet 4;
BA_ "UserSigValidity" SG_ 911 ATS_FCS_LockTrayIniPwSet 3;
BA_ "NetworkRequest" SG_ 911 ATS_FCS_LockTrayIniPwSet 0;
BA_ "NetworkRequestHoldingTime" SG_ 911 ATS_FCS_LockTrayIniPwSet 5000;
BA_ "Version" SG_ 911 ATS_FCS_LockTrayIniPwSet "21.01.02";
BA_ "Description" SG_ 911 ATS_FCS_LockTrayKeyPadNo "Locking Tray ºñ¹Ð¹øÈ£ ¼³Á¤ key Pad ¹öÆ°";
BA_ "GenSigSendType" SG_ 911 ATS_FCS_LockTrayKeyPadNo 4;
BA_ "UserSigValidity" SG_ 911 ATS_FCS_LockTrayKeyPadNo 3;
BA_ "NetworkRequest" SG_ 911 ATS_FCS_LockTrayKeyPadNo 0;
BA_ "NetworkRequestHoldingTime" SG_ 911 ATS_FCS_LockTrayKeyPadNo 5000;
BA_ "Version" SG_ 911 ATS_FCS_LockTrayKeyPadNo "21.01.02";
BA_ "Description" SG_ 911 ATS_FCS_LockTrayNoDel "Locking Tray ºñ¹Ð¹øÈ£ ¼³Á¤ ¼ýÀÚ »èÁ¦ ¹öÆ°";
BA_ "GenSigSendType" SG_ 911 ATS_FCS_LockTrayNoDel 4;
BA_ "UserSigValidity" SG_ 911 ATS_FCS_LockTrayNoDel 3;
BA_ "NetworkRequest" SG_ 911 ATS_FCS_LockTrayNoDel 0;
BA_ "NetworkRequestHoldingTime" SG_ 911 ATS_FCS_LockTrayNoDel 5000;
BA_ "Version" SG_ 911 ATS_FCS_LockTrayNoDel "21.01.02";
BA_ "Description" SG_ 911 ATS_FCS_LockTrayNoClr "Locking Tray ºñ¹Ð¹øÈ£ ¼³Á¤ ¼ýÀÚ Clear ¹öÆ°";
BA_ "GenSigSendType" SG_ 911 ATS_FCS_LockTrayNoClr 4;
BA_ "UserSigValidity" SG_ 911 ATS_FCS_LockTrayNoClr 3;
BA_ "NetworkRequest" SG_ 911 ATS_FCS_LockTrayNoClr 0;
BA_ "NetworkRequestHoldingTime" SG_ 911 ATS_FCS_LockTrayNoClr 5000;
BA_ "Version" SG_ 911 ATS_FCS_LockTrayNoClr "21.01.02";
BA_ "Description" SG_ 911 ATS_FCS_LockTrayPwChange "Locking Tray ºñ¹Ð¹øÈ£ º¯°æ ÁøÀÔ ¹öÆ°";
BA_ "GenSigSendType" SG_ 911 ATS_FCS_LockTrayPwChange 4;
BA_ "UserSigValidity" SG_ 911 ATS_FCS_LockTrayPwChange 3;
BA_ "NetworkRequest" SG_ 911 ATS_FCS_LockTrayPwChange 0;
BA_ "NetworkRequestHoldingTime" SG_ 911 ATS_FCS_LockTrayPwChange 5000;
BA_ "Version" SG_ 911 ATS_FCS_LockTrayPwChange "21.01.02";
BA_ "Description" SG_ 911 ATS_FCS_LockTrayPwReset "Locking Tray ºñ¹Ð¹øÈ£ ÃÊ±âÈ­ ÁøÀÔ ¹öÆ° (ºñ¹Ð¹øÈ£ ¾ø´Â »óÅÂ·Î ¿øº¹)";
BA_ "GenSigSendType" SG_ 911 ATS_FCS_LockTrayPwReset 4;
BA_ "UserSigValidity" SG_ 911 ATS_FCS_LockTrayPwReset 3;
BA_ "NetworkRequest" SG_ 911 ATS_FCS_LockTrayPwReset 0;
BA_ "NetworkRequestHoldingTime" SG_ 911 ATS_FCS_LockTrayPwReset 5000;
BA_ "Version" SG_ 911 ATS_FCS_LockTrayPwReset "21.01.02";
BA_ "Description" SG_ 911 ATS_FCS_LockTrayCancel "Locking Tray ºñ¹Ð¹øÈ£ ÀÔ·Â È­¸é Cancel ¹öÆ°";
BA_ "GenSigSendType" SG_ 911 ATS_FCS_LockTrayCancel 4;
BA_ "UserSigValidity" SG_ 911 ATS_FCS_LockTrayCancel 3;
BA_ "NetworkRequest" SG_ 911 ATS_FCS_LockTrayCancel 0;
BA_ "NetworkRequestHoldingTime" SG_ 911 ATS_FCS_LockTrayCancel 5000;
BA_ "Version" SG_ 911 ATS_FCS_LockTrayCancel "21.01.02";
BA_ "Description" SG_ 1985 GST_PSB_Byte0 "TP Index : 154";
BA_ "UsrSigPurpose" SG_ 1985 GST_PSB_Byte0 3;
BA_ "UserSigValidity" SG_ 1985 GST_PSB_Byte0 0;
BA_ "NetworkRequest" SG_ 1985 GST_PSB_Byte0 0;
BA_ "NetworkRequestHoldingTime" SG_ 1985 GST_PSB_Byte0 5000;
BA_ "Version" SG_ 1985 GST_PSB_Byte0 "21.02.04";
BA_ "Description" SG_ 1985 GST_PSB_Byte2 "TP Index : 154";
BA_ "UsrSigPurpose" SG_ 1985 GST_PSB_Byte2 3;
BA_ "UserSigValidity" SG_ 1985 GST_PSB_Byte2 0;
BA_ "NetworkRequest" SG_ 1985 GST_PSB_Byte2 0;
BA_ "NetworkRequestHoldingTime" SG_ 1985 GST_PSB_Byte2 5000;
BA_ "Version" SG_ 1985 GST_PSB_Byte2 "21.02.04";
BA_ "Description" SG_ 1985 GST_PSB_Byte3 "TP Index : 154";
BA_ "UsrSigPurpose" SG_ 1985 GST_PSB_Byte3 3;
BA_ "UserSigValidity" SG_ 1985 GST_PSB_Byte3 0;
BA_ "NetworkRequest" SG_ 1985 GST_PSB_Byte3 0;
BA_ "NetworkRequestHoldingTime" SG_ 1985 GST_PSB_Byte3 5000;
BA_ "Version" SG_ 1985 GST_PSB_Byte3 "21.02.04";
BA_ "Description" SG_ 1985 GST_PSB_Byte4 "TP Index : 154";
BA_ "UsrSigPurpose" SG_ 1985 GST_PSB_Byte4 3;
BA_ "UserSigValidity" SG_ 1985 GST_PSB_Byte4 0;
BA_ "NetworkRequest" SG_ 1985 GST_PSB_Byte4 0;
BA_ "NetworkRequestHoldingTime" SG_ 1985 GST_PSB_Byte4 5000;
BA_ "Version" SG_ 1985 GST_PSB_Byte4 "21.02.04";
BA_ "Description" SG_ 1985 GST_PSB_Byte5 "TP Index : 154";
BA_ "UsrSigPurpose" SG_ 1985 GST_PSB_Byte5 3;
BA_ "UserSigValidity" SG_ 1985 GST_PSB_Byte5 0;
BA_ "NetworkRequest" SG_ 1985 GST_PSB_Byte5 0;
BA_ "NetworkRequestHoldingTime" SG_ 1985 GST_PSB_Byte5 5000;
BA_ "Version" SG_ 1985 GST_PSB_Byte5 "21.02.04";
BA_ "Description" SG_ 1985 GST_PSB_Byte6 "TP Index : 154";
BA_ "UsrSigPurpose" SG_ 1985 GST_PSB_Byte6 3;
BA_ "UserSigValidity" SG_ 1985 GST_PSB_Byte6 0;
BA_ "NetworkRequest" SG_ 1985 GST_PSB_Byte6 0;
BA_ "NetworkRequestHoldingTime" SG_ 1985 GST_PSB_Byte6 5000;
BA_ "Version" SG_ 1985 GST_PSB_Byte6 "21.02.04";
BA_ "Description" SG_ 1985 GST_PSB_Byte7 "TP Index : 154";
BA_ "UsrSigPurpose" SG_ 1985 GST_PSB_Byte7 3;
BA_ "UserSigValidity" SG_ 1985 GST_PSB_Byte7 0;
BA_ "NetworkRequest" SG_ 1985 GST_PSB_Byte7 0;
BA_ "NetworkRequestHoldingTime" SG_ 1985 GST_PSB_Byte7 5000;
BA_ "Version" SG_ 1985 GST_PSB_Byte7 "21.02.04";
BA_ "Description" SG_ 1985 GST_PSB_Byte1 "TP Index : 154";
BA_ "UsrSigPurpose" SG_ 1985 GST_PSB_Byte1 3;
BA_ "UserSigValidity" SG_ 1985 GST_PSB_Byte1 0;
BA_ "NetworkRequest" SG_ 1985 GST_PSB_Byte1 0;
BA_ "NetworkRequestHoldingTime" SG_ 1985 GST_PSB_Byte1 5000;
BA_ "Version" SG_ 1985 GST_PSB_Byte1 "21.02.04";
BA_ "Description" SG_ 2382594817 DATC_Crc6Val "The data area for CRC calculation is based on the data length (DLC) of the message DB.

The CRC shall be calculated over the entire data block (excluding the CRC bytes) including the user data, alive counter and Data ID



- CRC Polynomial (0x1021) , Ini";
BA_ "GenSigSendType" SG_ 2382594817 DATC_Crc6Val 4;
BA_ "GenSigStartValue" SG_ 2382594817 DATC_Crc6Val 65535;
BA_ "UserSigValidity" SG_ 2382594817 DATC_Crc6Val 3;
BA_ "Version" SG_ 2382594817 DATC_Crc6Val "21.09.03";
BA_ "Description" SG_ 2382594817 DATC_AlvCnt6Val "For the first transmission request for a data element the counter shall be initialized with 0 and shall be incremented by 1 for every subsequent send request. 

When the counter reaches the maximum value(0xFF), then it shall restart with 0 for the next s";
BA_ "GenSigSendType" SG_ 2382594817 DATC_AlvCnt6Val 4;
BA_ "UserSigValidity" SG_ 2382594817 DATC_AlvCnt6Val 3;
BA_ "Version" SG_ 2382594817 DATC_AlvCnt6Val "21.09.03";
BA_ "Description" SG_ 2382594817 DATC_RrAcDis "This signal indicates Status of Rear A/C Button Indicator for MultiKeyboard.";
BA_ "GenSigSendType" SG_ 2382594817 DATC_RrAcDis 4;
BA_ "UserSigValidity" SG_ 2382594817 DATC_RrAcDis 7;
BA_ "Version" SG_ 2382594817 DATC_RrAcDis "22.02.08";
BA_ "Description" SG_ 2382594817 DATC_MaxAcDis "This signal indicates Max A/C Graphic On & Off.

This signal occurs when Max A/C switch(button) is selected manually.";
BA_ "GenSigSendType" SG_ 2382594817 DATC_MaxAcDis 4;
BA_ "UserSigValidity" SG_ 2382594817 DATC_MaxAcDis 3;
BA_ "Version" SG_ 2382594817 DATC_MaxAcDis "17.11.00";
BA_ "Description" SG_ 2382594817 DATC_SyncDis "This signal indicates DUAL Graphic On & Off.

This signal occurs when DUAL switch(button) is selected either manually or automatically.";
BA_ "GenSigSendType" SG_ 2382594817 DATC_SyncDis 4;
BA_ "UserSigValidity" SG_ 2382594817 DATC_SyncDis 6;
BA_ "Version" SG_ 2382594817 DATC_SyncDis "17.11.00";
BA_ "Description" SG_ 2382594817 DATC_OpSta "This signal indicates Operating status of DATC.";
BA_ "GenSigSendType" SG_ 2382594817 DATC_OpSta 4;
BA_ "UserSigValidity" SG_ 2382594817 DATC_OpSta 6;
BA_ "Version" SG_ 2382594817 DATC_OpSta "17.11.00";
BA_ "Description" SG_ 2382594817 DATC_FrDfgSta "This signal indicates DEF LED On & Off.

This signal occurs when DEF switch(button) is selected manually.";
BA_ "GenSigSendType" SG_ 2382594817 DATC_FrDfgSta 4;
BA_ "UserSigValidity" SG_ 2382594817 DATC_FrDfgSta 6;
BA_ "Version" SG_ 2382594817 DATC_FrDfgSta "17.11.00";
BA_ "Description" SG_ 2382594817 DATC_SmrtVntDis "Display Smart  Ventilation / Smart CO2  Ventilation";
BA_ "GenSigSendType" SG_ 2382594817 DATC_SmrtVntDis 4;
BA_ "UserSigValidity" SG_ 2382594817 DATC_SmrtVntDis 3;
BA_ "Version" SG_ 2382594817 DATC_SmrtVntDis "17.11.00";
BA_ "Description" SG_ 2382594817 DATC_AutoDfgBlnkDis "This signal indicates that Auto Defog LED blinks On & Off.

This signal occurs when Auto Defog system operates automatically.";
BA_ "GenSigSendType" SG_ 2382594817 DATC_AutoDfgBlnkDis 4;
BA_ "UserSigValidity" SG_ 2382594817 DATC_AutoDfgBlnkDis 6;
BA_ "Version" SG_ 2382594817 DATC_AutoDfgBlnkDis "17.11.00";
BA_ "Description" SG_ 2382594817 DATC_AutoDfgSysOffDis "Display Auto Defog System Off (When the user does not  use Auto Defog System on purpose)";
BA_ "GenSigSendType" SG_ 2382594817 DATC_AutoDfgSysOffDis 4;
BA_ "GenSigStartValue" SG_ 2382594817 DATC_AutoDfgSysOffDis 2;
BA_ "UserSigValidity" SG_ 2382594817 DATC_AutoDfgSysOffDis 3;
BA_ "Version" SG_ 2382594817 DATC_AutoDfgSysOffDis "17.11.00";
BA_ "Description" SG_ 2382594817 DATC_SchdldVntOpSta "Operating Status of Scheduled Ventilation";
BA_ "GenSigSendType" SG_ 2382594817 DATC_SchdldVntOpSta 4;
BA_ "UserSigValidity" SG_ 2382594817 DATC_SchdldVntOpSta 7;
BA_ "Version" SG_ 2382594817 DATC_SchdldVntOpSta "22.05.02";
BA_ "Description" SG_ 2382594817 DATC_3rdAcDis "This signal indicates Status of 3rd  A/C Button Indicator for MultiKeyboard.";
BA_ "GenSigSendType" SG_ 2382594817 DATC_3rdAcDis 4;
BA_ "UserSigValidity" SG_ 2382594817 DATC_3rdAcDis 7;
BA_ "Version" SG_ 2382594817 DATC_3rdAcDis "22.07.05";
BA_ "Description" SG_ 2382594817 DATC_ArClnIND "This signal indicates Status of AirClean Button Indicator for MultiKeyboard.";
BA_ "GenSigSendType" SG_ 2382594817 DATC_ArClnIND 4;
BA_ "UserSigValidity" SG_ 2382594817 DATC_ArClnIND 7;
BA_ "Version" SG_ 2382594817 DATC_ArClnIND "19.08.03";
BA_ "Description" SG_ 2382594817 DATC_RrDfgInd "Rear Defog Switch indicator signal";
BA_ "GenSigSendType" SG_ 2382594817 DATC_RrDfgInd 4;
BA_ "UserSigValidity" SG_ 2382594817 DATC_RrDfgInd 7;
BA_ "Version" SG_ 2382594817 DATC_RrDfgInd "18.12.08";
BA_ "Description" SG_ 2382594817 DATC_FrModDEFInd "DATC_FrontModeDefIndicator

Mode DEF button indicator status signal in case All Mode Button Type";
BA_ "GenSigSendType" SG_ 2382594817 DATC_FrModDEFInd 4;
BA_ "UserSigValidity" SG_ 2382594817 DATC_FrModDEFInd 7;
BA_ "Version" SG_ 2382594817 DATC_FrModDEFInd "18.12.08";
BA_ "Description" SG_ 2382594817 DATC_FrModVentInd "DATC_FrontModeVentIndicator

Mode VENT button indicator status signal in case ALL Mode Button Type";
BA_ "GenSigSendType" SG_ 2382594817 DATC_FrModVentInd 4;
BA_ "UserSigValidity" SG_ 2382594817 DATC_FrModVentInd 7;
BA_ "Version" SG_ 2382594817 DATC_FrModVentInd "18.12.08";
BA_ "Description" SG_ 2382594817 DATC_FrModFloorInd "DATC_FrontModeFloorIndicator

Mode FLOOR button indicator status signal in case ALL Mode Button Type";
BA_ "GenSigSendType" SG_ 2382594817 DATC_FrModFloorInd 4;
BA_ "UserSigValidity" SG_ 2382594817 DATC_FrModFloorInd 7;
BA_ "Version" SG_ 2382594817 DATC_FrModFloorInd "18.12.08";
BA_ "Description" SG_ 905 SBCM_RR_Crc1Val "The data area for CRC calculation is based on the data length (DLC) of the message DB.

The CRC shall be calculated over the entire data block (excluding the CRC bytes) including the user data, alive counter and Data ID 

 

- CRC Polynomial (0x1D) , Ini";
BA_ "GenSigSendType" SG_ 905 SBCM_RR_Crc1Val 4;
BA_ "GenSigStartValue" SG_ 905 SBCM_RR_Crc1Val 255;
BA_ "UserSigValidity" SG_ 905 SBCM_RR_Crc1Val 0;
BA_ "Version" SG_ 905 SBCM_RR_Crc1Val "19.07.06";
BA_ "Description" SG_ 905 RR_CrashUnlockCmd "RearRightCrashUnlockCommand";
BA_ "GenSigSendType" SG_ 905 RR_CrashUnlockCmd 4;
BA_ "UserSigValidity" SG_ 905 RR_CrashUnlockCmd 0;
BA_ "NetworkRequest" SG_ 905 RR_CrashUnlockCmd 0;
BA_ "Version" SG_ 905 RR_CrashUnlockCmd "20.09.00";
BA_ "Description" SG_ 905 SBCM_RR_AlvCnt1Val "For the first transmission request for a data element the counter shall be initialized with 0 and shall be incremented by 1

for every subsequent send request. When the counter reaches the maximum value(0xE), then it shall restart with 0 for the next sen";
BA_ "GenSigSendType" SG_ 905 SBCM_RR_AlvCnt1Val 4;
BA_ "UserSigValidity" SG_ 905 SBCM_RR_AlvCnt1Val 0;
BA_ "Version" SG_ 905 SBCM_RR_AlvCnt1Val "19.07.06";
BA_ "Description" SG_ 905 Warn_RrRtDrSwSta_SBCM "Warning Rear Right Door Switch Status";
BA_ "GenSigSendType" SG_ 905 Warn_RrRtDrSwSta_SBCM 4;
BA_ "UserSigValidity" SG_ 905 Warn_RrRtDrSwSta_SBCM 0;
BA_ "NetworkRequest" SG_ 905 Warn_RrRtDrSwSta_SBCM 0;
BA_ "Version" SG_ 905 Warn_RrRtDrSwSta_SBCM "21.07.07";
BA_ "Description" SG_ 905 DoorLock_RrRtDrUnLkSta_SBCM "Rear Right Door Unlock Status";
BA_ "GenSigSendType" SG_ 905 DoorLock_RrRtDrUnLkSta_SBCM 4;
BA_ "UserSigValidity" SG_ 905 DoorLock_RrRtDrUnLkSta_SBCM 0;
BA_ "NetworkRequest" SG_ 905 DoorLock_RrRtDrUnLkSta_SBCM 0;
BA_ "Version" SG_ 905 DoorLock_RrRtDrUnLkSta_SBCM "19.07.06";
BA_ "Description" SG_ 905 RR_SEAActivated "RearRightSEAActivated";
BA_ "GenSigSendType" SG_ 905 RR_SEAActivated 4;
BA_ "UserSigValidity" SG_ 905 RR_SEAActivated 0;
BA_ "NetworkRequest" SG_ 905 RR_SEAActivated 0;
BA_ "Version" SG_ 905 RR_SEAActivated "19.07.06";
BA_ "Description" SG_ 905 RR_SEAWarn "RearRighrSEAWarning";
BA_ "GenSigSendType" SG_ 905 RR_SEAWarn 4;
BA_ "UserSigValidity" SG_ 905 RR_SEAWarn 0;
BA_ "NetworkRequest" SG_ 905 RR_SEAWarn 0;
BA_ "Version" SG_ 905 RR_SEAWarn "19.07.06";
BA_ "GenSigSendType" SG_ 905 RR_SEWWarn 4;
BA_ "UserSigValidity" SG_ 905 RR_SEWWarn 0;
BA_ "NetworkRequest" SG_ 905 RR_SEWWarn 0;
BA_ "Version" SG_ 905 RR_SEWWarn "20.09.00";
BA_ "GenSigSendType" SG_ 905 RR_ReleaseWarn 4;
BA_ "UserSigValidity" SG_ 905 RR_ReleaseWarn 0;
BA_ "NetworkRequest" SG_ 905 RR_ReleaseWarn 0;
BA_ "NetworkRequestHoldingTime" SG_ 905 RR_ReleaseWarn 5000;
BA_ "Version" SG_ 905 RR_ReleaseWarn "20.09.00";
BA_ "GenSigSendType" SG_ 905 RR_SWFailAlarm 4;
BA_ "UserSigValidity" SG_ 905 RR_SWFailAlarm 0;
BA_ "NetworkRequest" SG_ 905 RR_SWFailAlarm 0;
BA_ "NetworkRequestHoldingTime" SG_ 905 RR_SWFailAlarm 5000;
BA_ "Version" SG_ 905 RR_SWFailAlarm "20.09.00";
BA_ "GenSigSendType" SG_ 905 RR_ChildLock_ActnFlSta 4;
BA_ "UserSigValidity" SG_ 905 RR_ChildLock_ActnFlSta 0;
BA_ "NetworkRequest" SG_ 905 RR_ChildLock_ActnFlSta 0;
BA_ "NetworkRequestHoldingTime" SG_ 905 RR_ChildLock_ActnFlSta 5000;
BA_ "Version" SG_ 905 RR_ChildLock_ActnFlSta "19.11.05";
BA_ "GenSigSendType" SG_ 905 RR_MRActivationAlarm 4;
BA_ "UserSigValidity" SG_ 905 RR_MRActivationAlarm 0;
BA_ "NetworkRequest" SG_ 905 RR_MRActivationAlarm 0;
BA_ "NetworkRequestHoldingTime" SG_ 905 RR_MRActivationAlarm 5000;
BA_ "Version" SG_ 905 RR_MRActivationAlarm "19.11.05";
BA_ "GenSigSendType" SG_ 905 RR_ChildLock_Status 4;
BA_ "UserSigValidity" SG_ 905 RR_ChildLock_Status 0;
BA_ "NetworkRequest" SG_ 905 RR_ChildLock_Status 0;
BA_ "NetworkRequestHoldingTime" SG_ 905 RR_ChildLock_Status 5000;
BA_ "Version" SG_ 905 RR_ChildLock_Status "21.07.07";
BA_ "GenSigSendType" SG_ 905 USM_RRGhostDoorSta 4;
BA_ "UserSigValidity" SG_ 905 USM_RRGhostDoorSta 0;
BA_ "NetworkRequest" SG_ 905 USM_RRGhostDoorSta 0;
BA_ "NetworkRequestHoldingTime" SG_ 905 USM_RRGhostDoorSta 5000;
BA_ "Version" SG_ 905 USM_RRGhostDoorSta "21.03.11";
BA_ "GenSigSendType" SG_ 905 DoorLock_PDSLkSwSta_RR 4;
BA_ "UserSigValidity" SG_ 905 DoorLock_PDSLkSwSta_RR 0;
BA_ "NetworkRequest" SG_ 905 DoorLock_PDSLkSwSta_RR 0;
BA_ "Version" SG_ 905 DoorLock_PDSLkSwSta_RR "19.12.00";
BA_ "GenSigSendType" SG_ 905 PDS_TypeOption_RR 4;
BA_ "UserSigValidity" SG_ 905 PDS_TypeOption_RR 0;
BA_ "NetworkRequest" SG_ 905 PDS_TypeOption_RR 0;
BA_ "Version" SG_ 905 PDS_TypeOption_RR "19.12.00";
BA_ "GenSigSendType" SG_ 905 RRDoorPushAlarm 4;
BA_ "UserSigValidity" SG_ 905 RRDoorPushAlarm 0;
BA_ "NetworkRequest" SG_ 905 RRDoorPushAlarm 0;
BA_ "NetworkRequestHoldingTime" SG_ 905 RRDoorPushAlarm 5000;
BA_ "Version" SG_ 905 RRDoorPushAlarm "20.09.00";
BA_ "Description" SG_ 904 PSM_DrvReclinePosition "DRIVER SEAT RECLINE POSITION (UNIT: ¢ª)";
BA_ "GenSigSendType" SG_ 904 PSM_DrvReclinePosition 4;
BA_ "UserSigValidity" SG_ 904 PSM_DrvReclinePosition 0;
BA_ "NetworkRequest" SG_ 904 PSM_DrvReclinePosition 0;
BA_ "NetworkRequestHoldingTime" SG_ 904 PSM_DrvReclinePosition 5000;
BA_ "Version" SG_ 904 PSM_DrvReclinePosition "19.08.06";
BA_ "Description" SG_ 904 PSM_EsyAcsGetOffSta "-(Old)C_EasyAccessGetOff";
BA_ "GenSigSendType" SG_ 904 PSM_EsyAcsGetOffSta 4;
BA_ "UserSigValidity" SG_ 904 PSM_EsyAcsGetOffSta 0;
BA_ "NetworkRequest" SG_ 904 PSM_EsyAcsGetOffSta 0;
BA_ "NetworkRequestHoldingTime" SG_ 904 PSM_EsyAcsGetOffSta 5000;
BA_ "Version" SG_ 904 PSM_EsyAcsGetOffSta "17.11.00";
BA_ "Description" SG_ 904 PSM_EsyAcsStpSta "-(Old)C_EasyAccessStop";
BA_ "GenSigSendType" SG_ 904 PSM_EsyAcsStpSta 4;
BA_ "UserSigValidity" SG_ 904 PSM_EsyAcsStpSta 0;
BA_ "NetworkRequest" SG_ 904 PSM_EsyAcsStpSta 0;
BA_ "NetworkRequestHoldingTime" SG_ 904 PSM_EsyAcsStpSta 5000;
BA_ "Version" SG_ 904 PSM_EsyAcsStpSta "17.11.00";
BA_ "Description" SG_ 904 PSM_SWVerMajor1 "Indicate the PSM software version as follows:

- The software version is displayed in three digits.

- The Major and Minor digits are separated by '.'

- Signal values are transmitted to ASCII codes.



¡Ø Example

PSM_SWVerMajor1 : 0x41 (HEX) -> ASCII C";
BA_ "GenSigSendType" SG_ 904 PSM_SWVerMajor1 4;
BA_ "UserSigValidity" SG_ 904 PSM_SWVerMajor1 0;
BA_ "Version" SG_ 904 PSM_SWVerMajor1 "20.12.04";
BA_ "Description" SG_ 904 PSM_SWVerMinor1 "Indicate the PSM software version as follows:

- The software version is displayed in three digits.

- The Major and Minor digits are separated by '.'

- Signal values are transmitted to ASCII codes.



¡Ø Example

PSM_SWVerMajor1 : 0x41 (HEX) -> ASCII C";
BA_ "GenSigSendType" SG_ 904 PSM_SWVerMinor1 4;
BA_ "UserSigValidity" SG_ 904 PSM_SWVerMinor1 0;
BA_ "Version" SG_ 904 PSM_SWVerMinor1 "18.10.06";
BA_ "Description" SG_ 904 PSM_SWVerMinor2 "Indicate the PSM software version as follows:

- The software version is displayed in three digits.

- The Major and Minor digits are separated by '.'

- Signal values are transmitted to ASCII codes.



¡Ø Example

PSM_SWVerMajor1 : 0x41 (HEX) -> ASCII C";
BA_ "GenSigSendType" SG_ 904 PSM_SWVerMinor2 4;
BA_ "UserSigValidity" SG_ 904 PSM_SWVerMinor2 0;
BA_ "Version" SG_ 904 PSM_SWVerMinor2 "18.10.06";
BA_ "Description" SG_ 904 PSM_HDPSpprtSWVer "This signal indicates Requirement Spec Version about PSM by HDP";
BA_ "GenSigSendType" SG_ 904 PSM_HDPSpprtSWVer 4;
BA_ "UserSigValidity" SG_ 904 PSM_HDPSpprtSWVer 0;
BA_ "Version" SG_ 904 PSM_HDPSpprtSWVer "22.01.00";
BA_ "Description" SG_ 904 PSM_DrvHeightPosition "DRIVER SEAT HEIGHT POSITION (UNIT: mm)";
BA_ "GenSigSendType" SG_ 904 PSM_DrvHeightPosition 4;
BA_ "UserSigValidity" SG_ 904 PSM_DrvHeightPosition 0;
BA_ "NetworkRequest" SG_ 904 PSM_DrvHeightPosition 0;
BA_ "NetworkRequestHoldingTime" SG_ 904 PSM_DrvHeightPosition 5000;
BA_ "Version" SG_ 904 PSM_DrvHeightPosition "20.03.03";
BA_ "Description" SG_ 904 PSM_DrvSlidePosition "DRIVER SEAT SLIDE POSITION (UNIT: mm, 1 Value ´ç 2mm)";
BA_ "GenSigSendType" SG_ 904 PSM_DrvSlidePosition 4;
BA_ "UserSigValidity" SG_ 904 PSM_DrvSlidePosition 0;
BA_ "NetworkRequest" SG_ 904 PSM_DrvSlidePosition 0;
BA_ "NetworkRequestHoldingTime" SG_ 904 PSM_DrvSlidePosition 5000;
BA_ "Version" SG_ 904 PSM_DrvSlidePosition "22.06.05";
BA_ "Description" SG_ 904 PSM_EsyAcsGetOnSta "-(Old)C_EasyAccessGetOn";
BA_ "GenSigSendType" SG_ 904 PSM_EsyAcsGetOnSta 4;
BA_ "UserSigValidity" SG_ 904 PSM_EsyAcsGetOnSta 0;
BA_ "NetworkRequest" SG_ 904 PSM_EsyAcsGetOnSta 0;
BA_ "NetworkRequestHoldingTime" SG_ 904 PSM_EsyAcsGetOnSta 5000;
BA_ "Version" SG_ 904 PSM_EsyAcsGetOnSta "17.11.00";
BA_ "Description" SG_ 903 PSM_DrvStSldFwdDis "This signal is used to display the seat movement to AVN";
BA_ "GenSigSendType" SG_ 903 PSM_DrvStSldFwdDis 4;
BA_ "UserSigValidity" SG_ 903 PSM_DrvStSldFwdDis 1;
BA_ "NetworkRequest" SG_ 903 PSM_DrvStSldFwdDis 0;
BA_ "NetworkRequestHoldingTime" SG_ 903 PSM_DrvStSldFwdDis 5000;
BA_ "Version" SG_ 903 PSM_DrvStSldFwdDis "17.11.00";
BA_ "Description" SG_ 903 PSM_DrvStTiltDnDis "This signal is used to display the seat movement to AVN";
BA_ "GenSigSendType" SG_ 903 PSM_DrvStTiltDnDis 4;
BA_ "UserSigValidity" SG_ 903 PSM_DrvStTiltDnDis 1;
BA_ "NetworkRequest" SG_ 903 PSM_DrvStTiltDnDis 0;
BA_ "NetworkRequestHoldingTime" SG_ 903 PSM_DrvStTiltDnDis 5000;
BA_ "Version" SG_ 903 PSM_DrvStTiltDnDis "17.11.00";
BA_ "Description" SG_ 903 PSM_DrvStHghtUpDis "This signal is used to display the seat movement to AVN";
BA_ "GenSigSendType" SG_ 903 PSM_DrvStHghtUpDis 4;
BA_ "UserSigValidity" SG_ 903 PSM_DrvStHghtUpDis 1;
BA_ "NetworkRequest" SG_ 903 PSM_DrvStHghtUpDis 0;
BA_ "NetworkRequestHoldingTime" SG_ 903 PSM_DrvStHghtUpDis 5000;
BA_ "Version" SG_ 903 PSM_DrvStHghtUpDis "17.11.00";
BA_ "Description" SG_ 903 PSM_DrvStHghtDnDis "This signal is used to display the seat movement to AVN";
BA_ "GenSigSendType" SG_ 903 PSM_DrvStHghtDnDis 4;
BA_ "UserSigValidity" SG_ 903 PSM_DrvStHghtDnDis 1;
BA_ "NetworkRequest" SG_ 903 PSM_DrvStHghtDnDis 0;
BA_ "NetworkRequestHoldingTime" SG_ 903 PSM_DrvStHghtDnDis 5000;
BA_ "Version" SG_ 903 PSM_DrvStHghtDnDis "17.11.00";
BA_ "Description" SG_ 903 PSM_DrvStCushExtBckwdDis "This signal is used to display the seat movement to AVN";
BA_ "GenSigSendType" SG_ 903 PSM_DrvStCushExtBckwdDis 4;
BA_ "UserSigValidity" SG_ 903 PSM_DrvStCushExtBckwdDis 1;
BA_ "NetworkRequest" SG_ 903 PSM_DrvStCushExtBckwdDis 0;
BA_ "NetworkRequestHoldingTime" SG_ 903 PSM_DrvStCushExtBckwdDis 5000;
BA_ "Version" SG_ 903 PSM_DrvStCushExtBckwdDis "17.11.00";
BA_ "Description" SG_ 903 PSM_DrvStCushExtFwdDis "This signal is used to display the seat movement to AVN";
BA_ "GenSigSendType" SG_ 903 PSM_DrvStCushExtFwdDis 4;
BA_ "UserSigValidity" SG_ 903 PSM_DrvStCushExtFwdDis 1;
BA_ "NetworkRequest" SG_ 903 PSM_DrvStCushExtFwdDis 0;
BA_ "NetworkRequestHoldingTime" SG_ 903 PSM_DrvStCushExtFwdDis 5000;
BA_ "Version" SG_ 903 PSM_DrvStCushExtFwdDis "17.11.00";
BA_ "Description" SG_ 903 PSM_DrvStSldBckwdDis "This signal is used to display the seat movement to AVN";
BA_ "GenSigSendType" SG_ 903 PSM_DrvStSldBckwdDis 4;
BA_ "UserSigValidity" SG_ 903 PSM_DrvStSldBckwdDis 1;
BA_ "NetworkRequest" SG_ 903 PSM_DrvStSldBckwdDis 0;
BA_ "NetworkRequestHoldingTime" SG_ 903 PSM_DrvStSldBckwdDis 5000;
BA_ "Version" SG_ 903 PSM_DrvStSldBckwdDis "17.11.00";
BA_ "Description" SG_ 903 PSM_DrvStHdRstUpDis "This signal is used to display the seat movement to AVN";
BA_ "GenSigSendType" SG_ 903 PSM_DrvStHdRstUpDis 4;
BA_ "UserSigValidity" SG_ 903 PSM_DrvStHdRstUpDis 1;
BA_ "NetworkRequest" SG_ 903 PSM_DrvStHdRstUpDis 0;
BA_ "NetworkRequestHoldingTime" SG_ 903 PSM_DrvStHdRstUpDis 5000;
BA_ "Version" SG_ 903 PSM_DrvStHdRstUpDis "20.07.05";
BA_ "Description" SG_ 903 PSM_DrvStHdRstDnDis "This signal is used to display the seat movement to AVN";
BA_ "GenSigSendType" SG_ 903 PSM_DrvStHdRstDnDis 4;
BA_ "UserSigValidity" SG_ 903 PSM_DrvStHdRstDnDis 1;
BA_ "NetworkRequest" SG_ 903 PSM_DrvStHdRstDnDis 0;
BA_ "NetworkRequestHoldingTime" SG_ 903 PSM_DrvStHdRstDnDis 5000;
BA_ "Version" SG_ 903 PSM_DrvStHdRstDnDis "17.11.00";
BA_ "Description" SG_ 903 PSM_DrvStHdRstFwdDis "This signal is used to display the seat movement to AVN";
BA_ "GenSigSendType" SG_ 903 PSM_DrvStHdRstFwdDis 4;
BA_ "UserSigValidity" SG_ 903 PSM_DrvStHdRstFwdDis 1;
BA_ "NetworkRequest" SG_ 903 PSM_DrvStHdRstFwdDis 0;
BA_ "NetworkRequestHoldingTime" SG_ 903 PSM_DrvStHdRstFwdDis 5000;
BA_ "Version" SG_ 903 PSM_DrvStHdRstFwdDis "17.11.00";
BA_ "Description" SG_ 903 PSM_DrvStHdRstBckwdDis "This signal is used to display the seat movement to AVN";
BA_ "GenSigSendType" SG_ 903 PSM_DrvStHdRstBckwdDis 4;
BA_ "UserSigValidity" SG_ 903 PSM_DrvStHdRstBckwdDis 1;
BA_ "NetworkRequest" SG_ 903 PSM_DrvStHdRstBckwdDis 0;
BA_ "NetworkRequestHoldingTime" SG_ 903 PSM_DrvStHdRstBckwdDis 5000;
BA_ "Version" SG_ 903 PSM_DrvStHdRstBckwdDis "17.11.00";
BA_ "Description" SG_ 903 PSM_DrvStLmbrDefDis "This signal is used to display the seat movement to AVN";
BA_ "GenSigSendType" SG_ 903 PSM_DrvStLmbrDefDis 4;
BA_ "UserSigValidity" SG_ 903 PSM_DrvStLmbrDefDis 1;
BA_ "NetworkRequest" SG_ 903 PSM_DrvStLmbrDefDis 0;
BA_ "NetworkRequestHoldingTime" SG_ 903 PSM_DrvStLmbrDefDis 5000;
BA_ "Version" SG_ 903 PSM_DrvStLmbrDefDis "17.11.00";
BA_ "Description" SG_ 903 PSM_DrvStLmbrLoDis "This signal is used to display the seat movement to AVN";
BA_ "GenSigSendType" SG_ 903 PSM_DrvStLmbrLoDis 4;
BA_ "UserSigValidity" SG_ 903 PSM_DrvStLmbrLoDis 1;
BA_ "NetworkRequest" SG_ 903 PSM_DrvStLmbrLoDis 0;
BA_ "NetworkRequestHoldingTime" SG_ 903 PSM_DrvStLmbrLoDis 5000;
BA_ "Version" SG_ 903 PSM_DrvStLmbrLoDis "17.11.00";
BA_ "Description" SG_ 903 PSM_DrvStLmbrMdlDis "This signal is used to display the seat movement to AVN";
BA_ "GenSigSendType" SG_ 903 PSM_DrvStLmbrMdlDis 4;
BA_ "UserSigValidity" SG_ 903 PSM_DrvStLmbrMdlDis 1;
BA_ "NetworkRequest" SG_ 903 PSM_DrvStLmbrMdlDis 0;
BA_ "NetworkRequestHoldingTime" SG_ 903 PSM_DrvStLmbrMdlDis 5000;
BA_ "Version" SG_ 903 PSM_DrvStLmbrMdlDis "17.11.00";
BA_ "Description" SG_ 903 PSM_DrvStLmbrUpDis "This signal is used to display the seat movement to AVN";
BA_ "GenSigSendType" SG_ 903 PSM_DrvStLmbrUpDis 4;
BA_ "UserSigValidity" SG_ 903 PSM_DrvStLmbrUpDis 1;
BA_ "NetworkRequest" SG_ 903 PSM_DrvStLmbrUpDis 0;
BA_ "NetworkRequestHoldingTime" SG_ 903 PSM_DrvStLmbrUpDis 5000;
BA_ "Version" SG_ 903 PSM_DrvStLmbrUpDis "17.11.00";
BA_ "Description" SG_ 903 PSM_DrvStReclneFwdDis "This signal is used to display the seat movement to AVN";
BA_ "GenSigSendType" SG_ 903 PSM_DrvStReclneFwdDis 4;
BA_ "UserSigValidity" SG_ 903 PSM_DrvStReclneFwdDis 1;
BA_ "NetworkRequest" SG_ 903 PSM_DrvStReclneFwdDis 0;
BA_ "NetworkRequestHoldingTime" SG_ 903 PSM_DrvStReclneFwdDis 5000;
BA_ "Version" SG_ 903 PSM_DrvStReclneFwdDis "17.11.00";
BA_ "Description" SG_ 903 PSM_DrvStBlstrDefDis "This signal is used to display the seat movement to AVN";
BA_ "GenSigSendType" SG_ 903 PSM_DrvStBlstrDefDis 4;
BA_ "UserSigValidity" SG_ 903 PSM_DrvStBlstrDefDis 1;
BA_ "NetworkRequest" SG_ 903 PSM_DrvStBlstrDefDis 0;
BA_ "NetworkRequestHoldingTime" SG_ 903 PSM_DrvStBlstrDefDis 5000;
BA_ "Version" SG_ 903 PSM_DrvStBlstrDefDis "17.11.00";
BA_ "Description" SG_ 903 PSM_DrvStBlstrInfDis "This signal is used to display the seat movement to AVN";
BA_ "GenSigSendType" SG_ 903 PSM_DrvStBlstrInfDis 4;
BA_ "UserSigValidity" SG_ 903 PSM_DrvStBlstrInfDis 1;
BA_ "NetworkRequest" SG_ 903 PSM_DrvStBlstrInfDis 0;
BA_ "NetworkRequestHoldingTime" SG_ 903 PSM_DrvStBlstrInfDis 5000;
BA_ "Version" SG_ 903 PSM_DrvStBlstrInfDis "17.11.00";
BA_ "Description" SG_ 903 PSM_DrvStReclneBckwdDis "This signal is used to display the seat movement to AVN";
BA_ "GenSigSendType" SG_ 903 PSM_DrvStReclneBckwdDis 4;
BA_ "UserSigValidity" SG_ 903 PSM_DrvStReclneBckwdDis 1;
BA_ "NetworkRequest" SG_ 903 PSM_DrvStReclneBckwdDis 0;
BA_ "NetworkRequestHoldingTime" SG_ 903 PSM_DrvStReclneBckwdDis 5000;
BA_ "Version" SG_ 903 PSM_DrvStReclneBckwdDis "17.11.00";
BA_ "Description" SG_ 903 PSM_DrvStTiltUpDis "This signal is used to display the seat movement to AVN";
BA_ "GenSigSendType" SG_ 903 PSM_DrvStTiltUpDis 4;
BA_ "UserSigValidity" SG_ 903 PSM_DrvStTiltUpDis 1;
BA_ "NetworkRequest" SG_ 903 PSM_DrvStTiltUpDis 0;
BA_ "NetworkRequestHoldingTime" SG_ 903 PSM_DrvStTiltUpDis 5000;
BA_ "Version" SG_ 903 PSM_DrvStTiltUpDis "17.11.00";
BA_ "GenSigSendType" SG_ 902 PSM_DrvStEsyAcsUSMSta 4;
BA_ "UserSigValidity" SG_ 902 PSM_DrvStEsyAcsUSMSta 0;
BA_ "NetworkRequest" SG_ 902 PSM_DrvStEsyAcsUSMSta 0;
BA_ "NetworkRequestHoldingTime" SG_ 902 PSM_DrvStEsyAcsUSMSta 5000;
BA_ "Version" SG_ 902 PSM_DrvStEsyAcsUSMSta "17.11.00";
BA_ "Description" SG_ 902 PSM_SeatPosPlyBck_Sta "The signal indicates the state of Driver's seat position playing back.";
BA_ "GenSigSendType" SG_ 902 PSM_SeatPosPlyBck_Sta 4;
BA_ "UserSigValidity" SG_ 902 PSM_SeatPosPlyBck_Sta 0;
BA_ "Version" SG_ 902 PSM_SeatPosPlyBck_Sta "20.03.01";
BA_ "Description" SG_ 902 PSM_SeatPos_Sta "The signal indicates the state of  Driver seat Meomry State";
BA_ "GenSigSendType" SG_ 902 PSM_SeatPos_Sta 4;
BA_ "UserSigValidity" SG_ 902 PSM_SeatPos_Sta 0;
BA_ "Version" SG_ 902 PSM_SeatPos_Sta "20.03.01";
BA_ "Description" SG_ 902 PSM_SeatPosSldLmt_Sta "PSM Slide end Position and limit Initialize State information";
BA_ "GenSigSendType" SG_ 902 PSM_SeatPosSldLmt_Sta 4;
BA_ "UserSigValidity" SG_ 902 PSM_SeatPosSldLmt_Sta 0;
BA_ "NetworkRequest" SG_ 902 PSM_SeatPosSldLmt_Sta 0;
BA_ "NetworkRequestHoldingTime" SG_ 902 PSM_SeatPosSldLmt_Sta 5000;
BA_ "Version" SG_ 902 PSM_SeatPosSldLmt_Sta "20.03.01";
BA_ "Description" SG_ 902 PSM_SeatPosRclnLmt_Sta "PSM Recline end Position and limit Initialize State information";
BA_ "GenSigSendType" SG_ 902 PSM_SeatPosRclnLmt_Sta 4;
BA_ "UserSigValidity" SG_ 902 PSM_SeatPosRclnLmt_Sta 0;
BA_ "NetworkRequest" SG_ 902 PSM_SeatPosRclnLmt_Sta 0;
BA_ "NetworkRequestHoldingTime" SG_ 902 PSM_SeatPosRclnLmt_Sta 5000;
BA_ "Version" SG_ 902 PSM_SeatPosRclnLmt_Sta "20.03.01";
BA_ "Description" SG_ 902 SmrtIMS_StatureRspVal "User height information response value for Health Care IMS";
BA_ "GenSigSendType" SG_ 902 SmrtIMS_StatureRspVal 4;
BA_ "UserSigValidity" SG_ 902 SmrtIMS_StatureRspVal 0;
BA_ "NetworkRequest" SG_ 902 SmrtIMS_StatureRspVal 0;
BA_ "NetworkRequestHoldingTime" SG_ 902 SmrtIMS_StatureRspVal 5000;
BA_ "Version" SG_ 902 SmrtIMS_StatureRspVal "17.11.00";
BA_ "Description" SG_ 902 SmrtIMS_SeatedHghtRspVal "User sit height information response value for Health Care IMS";
BA_ "GenSigSendType" SG_ 902 SmrtIMS_SeatedHghtRspVal 4;
BA_ "UserSigValidity" SG_ 902 SmrtIMS_SeatedHghtRspVal 0;
BA_ "NetworkRequest" SG_ 902 SmrtIMS_SeatedHghtRspVal 0;
BA_ "NetworkRequestHoldingTime" SG_ 902 SmrtIMS_SeatedHghtRspVal 5000;
BA_ "Version" SG_ 902 SmrtIMS_SeatedHghtRspVal "17.11.00";
BA_ "Description" SG_ 902 SmrtIMS_WghtRspVal "User weight information repsponse value for Health Care IMS";
BA_ "GenSigSendType" SG_ 902 SmrtIMS_WghtRspVal 4;
BA_ "UserSigValidity" SG_ 902 SmrtIMS_WghtRspVal 0;
BA_ "NetworkRequest" SG_ 902 SmrtIMS_WghtRspVal 0;
BA_ "NetworkRequestHoldingTime" SG_ 902 SmrtIMS_WghtRspVal 5000;
BA_ "Version" SG_ 902 SmrtIMS_WghtRspVal "17.11.00";
BA_ "Description" SG_ 902 SmartIMS_DisReq "For displaying the state of seat moving";
BA_ "GenSigSendType" SG_ 902 SmartIMS_DisReq 4;
BA_ "UserSigValidity" SG_ 902 SmartIMS_DisReq 0;
BA_ "NetworkRequest" SG_ 902 SmartIMS_DisReq 0;
BA_ "NetworkRequestHoldingTime" SG_ 902 SmartIMS_DisReq 5000;
BA_ "Version" SG_ 902 SmartIMS_DisReq "17.11.00";
BA_ "Description" SG_ 902 SmrtIMS_ExitSta "-(Old)C_SmartIMSExit";
BA_ "GenSigSendType" SG_ 902 SmrtIMS_ExitSta 4;
BA_ "UserSigValidity" SG_ 902 SmrtIMS_ExitSta 0;
BA_ "NetworkRequest" SG_ 902 SmrtIMS_ExitSta 0;
BA_ "NetworkRequestHoldingTime" SG_ 902 SmrtIMS_ExitSta 5000;
BA_ "Version" SG_ 902 SmrtIMS_ExitSta "17.11.00";
BA_ "Description" SG_ 902 PSM_DrvStRlxTiltUpDis "This signal is used to display the seat movement to AVN";
BA_ "GenSigSendType" SG_ 902 PSM_DrvStRlxTiltUpDis 4;
BA_ "UserSigValidity" SG_ 902 PSM_DrvStRlxTiltUpDis 1;
BA_ "NetworkRequest" SG_ 902 PSM_DrvStRlxTiltUpDis 0;
BA_ "NetworkRequestHoldingTime" SG_ 902 PSM_DrvStRlxTiltUpDis 5000;
BA_ "Version" SG_ 902 PSM_DrvStRlxTiltUpDis "20.01.02";
BA_ "Description" SG_ 902 PSM_DrvStRlxTiltDnDis "This signal is used to display the seat movement to AVN";
BA_ "GenSigSendType" SG_ 902 PSM_DrvStRlxTiltDnDis 4;
BA_ "UserSigValidity" SG_ 902 PSM_DrvStRlxTiltDnDis 1;
BA_ "NetworkRequest" SG_ 902 PSM_DrvStRlxTiltDnDis 0;
BA_ "NetworkRequestHoldingTime" SG_ 902 PSM_DrvStRlxTiltDnDis 5000;
BA_ "Version" SG_ 902 PSM_DrvStRlxTiltDnDis "20.01.02";
BA_ "Description" SG_ 902 PSM_DrvStLegUpDis "This signal is used to display the seat movement to AVN";
BA_ "GenSigSendType" SG_ 902 PSM_DrvStLegUpDis 4;
BA_ "UserSigValidity" SG_ 902 PSM_DrvStLegUpDis 1;
BA_ "NetworkRequest" SG_ 902 PSM_DrvStLegUpDis 0;
BA_ "NetworkRequestHoldingTime" SG_ 902 PSM_DrvStLegUpDis 5000;
BA_ "Version" SG_ 902 PSM_DrvStLegUpDis "20.01.02";
BA_ "Description" SG_ 902 PSM_DrvStLegDnDis "This signal is used to display the seat movement to AVN";
BA_ "GenSigSendType" SG_ 902 PSM_DrvStLegDnDis 4;
BA_ "UserSigValidity" SG_ 902 PSM_DrvStLegDnDis 1;
BA_ "NetworkRequest" SG_ 902 PSM_DrvStLegDnDis 0;
BA_ "NetworkRequestHoldingTime" SG_ 902 PSM_DrvStLegDnDis 5000;
BA_ "Version" SG_ 902 PSM_DrvStLegDnDis "20.01.02";
BA_ "Description" SG_ 902 Drv_2ndStAutoRlxEnable "¿îÀü¼® ½ÃÆ® À§Ä¡¿¡ µû¸¥ ÈÄ¼® ¿ÀÅä ¸±·º¼Ç ÀÛµ¿ °¡´É ¿©ºÎ";
BA_ "GenSigSendType" SG_ 902 Drv_2ndStAutoRlxEnable 4;
BA_ "TimeoutValue" SG_ 902 Drv_2ndStAutoRlxEnable "0x0";
BA_ "UserSigValidity" SG_ 902 Drv_2ndStAutoRlxEnable 0;
BA_ "NetworkRequest" SG_ 902 Drv_2ndStAutoRlxEnable 0;
BA_ "NetworkRequestHoldingTime" SG_ 902 Drv_2ndStAutoRlxEnable 5000;
BA_ "Version" SG_ 902 Drv_2ndStAutoRlxEnable "21.06.10";
BA_ "Description" SG_ 902 Drv_AutoRlxSta "¿îÀü¼® ¿ÀÅä ¸±·º¼Ç µ¿ÀÛ Á¤º¸";
BA_ "GenSigSendType" SG_ 902 Drv_AutoRlxSta 4;
BA_ "TimeoutValue" SG_ 902 Drv_AutoRlxSta "0x0";
BA_ "UserSigValidity" SG_ 902 Drv_AutoRlxSta 0;
BA_ "NetworkRequest" SG_ 902 Drv_AutoRlxSta 0;
BA_ "NetworkRequestHoldingTime" SG_ 902 Drv_AutoRlxSta 5000;
BA_ "Version" SG_ 902 Drv_AutoRlxSta "21.06.10";
BA_ "Description" SG_ 902 Drv_AutoReturnSta "Driver Seat Auto Return Status Information";
BA_ "GenSigSendType" SG_ 902 Drv_AutoReturnSta 4;
BA_ "TimeoutValue" SG_ 902 Drv_AutoReturnSta "0x0";
BA_ "UserSigValidity" SG_ 902 Drv_AutoReturnSta 0;
BA_ "NetworkRequest" SG_ 902 Drv_AutoReturnSta 0;
BA_ "NetworkRequestHoldingTime" SG_ 902 Drv_AutoReturnSta 5000;
BA_ "Version" SG_ 902 Drv_AutoReturnSta "21.11.04";
BA_ "Description" SG_ 902 PSM_IMSOptTyp "-(Old)C_IMSOption";
BA_ "GenSigSendType" SG_ 902 PSM_IMSOptTyp 4;
BA_ "UserSigValidity" SG_ 902 PSM_IMSOptTyp 0;
BA_ "NetworkRequest" SG_ 902 PSM_IMSOptTyp 0;
BA_ "NetworkRequestHoldingTime" SG_ 902 PSM_IMSOptTyp 5000;
BA_ "Version" SG_ 902 PSM_IMSOptTyp "17.11.00";
BA_ "Description" SG_ 1993 PSB_GST_Byte0 "TP Index : 154";
BA_ "UsrSigPurpose" SG_ 1993 PSB_GST_Byte0 4;
BA_ "UserSigValidity" SG_ 1993 PSB_GST_Byte0 0;
BA_ "NetworkRequest" SG_ 1993 PSB_GST_Byte0 0;
BA_ "NetworkRequestHoldingTime" SG_ 1993 PSB_GST_Byte0 5000;
BA_ "Version" SG_ 1993 PSB_GST_Byte0 "22.07.01";
BA_ "Description" SG_ 1993 PSB_GST_Byte2 "TP Index : 154";
BA_ "UsrSigPurpose" SG_ 1993 PSB_GST_Byte2 4;
BA_ "UserSigValidity" SG_ 1993 PSB_GST_Byte2 0;
BA_ "NetworkRequest" SG_ 1993 PSB_GST_Byte2 0;
BA_ "NetworkRequestHoldingTime" SG_ 1993 PSB_GST_Byte2 5000;
BA_ "Version" SG_ 1993 PSB_GST_Byte2 "22.07.01";
BA_ "Description" SG_ 1993 PSB_GST_Byte3 "TP Index : 154";
BA_ "UsrSigPurpose" SG_ 1993 PSB_GST_Byte3 4;
BA_ "UserSigValidity" SG_ 1993 PSB_GST_Byte3 0;
BA_ "NetworkRequest" SG_ 1993 PSB_GST_Byte3 0;
BA_ "NetworkRequestHoldingTime" SG_ 1993 PSB_GST_Byte3 5000;
BA_ "Version" SG_ 1993 PSB_GST_Byte3 "22.07.01";
BA_ "Description" SG_ 1993 PSB_GST_Byte4 "TP Index : 154";
BA_ "UsrSigPurpose" SG_ 1993 PSB_GST_Byte4 4;
BA_ "UserSigValidity" SG_ 1993 PSB_GST_Byte4 0;
BA_ "NetworkRequest" SG_ 1993 PSB_GST_Byte4 0;
BA_ "NetworkRequestHoldingTime" SG_ 1993 PSB_GST_Byte4 5000;
BA_ "Version" SG_ 1993 PSB_GST_Byte4 "22.07.01";
BA_ "Description" SG_ 1993 PSB_GST_Byte5 "TP Index : 154";
BA_ "UsrSigPurpose" SG_ 1993 PSB_GST_Byte5 4;
BA_ "UserSigValidity" SG_ 1993 PSB_GST_Byte5 0;
BA_ "NetworkRequest" SG_ 1993 PSB_GST_Byte5 0;
BA_ "NetworkRequestHoldingTime" SG_ 1993 PSB_GST_Byte5 5000;
BA_ "Version" SG_ 1993 PSB_GST_Byte5 "22.07.01";
BA_ "Description" SG_ 1993 PSB_GST_Byte6 "TP Index : 154";
BA_ "UsrSigPurpose" SG_ 1993 PSB_GST_Byte6 4;
BA_ "UserSigValidity" SG_ 1993 PSB_GST_Byte6 0;
BA_ "NetworkRequest" SG_ 1993 PSB_GST_Byte6 0;
BA_ "NetworkRequestHoldingTime" SG_ 1993 PSB_GST_Byte6 5000;
BA_ "Version" SG_ 1993 PSB_GST_Byte6 "22.07.01";
BA_ "Description" SG_ 1993 PSB_GST_Byte7 "TP Index : 154";
BA_ "UsrSigPurpose" SG_ 1993 PSB_GST_Byte7 4;
BA_ "UserSigValidity" SG_ 1993 PSB_GST_Byte7 0;
BA_ "NetworkRequest" SG_ 1993 PSB_GST_Byte7 0;
BA_ "NetworkRequestHoldingTime" SG_ 1993 PSB_GST_Byte7 5000;
BA_ "Version" SG_ 1993 PSB_GST_Byte7 "22.07.01";
BA_ "Description" SG_ 1993 PSB_GST_Byte1 "TP Index : 154";
BA_ "UsrSigPurpose" SG_ 1993 PSB_GST_Byte1 4;
BA_ "UserSigValidity" SG_ 1993 PSB_GST_Byte1 0;
BA_ "NetworkRequest" SG_ 1993 PSB_GST_Byte1 0;
BA_ "NetworkRequestHoldingTime" SG_ 1993 PSB_GST_Byte1 5000;
BA_ "Version" SG_ 1993 PSB_GST_Byte1 "22.07.01";
BA_ "GenSigStartValue" SG_ 1016 GNSS_MM_type 15;
BA_ "UserSigValidity" SG_ 1016 GNSS_MM_type 1;
BA_ "Version" SG_ 1016 GNSS_MM_type "21.08.01";
BA_ "Description" SG_ 1019 HU_MoodTherapyDrSeat "Moodtherapy Driver Seat On/Off";
BA_ "GenSigSendType" SG_ 1019 HU_MoodTherapyDrSeat 4;
BA_ "UserSigValidity" SG_ 1019 HU_MoodTherapyDrSeat 3;
BA_ "RoutingFactor" SG_ 1019 HU_MoodTherapyDrSeat 0;
BA_ "Version" SG_ 1019 HU_MoodTherapyDrSeat "20.07.13";
BA_ "Description" SG_ 1019 HU_VitalityFragrance "Vitality Fragrance On/Off";
BA_ "GenSigSendType" SG_ 1019 HU_VitalityFragrance 4;
BA_ "UserSigValidity" SG_ 1019 HU_VitalityFragrance 3;
BA_ "RoutingFactor" SG_ 1019 HU_VitalityFragrance 0;
BA_ "Version" SG_ 1019 HU_VitalityFragrance "20.07.13";
BA_ "Description" SG_ 1019 HU_VitalityCurtain "Vitality Curtain On/Off";
BA_ "GenSigSendType" SG_ 1019 HU_VitalityCurtain 4;
BA_ "UserSigValidity" SG_ 1019 HU_VitalityCurtain 3;
BA_ "RoutingFactor" SG_ 1019 HU_VitalityCurtain 0;
BA_ "Version" SG_ 1019 HU_VitalityCurtain "20.07.13";
BA_ "Description" SG_ 1019 HU_DelightMoodLamp "Delight MoodLamp On/Off";
BA_ "GenSigSendType" SG_ 1019 HU_DelightMoodLamp 4;
BA_ "UserSigValidity" SG_ 1019 HU_DelightMoodLamp 3;
BA_ "RoutingFactor" SG_ 1019 HU_DelightMoodLamp 0;
BA_ "Version" SG_ 1019 HU_DelightMoodLamp "20.07.13";
BA_ "Description" SG_ 1019 HU_DelightFragrance "Delight Fragrance On/Off";
BA_ "GenSigSendType" SG_ 1019 HU_DelightFragrance 4;
BA_ "UserSigValidity" SG_ 1019 HU_DelightFragrance 3;
BA_ "RoutingFactor" SG_ 1019 HU_DelightFragrance 0;
BA_ "Version" SG_ 1019 HU_DelightFragrance "20.07.13";
BA_ "Description" SG_ 1019 HU_DelightCurtain "Delight Curtain On/Off";
BA_ "GenSigSendType" SG_ 1019 HU_DelightCurtain 4;
BA_ "UserSigValidity" SG_ 1019 HU_DelightCurtain 3;
BA_ "RoutingFactor" SG_ 1019 HU_DelightCurtain 0;
BA_ "Version" SG_ 1019 HU_DelightCurtain "20.07.13";
BA_ "Description" SG_ 1019 HU_MoodTherapyPsSeat "Moodtherapy Passenger Seat On/Off";
BA_ "GenSigSendType" SG_ 1019 HU_MoodTherapyPsSeat 4;
BA_ "UserSigValidity" SG_ 1019 HU_MoodTherapyPsSeat 3;
BA_ "RoutingFactor" SG_ 1019 HU_MoodTherapyPsSeat 0;
BA_ "Version" SG_ 1019 HU_MoodTherapyPsSeat "20.07.13";
BA_ "Description" SG_ 1019 HU_CareMoodLamp "Care MoodLamp On/Off";
BA_ "GenSigSendType" SG_ 1019 HU_CareMoodLamp 4;
BA_ "UserSigValidity" SG_ 1019 HU_CareMoodLamp 3;
BA_ "RoutingFactor" SG_ 1019 HU_CareMoodLamp 0;
BA_ "Version" SG_ 1019 HU_CareMoodLamp "20.07.13";
BA_ "Description" SG_ 1019 HU_CareFragrance "Care Fragrance On/Off";
BA_ "GenSigSendType" SG_ 1019 HU_CareFragrance 4;
BA_ "UserSigValidity" SG_ 1019 HU_CareFragrance 3;
BA_ "RoutingFactor" SG_ 1019 HU_CareFragrance 0;
BA_ "Version" SG_ 1019 HU_CareFragrance "20.07.13";
BA_ "Description" SG_ 1019 HU_CareMassage "Care Massage On/Off";
BA_ "GenSigSendType" SG_ 1019 HU_CareMassage 4;
BA_ "UserSigValidity" SG_ 1019 HU_CareMassage 3;
BA_ "RoutingFactor" SG_ 1019 HU_CareMassage 0;
BA_ "Version" SG_ 1019 HU_CareMassage "20.07.13";
BA_ "Description" SG_ 1019 HU_CareCurtain "Care Curtain On/Off";
BA_ "GenSigSendType" SG_ 1019 HU_CareCurtain 4;
BA_ "UserSigValidity" SG_ 1019 HU_CareCurtain 3;
BA_ "RoutingFactor" SG_ 1019 HU_CareCurtain 0;
BA_ "Version" SG_ 1019 HU_CareCurtain "20.07.13";
BA_ "Description" SG_ 1019 HU_ComfortMoodLamp "Comfort MoodLamp On/Off";
BA_ "GenSigSendType" SG_ 1019 HU_ComfortMoodLamp 4;
BA_ "UserSigValidity" SG_ 1019 HU_ComfortMoodLamp 3;
BA_ "RoutingFactor" SG_ 1019 HU_ComfortMoodLamp 0;
BA_ "Version" SG_ 1019 HU_ComfortMoodLamp "20.07.13";
BA_ "Description" SG_ 1019 HU_ComfortFragrance "Comfort Fragrance On/Off";
BA_ "GenSigSendType" SG_ 1019 HU_ComfortFragrance 4;
BA_ "UserSigValidity" SG_ 1019 HU_ComfortFragrance 3;
BA_ "RoutingFactor" SG_ 1019 HU_ComfortFragrance 0;
BA_ "Version" SG_ 1019 HU_ComfortFragrance "20.07.13";
BA_ "Description" SG_ 1019 HU_ComfortMassage "Comfort Massage On/Off";
BA_ "GenSigSendType" SG_ 1019 HU_ComfortMassage 4;
BA_ "UserSigValidity" SG_ 1019 HU_ComfortMassage 3;
BA_ "RoutingFactor" SG_ 1019 HU_ComfortMassage 0;
BA_ "Version" SG_ 1019 HU_ComfortMassage "20.07.13";
BA_ "Description" SG_ 1019 HU_ComfortCurtain "Comfort Curtain On/Off";
BA_ "GenSigSendType" SG_ 1019 HU_ComfortCurtain 4;
BA_ "UserSigValidity" SG_ 1019 HU_ComfortCurtain 3;
BA_ "RoutingFactor" SG_ 1019 HU_ComfortCurtain 0;
BA_ "Version" SG_ 1019 HU_ComfortCurtain "20.07.13";
BA_ "Description" SG_ 1019 HU_MoodTherapyMode "Moodtherapy Mode Change Signal";
BA_ "GenSigSendType" SG_ 1019 HU_MoodTherapyMode 4;
BA_ "UserSigValidity" SG_ 1019 HU_MoodTherapyMode 3;
BA_ "RoutingFactor" SG_ 1019 HU_MoodTherapyMode 0;
BA_ "Version" SG_ 1019 HU_MoodTherapyMode "20.07.13";
BA_ "Description" SG_ 1019 HU_MoodTherapyRlSeat "Moodtherapy RearLeft Seat On/Off";
BA_ "GenSigSendType" SG_ 1019 HU_MoodTherapyRlSeat 4;
BA_ "UserSigValidity" SG_ 1019 HU_MoodTherapyRlSeat 3;
BA_ "RoutingFactor" SG_ 1019 HU_MoodTherapyRlSeat 0;
BA_ "Version" SG_ 1019 HU_MoodTherapyRlSeat "20.07.13";
BA_ "Description" SG_ 1019 HU_MoodTherapyRrSeat "Moodtherapy Rear Right Seat On/Off";
BA_ "GenSigSendType" SG_ 1019 HU_MoodTherapyRrSeat 4;
BA_ "UserSigValidity" SG_ 1019 HU_MoodTherapyRrSeat 3;
BA_ "RoutingFactor" SG_ 1019 HU_MoodTherapyRrSeat 0;
BA_ "Version" SG_ 1019 HU_MoodTherapyRrSeat "20.07.13";
BA_ "Description" SG_ 1019 HU_VitalityMoodLamp "Vitality MoodLamp On/Off";
BA_ "GenSigSendType" SG_ 1019 HU_VitalityMoodLamp 4;
BA_ "UserSigValidity" SG_ 1019 HU_VitalityMoodLamp 3;
BA_ "RoutingFactor" SG_ 1019 HU_VitalityMoodLamp 0;
BA_ "Version" SG_ 1019 HU_VitalityMoodLamp "20.07.13";
BA_ "Description" SG_ 2235651329 APSB_Crc1Val "The data area for CRC calculation is based on the data length (DLC) of the message DB.

The CRC shall be calculated over the entire data block (excluding the CRC bytes) including the user data, alive counter and Data ID



- CRC Polynomial (0x1021) , Ini";
BA_ "GenSigStartValue" SG_ 2235651329 APSB_Crc1Val 65535;
BA_ "UserSigValidity" SG_ 2235651329 APSB_Crc1Val 3;
BA_ "Version" SG_ 2235651329 APSB_Crc1Val "21.12.05";
BA_ "Description" SG_ 2235651329 APSB_AlvCnt1Val "For the first transmission request for a data element the counter shall be initialized with 0 and shall be incremented by 1 for every subsequent send request. 

When the counter reaches the maximum value(0xFF), then it shall restart with 0 for the next s";
BA_ "UserSigValidity" SG_ 2235651329 APSB_AlvCnt1Val 3;
BA_ "Version" SG_ 2235651329 APSB_AlvCnt1Val "21.12.05";
BA_ "Description" SG_ 2235651329 APSB_ConfTbl "This signal indicates supported signals that are correspond to detection type.

000000B : Not supported, 

xxxxx1B : Rough Road Impact 

xxxx1xB : FCA Impact

xxx1xxB : Minor Front Impact

xx1xxxB : Minor Side Impact

x1xxxxB : Minor Roll Detection

1xxx";
BA_ "UserSigValidity" SG_ 2235651329 APSB_ConfTbl 3;
BA_ "Version" SG_ 2235651329 APSB_ConfTbl "18.02.03";
BA_ "Description" SG_ 2235651329 APSB_CrashActvSta "This signal indicates status of APSB activation by ACU.";
BA_ "UserSigValidity" SG_ 2235651329 APSB_CrashActvSta 3;
BA_ "Version" SG_ 2235651329 APSB_CrashActvSta "18.02.03";
BA_ "Description" SG_ 2235651329 APSB_RRDrvImpt "This signal indicates commends of APSB activation in case of rough road impact.";
BA_ "UserSigValidity" SG_ 2235651329 APSB_RRDrvImpt 3;
BA_ "Version" SG_ 2235651329 APSB_RRDrvImpt "18.02.03";
BA_ "Description" SG_ 2235651329 APSB_FCAFrImpt "This signal indicates commends of APSB activation in case of FCA impact.";
BA_ "UserSigValidity" SG_ 2235651329 APSB_FCAFrImpt 3;
BA_ "Version" SG_ 2235651329 APSB_FCAFrImpt "18.02.03";
BA_ "Description" SG_ 2235651329 APSB_MinFrImpt "This signal indicates commends of APSB activation in case of minor frontal  impact.";
BA_ "UserSigValidity" SG_ 2235651329 APSB_MinFrImpt 3;
BA_ "Version" SG_ 2235651329 APSB_MinFrImpt "18.02.03";
BA_ "Description" SG_ 2235651329 APSB_MinSidImpt "This signal indicates commends of APSB activation in case of minor side  impact.";
BA_ "UserSigValidity" SG_ 2235651329 APSB_MinSidImpt 3;
BA_ "Version" SG_ 2235651329 APSB_MinSidImpt "18.02.03";
BA_ "Description" SG_ 2235651329 APSB_MinRollDetn "This signal indicates commends of APSB activation in case of minor rollover detection.";
BA_ "UserSigValidity" SG_ 2235651329 APSB_MinRollDetn 3;
BA_ "Version" SG_ 2235651329 APSB_MinRollDetn "18.02.03";
BA_ "Description" SG_ 2235651329 APSB_MinRearImpt "This signal indicates commends of APSB activation in case of minor rear impact.";
BA_ "UserSigValidity" SG_ 2235651329 APSB_MinRearImpt 3;
BA_ "Version" SG_ 2235651329 APSB_MinRearImpt "18.02.03";
BA_ "Description" SG_ 1015 HU_MM_Altitude "MSL

range = -40000 <= Value <= 1000000

unit = cm";
BA_ "UserSigValidity" SG_ 1015 HU_MM_Altitude 1;
BA_ "Version" SG_ 1015 HU_MM_Altitude "21.08.01";
BA_ "Description" SG_ 1015 HU_MM_Heading "range = 0<=Valud <360";
BA_ "UserSigValidity" SG_ 1015 HU_MM_Heading 1;
BA_ "Version" SG_ 1015 HU_MM_Heading "21.08.01";
BA_ "Description" SG_ 1956 GST_SCM_Byte0 "TP Index : 172";
BA_ "UsrSigPurpose" SG_ 1956 GST_SCM_Byte0 3;
BA_ "UserSigValidity" SG_ 1956 GST_SCM_Byte0 0;
BA_ "NetworkRequest" SG_ 1956 GST_SCM_Byte0 0;
BA_ "NetworkRequestHoldingTime" SG_ 1956 GST_SCM_Byte0 5000;
BA_ "Version" SG_ 1956 GST_SCM_Byte0 "21.02.04";
BA_ "Description" SG_ 1956 GST_SCM_Byte2 "TP Index : 172";
BA_ "UsrSigPurpose" SG_ 1956 GST_SCM_Byte2 3;
BA_ "UserSigValidity" SG_ 1956 GST_SCM_Byte2 0;
BA_ "NetworkRequest" SG_ 1956 GST_SCM_Byte2 0;
BA_ "NetworkRequestHoldingTime" SG_ 1956 GST_SCM_Byte2 5000;
BA_ "Version" SG_ 1956 GST_SCM_Byte2 "21.02.04";
BA_ "Description" SG_ 1956 GST_SCM_Byte3 "TP Index : 172";
BA_ "UsrSigPurpose" SG_ 1956 GST_SCM_Byte3 3;
BA_ "UserSigValidity" SG_ 1956 GST_SCM_Byte3 0;
BA_ "NetworkRequest" SG_ 1956 GST_SCM_Byte3 0;
BA_ "NetworkRequestHoldingTime" SG_ 1956 GST_SCM_Byte3 5000;
BA_ "Version" SG_ 1956 GST_SCM_Byte3 "21.02.04";
BA_ "Description" SG_ 1956 GST_SCM_Byte4 "TP Index : 172";
BA_ "UsrSigPurpose" SG_ 1956 GST_SCM_Byte4 3;
BA_ "UserSigValidity" SG_ 1956 GST_SCM_Byte4 0;
BA_ "NetworkRequest" SG_ 1956 GST_SCM_Byte4 0;
BA_ "NetworkRequestHoldingTime" SG_ 1956 GST_SCM_Byte4 5000;
BA_ "Version" SG_ 1956 GST_SCM_Byte4 "21.02.04";
BA_ "Description" SG_ 1956 GST_SCM_Byte5 "TP Index : 172";
BA_ "UsrSigPurpose" SG_ 1956 GST_SCM_Byte5 3;
BA_ "UserSigValidity" SG_ 1956 GST_SCM_Byte5 0;
BA_ "NetworkRequest" SG_ 1956 GST_SCM_Byte5 0;
BA_ "NetworkRequestHoldingTime" SG_ 1956 GST_SCM_Byte5 5000;
BA_ "Version" SG_ 1956 GST_SCM_Byte5 "21.02.04";
BA_ "Description" SG_ 1956 GST_SCM_Byte6 "TP Index : 172";
BA_ "UsrSigPurpose" SG_ 1956 GST_SCM_Byte6 3;
BA_ "UserSigValidity" SG_ 1956 GST_SCM_Byte6 0;
BA_ "NetworkRequest" SG_ 1956 GST_SCM_Byte6 0;
BA_ "NetworkRequestHoldingTime" SG_ 1956 GST_SCM_Byte6 5000;
BA_ "Version" SG_ 1956 GST_SCM_Byte6 "21.02.04";
BA_ "Description" SG_ 1956 GST_SCM_Byte7 "TP Index : 172";
BA_ "UsrSigPurpose" SG_ 1956 GST_SCM_Byte7 3;
BA_ "UserSigValidity" SG_ 1956 GST_SCM_Byte7 0;
BA_ "NetworkRequest" SG_ 1956 GST_SCM_Byte7 0;
BA_ "NetworkRequestHoldingTime" SG_ 1956 GST_SCM_Byte7 5000;
BA_ "Version" SG_ 1956 GST_SCM_Byte7 "21.02.04";
BA_ "Description" SG_ 1956 GST_SCM_Byte1 "TP Index : 172";
BA_ "UsrSigPurpose" SG_ 1956 GST_SCM_Byte1 3;
BA_ "UserSigValidity" SG_ 1956 GST_SCM_Byte1 0;
BA_ "NetworkRequest" SG_ 1956 GST_SCM_Byte1 0;
BA_ "NetworkRequestHoldingTime" SG_ 1956 GST_SCM_Byte1 5000;
BA_ "Version" SG_ 1956 GST_SCM_Byte1 "21.02.04";
BA_ "Description" SG_ 1959 GST_SWRC_Byte0 "TP Index : 175";
BA_ "UsrSigPurpose" SG_ 1959 GST_SWRC_Byte0 3;
BA_ "UserSigValidity" SG_ 1959 GST_SWRC_Byte0 0;
BA_ "NetworkRequest" SG_ 1959 GST_SWRC_Byte0 0;
BA_ "NetworkRequestHoldingTime" SG_ 1959 GST_SWRC_Byte0 5000;
BA_ "Version" SG_ 1959 GST_SWRC_Byte0 "21.02.04";
BA_ "Description" SG_ 1959 GST_SWRC_Byte2 "TP Index : 175";
BA_ "UsrSigPurpose" SG_ 1959 GST_SWRC_Byte2 3;
BA_ "UserSigValidity" SG_ 1959 GST_SWRC_Byte2 0;
BA_ "NetworkRequest" SG_ 1959 GST_SWRC_Byte2 0;
BA_ "NetworkRequestHoldingTime" SG_ 1959 GST_SWRC_Byte2 5000;
BA_ "Version" SG_ 1959 GST_SWRC_Byte2 "21.02.04";
BA_ "Description" SG_ 1959 GST_SWRC_Byte3 "TP Index : 175";
BA_ "UsrSigPurpose" SG_ 1959 GST_SWRC_Byte3 3;
BA_ "UserSigValidity" SG_ 1959 GST_SWRC_Byte3 0;
BA_ "NetworkRequest" SG_ 1959 GST_SWRC_Byte3 0;
BA_ "NetworkRequestHoldingTime" SG_ 1959 GST_SWRC_Byte3 5000;
BA_ "Version" SG_ 1959 GST_SWRC_Byte3 "21.02.04";
BA_ "Description" SG_ 1959 GST_SWRC_Byte4 "TP Index : 175";
BA_ "UsrSigPurpose" SG_ 1959 GST_SWRC_Byte4 3;
BA_ "UserSigValidity" SG_ 1959 GST_SWRC_Byte4 0;
BA_ "NetworkRequest" SG_ 1959 GST_SWRC_Byte4 0;
BA_ "NetworkRequestHoldingTime" SG_ 1959 GST_SWRC_Byte4 5000;
BA_ "Version" SG_ 1959 GST_SWRC_Byte4 "21.02.04";
BA_ "Description" SG_ 1959 GST_SWRC_Byte5 "TP Index : 175";
BA_ "UsrSigPurpose" SG_ 1959 GST_SWRC_Byte5 3;
BA_ "UserSigValidity" SG_ 1959 GST_SWRC_Byte5 0;
BA_ "NetworkRequest" SG_ 1959 GST_SWRC_Byte5 0;
BA_ "NetworkRequestHoldingTime" SG_ 1959 GST_SWRC_Byte5 5000;
BA_ "Version" SG_ 1959 GST_SWRC_Byte5 "21.02.04";
BA_ "Description" SG_ 1959 GST_SWRC_Byte6 "TP Index : 175";
BA_ "UsrSigPurpose" SG_ 1959 GST_SWRC_Byte6 3;
BA_ "UserSigValidity" SG_ 1959 GST_SWRC_Byte6 0;
BA_ "NetworkRequest" SG_ 1959 GST_SWRC_Byte6 0;
BA_ "NetworkRequestHoldingTime" SG_ 1959 GST_SWRC_Byte6 5000;
BA_ "Version" SG_ 1959 GST_SWRC_Byte6 "21.02.04";
BA_ "Description" SG_ 1959 GST_SWRC_Byte7 "TP Index : 175";
BA_ "UsrSigPurpose" SG_ 1959 GST_SWRC_Byte7 3;
BA_ "UserSigValidity" SG_ 1959 GST_SWRC_Byte7 0;
BA_ "NetworkRequest" SG_ 1959 GST_SWRC_Byte7 0;
BA_ "NetworkRequestHoldingTime" SG_ 1959 GST_SWRC_Byte7 5000;
BA_ "Version" SG_ 1959 GST_SWRC_Byte7 "21.02.04";
BA_ "Description" SG_ 1959 GST_SWRC_Byte1 "TP Index : 175";
BA_ "UsrSigPurpose" SG_ 1959 GST_SWRC_Byte1 3;
BA_ "UserSigValidity" SG_ 1959 GST_SWRC_Byte1 0;
BA_ "NetworkRequest" SG_ 1959 GST_SWRC_Byte1 0;
BA_ "NetworkRequestHoldingTime" SG_ 1959 GST_SWRC_Byte1 5000;
BA_ "Version" SG_ 1959 GST_SWRC_Byte1 "21.02.04";
BA_ "Description" SG_ 1003 PSM_BzrOnRLReq "PSM buzzer on command";
BA_ "GenSigSendType" SG_ 1003 PSM_BzrOnRLReq 4;
BA_ "UserSigValidity" SG_ 1003 PSM_BzrOnRLReq 0;
BA_ "NetworkRequest" SG_ 1003 PSM_BzrOnRLReq 0;
BA_ "NetworkRequestHoldingTime" SG_ 1003 PSM_BzrOnRLReq 5000;
BA_ "Version" SG_ 1003 PSM_BzrOnRLReq "17.11.00";
BA_ "Description" SG_ 1003 RLPSM_RearModeState "Rear Seat State for One Touch Mode";
BA_ "GenSigSendType" SG_ 1003 RLPSM_RearModeState 4;
BA_ "UserSigValidity" SG_ 1003 RLPSM_RearModeState 0;
BA_ "NetworkRequest" SG_ 1003 RLPSM_RearModeState 0;
BA_ "NetworkRequestHoldingTime" SG_ 1003 RLPSM_RearModeState 5000;
BA_ "Version" SG_ 1003 RLPSM_RearModeState "21.07.05";
BA_ "GenSigSendType" SG_ 1003 RLPSM_RLStEsyAcsUSMSta 4;
BA_ "UserSigValidity" SG_ 1003 RLPSM_RLStEsyAcsUSMSta 0;
BA_ "Version" SG_ 1003 RLPSM_RLStEsyAcsUSMSta "19.10.07";
BA_ "Description" SG_ 1003 RLPSM_RLSlidePosition "Rear Left Seat Slide Position (UNIT: mm, 1 Value ´ç 2mm)";
BA_ "GenSigSendType" SG_ 1003 RLPSM_RLSlidePosition 4;
BA_ "UserSigValidity" SG_ 1003 RLPSM_RLSlidePosition 0;
BA_ "NetworkRequest" SG_ 1003 RLPSM_RLSlidePosition 0;
BA_ "NetworkRequestHoldingTime" SG_ 1003 RLPSM_RLSlidePosition 5000;
BA_ "Version" SG_ 1003 RLPSM_RLSlidePosition "22.06.05";
BA_ "Description" SG_ 1003 RLPSM_SeatPos_Sta "The signal indicates the state of   Seat Meomry State";
BA_ "GenSigSendType" SG_ 1003 RLPSM_SeatPos_Sta 4;
BA_ "UserSigValidity" SG_ 1003 RLPSM_SeatPos_Sta 0;
BA_ "Version" SG_ 1003 RLPSM_SeatPos_Sta "20.03.01";
BA_ "Description" SG_ 1003 RLPSM_SeatPosSldLmt_Sta "RLPSM(Rear Left) Slide end Position and limit Initialize State information";
BA_ "GenSigSendType" SG_ 1003 RLPSM_SeatPosSldLmt_Sta 4;
BA_ "UserSigValidity" SG_ 1003 RLPSM_SeatPosSldLmt_Sta 0;
BA_ "NetworkRequest" SG_ 1003 RLPSM_SeatPosSldLmt_Sta 0;
BA_ "NetworkRequestHoldingTime" SG_ 1003 RLPSM_SeatPosSldLmt_Sta 5000;
BA_ "Version" SG_ 1003 RLPSM_SeatPosSldLmt_Sta "20.03.01";
BA_ "GenSigSendType" SG_ 1003 RLPSM_LimSetSta 4;
BA_ "UserSigValidity" SG_ 1003 RLPSM_LimSetSta 0;
BA_ "NetworkRequest" SG_ 1003 RLPSM_LimSetSta 0;
BA_ "NetworkRequestHoldingTime" SG_ 1003 RLPSM_LimSetSta 5000;
BA_ "Version" SG_ 1003 RLPSM_LimSetSta "21.04.01";
BA_ "Description" SG_ 1002 BLTN_CAM_HU_UI_Mode "Display control of Built-in Cam UI mode. This Signal for Ethernet Type Built-in Cam.";
BA_ "GenSigSendType" SG_ 1002 BLTN_CAM_HU_UI_Mode 4;
BA_ "UserSigValidity" SG_ 1002 BLTN_CAM_HU_UI_Mode 0;
BA_ "Version" SG_ 1002 BLTN_CAM_HU_UI_Mode "22.05.02";
BA_ "Description" SG_ 1002 BLTN_CAM_SD_Format_Op_State "BLTN_CAM SD card format operation status.";
BA_ "GenSigSendType" SG_ 1002 BLTN_CAM_SD_Format_Op_State 4;
BA_ "UserSigValidity" SG_ 1002 BLTN_CAM_SD_Format_Op_State 1;
BA_ "Version" SG_ 1002 BLTN_CAM_SD_Format_Op_State "21.07.04";
BA_ "Description" SG_ 1002 BLTN_CAM_PEV_Recorded "This Signal is sent just after the park event recorded.";
BA_ "GenSigSendType" SG_ 1002 BLTN_CAM_PEV_Recorded 4;
BA_ "UserSigValidity" SG_ 1002 BLTN_CAM_PEV_Recorded 1;
BA_ "NetworkRequest" SG_ 1002 BLTN_CAM_PEV_Recorded 0;
BA_ "NetworkRequestHoldingTime" SG_ 1002 BLTN_CAM_PEV_Recorded 1000;
BA_ "Version" SG_ 1002 BLTN_CAM_PEV_Recorded "21.12.00";
BA_ "Description" SG_ 1002 BLTN_CAM_PEV_Count "This Signal is count of park event record.";
BA_ "GenSigSendType" SG_ 1002 BLTN_CAM_PEV_Count 4;
BA_ "UserSigValidity" SG_ 1002 BLTN_CAM_PEV_Count 1;
BA_ "NetworkRequest" SG_ 1002 BLTN_CAM_PEV_Count 0;
BA_ "NetworkRequestHoldingTime" SG_ 1002 BLTN_CAM_PEV_Count 1000;
BA_ "Version" SG_ 1002 BLTN_CAM_PEV_Count "21.12.00";
BA_ "Description" SG_ 1002 BLTN_CAM_Ind_Req "This Signal is for HU Display Built-in Cam Indicator.";
BA_ "GenSigSendType" SG_ 1002 BLTN_CAM_Ind_Req 4;
BA_ "UserSigValidity" SG_ 1002 BLTN_CAM_Ind_Req 1;
BA_ "Version" SG_ 1002 BLTN_CAM_Ind_Req "21.07.04";
BA_ "Description" SG_ 1002 BLTN_CAM_LVDS_Mode_State "This Signal is for LVDS output status";
BA_ "GenSigSendType" SG_ 1002 BLTN_CAM_LVDS_Mode_State 4;
BA_ "UserSigValidity" SG_ 1002 BLTN_CAM_LVDS_Mode_State 1;
BA_ "Version" SG_ 1002 BLTN_CAM_LVDS_Mode_State "21.07.04";
BA_ "Description" SG_ 1002 BLTN_CAM_PrkOp_Termiate_Info "The signal for CCS service related with Built-in Cam Park operation termination.";
BA_ "GenSigSendType" SG_ 1002 BLTN_CAM_PrkOp_Termiate_Info 4;
BA_ "UserSigValidity" SG_ 1002 BLTN_CAM_PrkOp_Termiate_Info 0;
BA_ "NetworkRequest" SG_ 1002 BLTN_CAM_PrkOp_Termiate_Info 0;
BA_ "NetworkRequestHoldingTime" SG_ 1002 BLTN_CAM_PrkOp_Termiate_Info 1000;
BA_ "Version" SG_ 1002 BLTN_CAM_PrkOp_Termiate_Info "21.12.00";
BA_ "Description" SG_ 1002 BLTN_CAM_Display "Display control of Built-in Cam UI mode. This Signal for CAN Type Built-in Cam.(with Standard 5th Wide AVNT)";
BA_ "GenSigSendType" SG_ 1002 BLTN_CAM_Display 4;
BA_ "UserSigValidity" SG_ 1002 BLTN_CAM_Display 1;
BA_ "Version" SG_ 1002 BLTN_CAM_Display "21.07.04";
BA_ "Description" SG_ 1002 BLTN_CAM_WiFi_State "BLTN_CAM WiFi Stattus";
BA_ "GenSigSendType" SG_ 1002 BLTN_CAM_WiFi_State 4;
BA_ "UserSigValidity" SG_ 1002 BLTN_CAM_WiFi_State 1;
BA_ "Version" SG_ 1002 BLTN_CAM_WiFi_State "21.07.04";
BA_ "Description" SG_ 1005 RLPSU_FldDis "2nd Left side seat moving state  : Folding";
BA_ "GenSigSendType" SG_ 1005 RLPSU_FldDis 4;
BA_ "UserSigValidity" SG_ 1005 RLPSU_FldDis 0;
BA_ "Version" SG_ 1005 RLPSU_FldDis "18.09.01";
BA_ "Description" SG_ 1005 RLPSU_TiltDownDis "2nd Left side seat moving state  : Tilt down";
BA_ "GenSigSendType" SG_ 1005 RLPSU_TiltDownDis 4;
BA_ "UserSigValidity" SG_ 1005 RLPSU_TiltDownDis 0;
BA_ "Version" SG_ 1005 RLPSU_TiltDownDis "18.09.01";
BA_ "Description" SG_ 1005 RLPSU_RclFwdDis "2nd Left side seat moving state  : Recline Forward";
BA_ "GenSigSendType" SG_ 1005 RLPSU_RclFwdDis 4;
BA_ "UserSigValidity" SG_ 1005 RLPSU_RclFwdDis 0;
BA_ "Version" SG_ 1005 RLPSU_RclFwdDis "18.09.01";
BA_ "Description" SG_ 1005 RLPSU_RclBwdDis "2nd Left side seat moving state  : Recline Backward";
BA_ "GenSigSendType" SG_ 1005 RLPSU_RclBwdDis 4;
BA_ "UserSigValidity" SG_ 1005 RLPSU_RclBwdDis 0;
BA_ "Version" SG_ 1005 RLPSU_RclBwdDis "18.09.01";
BA_ "Description" SG_ 1005 RLPSU_RlxModeDis "2nd Left side seat moving state  : Relax mode";
BA_ "GenSigSendType" SG_ 1005 RLPSU_RlxModeDis 4;
BA_ "UserSigValidity" SG_ 1005 RLPSU_RlxModeDis 0;
BA_ "Version" SG_ 1005 RLPSU_RlxModeDis "18.09.02";
BA_ "Description" SG_ 1005 RLPSU_Folding_SW "Interlocking signal between DPSM and RLPSU";
BA_ "GenSigSendType" SG_ 1005 RLPSU_Folding_SW 4;
BA_ "UserSigValidity" SG_ 1005 RLPSU_Folding_SW 0;
BA_ "Version" SG_ 1005 RLPSU_Folding_SW "18.09.01";
BA_ "Description" SG_ 1005 RLPSU_UnFldDis "2nd Left side seat moving state  : UnFolding";
BA_ "GenSigSendType" SG_ 1005 RLPSU_UnFldDis 4;
BA_ "UserSigValidity" SG_ 1005 RLPSU_UnFldDis 0;
BA_ "Version" SG_ 1005 RLPSU_UnFldDis "18.09.01";
BA_ "Description" SG_ 1005 RLPSU_Unfolding_SW "Interlocking signal between DPSM and RLPSU";
BA_ "GenSigSendType" SG_ 1005 RLPSU_Unfolding_SW 4;
BA_ "UserSigValidity" SG_ 1005 RLPSU_Unfolding_SW 0;
BA_ "Version" SG_ 1005 RLPSU_Unfolding_SW "18.09.01";
BA_ "Description" SG_ 1005 RLPSU_WalkIn_SW "Interlocking signal between DPSM and RLPSU";
BA_ "GenSigSendType" SG_ 1005 RLPSU_WalkIn_SW 4;
BA_ "UserSigValidity" SG_ 1005 RLPSU_WalkIn_SW 0;
BA_ "Version" SG_ 1005 RLPSU_WalkIn_SW "18.09.01";
BA_ "Description" SG_ 1005 RLPSU_UnwalkIn_SW "Interlocking signal between DPSM and RLPSU";
BA_ "GenSigSendType" SG_ 1005 RLPSU_UnwalkIn_SW 4;
BA_ "UserSigValidity" SG_ 1005 RLPSU_UnwalkIn_SW 0;
BA_ "Version" SG_ 1005 RLPSU_UnwalkIn_SW "18.09.01";
BA_ "Description" SG_ 1005 RLPSU_Folding_Postion "RLPSU Position Information";
BA_ "GenSigSendType" SG_ 1005 RLPSU_Folding_Postion 4;
BA_ "UserSigValidity" SG_ 1005 RLPSU_Folding_Postion 0;
BA_ "Version" SG_ 1005 RLPSU_Folding_Postion "21.07.06";
BA_ "Description" SG_ 1005 RLPSU_Folding_State_PopUp "Rear LH seat Folding State information";
BA_ "GenSigSendType" SG_ 1005 RLPSU_Folding_State_PopUp 4;
BA_ "UserSigValidity" SG_ 1005 RLPSU_Folding_State_PopUp 0;
BA_ "Version" SG_ 1005 RLPSU_Folding_State_PopUp "21.07.06";
BA_ "Description" SG_ 1005 RLPSU_Relax_State_Popup "Rear LH seat Relax State information";
BA_ "GenSigSendType" SG_ 1005 RLPSU_Relax_State_Popup 4;
BA_ "UserSigValidity" SG_ 1005 RLPSU_Relax_State_Popup 0;
BA_ "Version" SG_ 1005 RLPSU_Relax_State_Popup "21.07.06";
BA_ "Description" SG_ 1005 RLPSU_SlideFwdDis "2nd Left side seat moving state  : Slide Forward";
BA_ "GenSigSendType" SG_ 1005 RLPSU_SlideFwdDis 4;
BA_ "UserSigValidity" SG_ 1005 RLPSU_SlideFwdDis 0;
BA_ "Version" SG_ 1005 RLPSU_SlideFwdDis "19.03.05";
BA_ "Description" SG_ 1005 RLPSU_SlideBwdDis "2nd Left side seat moving state  : Slide Backward";
BA_ "GenSigSendType" SG_ 1005 RLPSU_SlideBwdDis 4;
BA_ "UserSigValidity" SG_ 1005 RLPSU_SlideBwdDis 0;
BA_ "Version" SG_ 1005 RLPSU_SlideBwdDis "19.03.05";
BA_ "Description" SG_ 1005 RLPSU_WalkInDis "2nd Left side seat moving state : Walk In";
BA_ "GenSigSendType" SG_ 1005 RLPSU_WalkInDis 4;
BA_ "UserSigValidity" SG_ 1005 RLPSU_WalkInDis 0;
BA_ "Version" SG_ 1005 RLPSU_WalkInDis "18.09.01";
BA_ "Description" SG_ 1005 RLPSU_WalkInState "2nd Left side seat Walk-in Ready state";
BA_ "GenSigSendType" SG_ 1005 RLPSU_WalkInState 4;
BA_ "UserSigValidity" SG_ 1005 RLPSU_WalkInState 0;
BA_ "Version" SG_ 1005 RLPSU_WalkInState "19.03.05";
BA_ "Description" SG_ 1005 RLPSU_UnWalkInDis "2nd Left side seat moving state : Un Walk In";
BA_ "GenSigSendType" SG_ 1005 RLPSU_UnWalkInDis 4;
BA_ "UserSigValidity" SG_ 1005 RLPSU_UnWalkInDis 0;
BA_ "Version" SG_ 1005 RLPSU_UnWalkInDis "18.09.01";
BA_ "Description" SG_ 1005 RLPSU_TiltUpDis "2nd Left side seat moving state  : Tilt up";
BA_ "GenSigSendType" SG_ 1005 RLPSU_TiltUpDis 4;
BA_ "UserSigValidity" SG_ 1005 RLPSU_TiltUpDis 0;
BA_ "Version" SG_ 1005 RLPSU_TiltUpDis "18.09.01";
BA_ "Description" SG_ 1004 CF_RCS_SwTyp "Road Control Switch Type";
BA_ "GenSigSendType" SG_ 1004 CF_RCS_SwTyp 4;
BA_ "UserSigValidity" SG_ 1004 CF_RCS_SwTyp 0;
BA_ "RoutingFactor" SG_ 1004 CF_RCS_SwTyp 0;
BA_ "Version" SG_ 1004 CF_RCS_SwTyp "18.10.02";
BA_ "Description" SG_ 1004 CF_RCS_OffRoad "RCS OffRoad mode status";
BA_ "GenSigSendType" SG_ 1004 CF_RCS_OffRoad 4;
BA_ "UserSigValidity" SG_ 1004 CF_RCS_OffRoad 3;
BA_ "RoutingFactor" SG_ 1004 CF_RCS_OffRoad 0;
BA_ "Version" SG_ 1004 CF_RCS_OffRoad "20.01.01";
BA_ "Description" SG_ 1004 CF_RCS_BtnSta "RCS Button Status";
BA_ "GenSigSendType" SG_ 1004 CF_RCS_BtnSta 4;
BA_ "UserSigValidity" SG_ 1004 CF_RCS_BtnSta 3;
BA_ "RoutingFactor" SG_ 1004 CF_RCS_BtnSta 0;
BA_ "Version" SG_ 1004 CF_RCS_BtnSta "18.10.02";
BA_ "Description" SG_ 1004 CF_RCS_RotateEnd "signal to inform end of rotate";
BA_ "GenSigSendType" SG_ 1004 CF_RCS_RotateEnd 4;
BA_ "UserSigValidity" SG_ 1004 CF_RCS_RotateEnd 3;
BA_ "RoutingFactor" SG_ 1004 CF_RCS_RotateEnd 0;
BA_ "Version" SG_ 1004 CF_RCS_RotateEnd "18.10.02";
BA_ "Description" SG_ 1004 CF_RCS_4wdLocking "4wd locking on/off signal";
BA_ "GenSigSendType" SG_ 1004 CF_RCS_4wdLocking 4;
BA_ "UserSigValidity" SG_ 1004 CF_RCS_4wdLocking 3;
BA_ "RoutingFactor" SG_ 1004 CF_RCS_4wdLocking 0;
BA_ "Version" SG_ 1004 CF_RCS_4wdLocking "18.10.02";
BA_ "GenSigSendType" SG_ 1004 RCS_Direction_SW 4;
BA_ "UserSigValidity" SG_ 1004 RCS_Direction_SW 3;
BA_ "NetworkRequest" SG_ 1004 RCS_Direction_SW 0;
BA_ "NetworkRequestHoldingTime" SG_ 1004 RCS_Direction_SW 5000;
BA_ "RoutingFactor" SG_ 1004 RCS_Direction_SW 0;
BA_ "Version" SG_ 1004 RCS_Direction_SW "22.06.05";
BA_ "Description" SG_ 1004 CF_RCS_DrvMod "RCS drive mode select status";
BA_ "GenSigSendType" SG_ 1004 CF_RCS_DrvMod 4;
BA_ "UserSigValidity" SG_ 1004 CF_RCS_DrvMod 3;
BA_ "RoutingFactor" SG_ 1004 CF_RCS_DrvMod 0;
BA_ "Version" SG_ 1004 CF_RCS_DrvMod "18.10.02";
BA_ "GenSigSendType" SG_ 1004 RCS_Mode_SW 4;
BA_ "UserSigValidity" SG_ 1004 RCS_Mode_SW 3;
BA_ "NetworkRequest" SG_ 1004 RCS_Mode_SW 0;
BA_ "NetworkRequestHoldingTime" SG_ 1004 RCS_Mode_SW 5000;
BA_ "RoutingFactor" SG_ 1004 RCS_Mode_SW 0;
BA_ "Version" SG_ 1004 RCS_Mode_SW "22.06.05";
BA_ "Description" SG_ 1004 CF_RCS_TowMode "Tow Mode On/off Switch signal";
BA_ "GenSigSendType" SG_ 1004 CF_RCS_TowMode 4;
BA_ "UserSigValidity" SG_ 1004 CF_RCS_TowMode 3;
BA_ "RoutingFactor" SG_ 1004 CF_RCS_TowMode 0;
BA_ "Version" SG_ 1004 CF_RCS_TowMode "22.04.01";
BA_ "Description" SG_ 1955 GST_DPSU_Byte0 "TP Index : 156";
BA_ "UsrSigPurpose" SG_ 1955 GST_DPSU_Byte0 3;
BA_ "UserSigValidity" SG_ 1955 GST_DPSU_Byte0 0;
BA_ "NetworkRequest" SG_ 1955 GST_DPSU_Byte0 0;
BA_ "NetworkRequestHoldingTime" SG_ 1955 GST_DPSU_Byte0 5000;
BA_ "Version" SG_ 1955 GST_DPSU_Byte0 "21.11.07";
BA_ "Description" SG_ 1955 GST_DPSU_Byte2 "TP Index : 156";
BA_ "UsrSigPurpose" SG_ 1955 GST_DPSU_Byte2 3;
BA_ "UserSigValidity" SG_ 1955 GST_DPSU_Byte2 0;
BA_ "NetworkRequest" SG_ 1955 GST_DPSU_Byte2 0;
BA_ "NetworkRequestHoldingTime" SG_ 1955 GST_DPSU_Byte2 5000;
BA_ "Version" SG_ 1955 GST_DPSU_Byte2 "21.11.07";
BA_ "Description" SG_ 1955 GST_DPSU_Byte3 "TP Index : 156";
BA_ "UsrSigPurpose" SG_ 1955 GST_DPSU_Byte3 3;
BA_ "UserSigValidity" SG_ 1955 GST_DPSU_Byte3 0;
BA_ "NetworkRequest" SG_ 1955 GST_DPSU_Byte3 0;
BA_ "NetworkRequestHoldingTime" SG_ 1955 GST_DPSU_Byte3 5000;
BA_ "Version" SG_ 1955 GST_DPSU_Byte3 "21.11.07";
BA_ "Description" SG_ 1955 GST_DPSU_Byte4 "TP Index : 156";
BA_ "UsrSigPurpose" SG_ 1955 GST_DPSU_Byte4 3;
BA_ "UserSigValidity" SG_ 1955 GST_DPSU_Byte4 0;
BA_ "NetworkRequest" SG_ 1955 GST_DPSU_Byte4 0;
BA_ "NetworkRequestHoldingTime" SG_ 1955 GST_DPSU_Byte4 5000;
BA_ "Version" SG_ 1955 GST_DPSU_Byte4 "21.11.07";
BA_ "Description" SG_ 1955 GST_DPSU_Byte5 "TP Index : 156";
BA_ "UsrSigPurpose" SG_ 1955 GST_DPSU_Byte5 3;
BA_ "UserSigValidity" SG_ 1955 GST_DPSU_Byte5 0;
BA_ "NetworkRequest" SG_ 1955 GST_DPSU_Byte5 0;
BA_ "NetworkRequestHoldingTime" SG_ 1955 GST_DPSU_Byte5 5000;
BA_ "Version" SG_ 1955 GST_DPSU_Byte5 "21.11.07";
BA_ "Description" SG_ 1955 GST_DPSU_Byte6 "TP Index : 156";
BA_ "UsrSigPurpose" SG_ 1955 GST_DPSU_Byte6 3;
BA_ "UserSigValidity" SG_ 1955 GST_DPSU_Byte6 0;
BA_ "NetworkRequest" SG_ 1955 GST_DPSU_Byte6 0;
BA_ "NetworkRequestHoldingTime" SG_ 1955 GST_DPSU_Byte6 5000;
BA_ "Version" SG_ 1955 GST_DPSU_Byte6 "21.11.07";
BA_ "Description" SG_ 1955 GST_DPSU_Byte7 "TP Index : 156";
BA_ "UsrSigPurpose" SG_ 1955 GST_DPSU_Byte7 3;
BA_ "UserSigValidity" SG_ 1955 GST_DPSU_Byte7 0;
BA_ "NetworkRequest" SG_ 1955 GST_DPSU_Byte7 0;
BA_ "NetworkRequestHoldingTime" SG_ 1955 GST_DPSU_Byte7 5000;
BA_ "Version" SG_ 1955 GST_DPSU_Byte7 "21.11.07";
BA_ "Description" SG_ 1955 GST_DPSU_Byte1 "TP Index : 156";
BA_ "UsrSigPurpose" SG_ 1955 GST_DPSU_Byte1 3;
BA_ "UserSigValidity" SG_ 1955 GST_DPSU_Byte1 0;
BA_ "NetworkRequest" SG_ 1955 GST_DPSU_Byte1 0;
BA_ "NetworkRequestHoldingTime" SG_ 1955 GST_DPSU_Byte1 5000;
BA_ "Version" SG_ 1955 GST_DPSU_Byte1 "21.11.07";
BA_ "Description" SG_ 1007 ATS_LEDBgtnsUpDn "This signal is  interior lamp brightness up/down control signal";
BA_ "GenSigSendType" SG_ 1007 ATS_LEDBgtnsUpDn 4;
BA_ "UserSigValidity" SG_ 1007 ATS_LEDBgtnsUpDn 3;
BA_ "Version" SG_ 1007 ATS_LEDBgtnsUpDn "20.04.05";
BA_ "Description" SG_ 1007 ATS_FrMoodOn_Req "Front mood lamp On/Off request";
BA_ "GenSigSendType" SG_ 1007 ATS_FrMoodOn_Req 4;
BA_ "UserSigValidity" SG_ 1007 ATS_FrMoodOn_Req 3;
BA_ "NetworkRequest" SG_ 1007 ATS_FrMoodOn_Req 0;
BA_ "NetworkRequestHoldingTime" SG_ 1007 ATS_FrMoodOn_Req 5000;
BA_ "Version" SG_ 1007 ATS_FrMoodOn_Req "20.06.09";
BA_ "Description" SG_ 1007 ATS_DoorOn_Req "Front Door switch On/Off request";
BA_ "GenSigSendType" SG_ 1007 ATS_DoorOn_Req 4;
BA_ "UserSigValidity" SG_ 1007 ATS_DoorOn_Req 3;
BA_ "NetworkRequest" SG_ 1007 ATS_DoorOn_Req 0;
BA_ "NetworkRequestHoldingTime" SG_ 1007 ATS_DoorOn_Req 5000;
BA_ "Version" SG_ 1007 ATS_DoorOn_Req "20.06.09";
BA_ "Description" SG_ 1007 ATS_RrMapLftOn_Req "Rear left map lamp On/Off request";
BA_ "GenSigSendType" SG_ 1007 ATS_RrMapLftOn_Req 4;
BA_ "UserSigValidity" SG_ 1007 ATS_RrMapLftOn_Req 3;
BA_ "NetworkRequest" SG_ 1007 ATS_RrMapLftOn_Req 0;
BA_ "NetworkRequestHoldingTime" SG_ 1007 ATS_RrMapLftOn_Req 5000;
BA_ "Version" SG_ 1007 ATS_RrMapLftOn_Req "20.06.09";
BA_ "Description" SG_ 1007 ATS_RrMapRtOn_Req "Rear right map lamp On/Off request";
BA_ "GenSigSendType" SG_ 1007 ATS_RrMapRtOn_Req 4;
BA_ "UserSigValidity" SG_ 1007 ATS_RrMapRtOn_Req 3;
BA_ "NetworkRequest" SG_ 1007 ATS_RrMapRtOn_Req 0;
BA_ "NetworkRequestHoldingTime" SG_ 1007 ATS_RrMapRtOn_Req 5000;
BA_ "Version" SG_ 1007 ATS_RrMapRtOn_Req "20.06.09";
BA_ "Description" SG_ 1007 ATS_RrRoomOn_Req "Rear room lamp On/Off request";
BA_ "GenSigSendType" SG_ 1007 ATS_RrRoomOn_Req 4;
BA_ "UserSigValidity" SG_ 1007 ATS_RrRoomOn_Req 3;
BA_ "NetworkRequest" SG_ 1007 ATS_RrRoomOn_Req 0;
BA_ "NetworkRequestHoldingTime" SG_ 1007 ATS_RrRoomOn_Req 5000;
BA_ "Version" SG_ 1007 ATS_RrRoomOn_Req "20.06.09";
BA_ "Description" SG_ 1007 ATS_LEDClrUpDn "This signal is  interior lamp color up/down control signal";
BA_ "GenSigSendType" SG_ 1007 ATS_LEDClrUpDn 4;
BA_ "UserSigValidity" SG_ 1007 ATS_LEDClrUpDn 3;
BA_ "Version" SG_ 1007 ATS_LEDClrUpDn "20.04.05";
BA_ "Description" SG_ 1007 ATS_RrMoodOn_Req "Rear mood lamp On/Off request";
BA_ "GenSigSendType" SG_ 1007 ATS_RrMoodOn_Req 4;
BA_ "UserSigValidity" SG_ 1007 ATS_RrMoodOn_Req 3;
BA_ "NetworkRequest" SG_ 1007 ATS_RrMoodOn_Req 0;
BA_ "NetworkRequestHoldingTime" SG_ 1007 ATS_RrMoodOn_Req 5000;
BA_ "Version" SG_ 1007 ATS_RrMoodOn_Req "20.06.09";
BA_ "Description" SG_ 1007 ATS_LEDClr_Set "Interior Lamp LED Color Request";
BA_ "GenSigSendType" SG_ 1007 ATS_LEDClr_Set 4;
BA_ "UserSigValidity" SG_ 1007 ATS_LEDClr_Set 3;
BA_ "NetworkRequest" SG_ 1007 ATS_LEDClr_Set 0;
BA_ "NetworkRequestHoldingTime" SG_ 1007 ATS_LEDClr_Set 5000;
BA_ "Version" SG_ 1007 ATS_LEDClr_Set "20.06.09";
BA_ "Description" SG_ 1007 ATS_LEDBgtns_Set "Interior Lamp LED Brightness Request";
BA_ "GenSigSendType" SG_ 1007 ATS_LEDBgtns_Set 4;
BA_ "UserSigValidity" SG_ 1007 ATS_LEDBgtns_Set 3;
BA_ "NetworkRequest" SG_ 1007 ATS_LEDBgtns_Set 0;
BA_ "NetworkRequestHoldingTime" SG_ 1007 ATS_LEDBgtns_Set 5000;
BA_ "Version" SG_ 1007 ATS_LEDBgtns_Set "20.06.09";
BA_ "Description" SG_ 1007 ATS_LEDClrUpDnBtn "This signal is  interior lamp color up/down button control signal";
BA_ "GenSigSendType" SG_ 1007 ATS_LEDClrUpDnBtn 4;
BA_ "UserSigValidity" SG_ 1007 ATS_LEDClrUpDnBtn 3;
BA_ "Version" SG_ 1007 ATS_LEDClrUpDnBtn "20.06.07";
BA_ "Description" SG_ 1007 ATS_LEDBgtnsUpDnBtn "This signal is  interior lamp brightness up/down button control signal";
BA_ "GenSigSendType" SG_ 1007 ATS_LEDBgtnsUpDnBtn 4;
BA_ "UserSigValidity" SG_ 1007 ATS_LEDBgtnsUpDnBtn 3;
BA_ "Version" SG_ 1007 ATS_LEDBgtnsUpDnBtn "20.06.07";
BA_ "Description" SG_ 1007 ATS_FrMapLftOn_Req "Front left map lamp On/Off request";
BA_ "GenSigSendType" SG_ 1007 ATS_FrMapLftOn_Req 4;
BA_ "UserSigValidity" SG_ 1007 ATS_FrMapLftOn_Req 3;
BA_ "NetworkRequest" SG_ 1007 ATS_FrMapLftOn_Req 0;
BA_ "NetworkRequestHoldingTime" SG_ 1007 ATS_FrMapLftOn_Req 5000;
BA_ "Version" SG_ 1007 ATS_FrMapLftOn_Req "20.06.09";
BA_ "Description" SG_ 1007 ATS_FrMapRtOn_Req "Front right map lamp On/Off request";
BA_ "GenSigSendType" SG_ 1007 ATS_FrMapRtOn_Req 4;
BA_ "UserSigValidity" SG_ 1007 ATS_FrMapRtOn_Req 3;
BA_ "NetworkRequest" SG_ 1007 ATS_FrMapRtOn_Req 0;
BA_ "NetworkRequestHoldingTime" SG_ 1007 ATS_FrMapRtOn_Req 5000;
BA_ "Version" SG_ 1007 ATS_FrMapRtOn_Req "20.06.09";
BA_ "Description" SG_ 1007 ATS_FrRoomOn_Req "Front room lamp On/Off request";
BA_ "GenSigSendType" SG_ 1007 ATS_FrRoomOn_Req 4;
BA_ "UserSigValidity" SG_ 1007 ATS_FrRoomOn_Req 3;
BA_ "NetworkRequest" SG_ 1007 ATS_FrRoomOn_Req 0;
BA_ "NetworkRequestHoldingTime" SG_ 1007 ATS_FrRoomOn_Req 5000;
BA_ "Version" SG_ 1007 ATS_FrRoomOn_Req "20.06.09";
BA_ "Description" SG_ 1006 RRPSU_FldDis "2nd Right side seat moving state  : Folding";
BA_ "GenSigSendType" SG_ 1006 RRPSU_FldDis 4;
BA_ "UserSigValidity" SG_ 1006 RRPSU_FldDis 0;
BA_ "Version" SG_ 1006 RRPSU_FldDis "18.09.01";
BA_ "Description" SG_ 1006 RRPSU_TiltDnDis "2nd Right side seat moving state  : Tilt down";
BA_ "GenSigSendType" SG_ 1006 RRPSU_TiltDnDis 4;
BA_ "UserSigValidity" SG_ 1006 RRPSU_TiltDnDis 0;
BA_ "Version" SG_ 1006 RRPSU_TiltDnDis "18.09.01";
BA_ "Description" SG_ 1006 RRPSU_RecFwdDis "2nd Right side seat moving state  : Recline Forward";
BA_ "GenSigSendType" SG_ 1006 RRPSU_RecFwdDis 4;
BA_ "UserSigValidity" SG_ 1006 RRPSU_RecFwdDis 0;
BA_ "Version" SG_ 1006 RRPSU_RecFwdDis "18.09.01";
BA_ "Description" SG_ 1006 RRPSU_RecBwdDis "2nd Right side seat moving state  : Recline Backward";
BA_ "GenSigSendType" SG_ 1006 RRPSU_RecBwdDis 4;
BA_ "UserSigValidity" SG_ 1006 RRPSU_RecBwdDis 0;
BA_ "Version" SG_ 1006 RRPSU_RecBwdDis "18.09.01";
BA_ "Description" SG_ 1006 RRPSU_RlxModeDis "2nd Right side seat moving state  : Relax mode";
BA_ "GenSigSendType" SG_ 1006 RRPSU_RlxModeDis 4;
BA_ "UserSigValidity" SG_ 1006 RRPSU_RlxModeDis 0;
BA_ "Version" SG_ 1006 RRPSU_RlxModeDis "18.09.02";
BA_ "Description" SG_ 1006 RRPSU_Folding_SW "Interlocking signal between DPSM and RRPSU";
BA_ "GenSigSendType" SG_ 1006 RRPSU_Folding_SW 4;
BA_ "UserSigValidity" SG_ 1006 RRPSU_Folding_SW 0;
BA_ "Version" SG_ 1006 RRPSU_Folding_SW "19.03.05";
BA_ "Description" SG_ 1006 RRPSU_UnFldDis "2nd Right side seat moving state  : UnFolding";
BA_ "GenSigSendType" SG_ 1006 RRPSU_UnFldDis 4;
BA_ "UserSigValidity" SG_ 1006 RRPSU_UnFldDis 0;
BA_ "Version" SG_ 1006 RRPSU_UnFldDis "18.09.01";
BA_ "Description" SG_ 1006 RRPSU_Unfolding_SW "Interlocking signal between DPSM and RRPSU";
BA_ "GenSigSendType" SG_ 1006 RRPSU_Unfolding_SW 4;
BA_ "UserSigValidity" SG_ 1006 RRPSU_Unfolding_SW 0;
BA_ "Version" SG_ 1006 RRPSU_Unfolding_SW "19.03.05";
BA_ "Description" SG_ 1006 RRPSU_WalkIn_SW "Interlocking signal between DPSM and RRPSU";
BA_ "GenSigSendType" SG_ 1006 RRPSU_WalkIn_SW 4;
BA_ "UserSigValidity" SG_ 1006 RRPSU_WalkIn_SW 0;
BA_ "Version" SG_ 1006 RRPSU_WalkIn_SW "19.03.05";
BA_ "Description" SG_ 1006 RRPSU_UnwalkIn_SW "Interlocking signal between DPSM and RRPSU";
BA_ "GenSigSendType" SG_ 1006 RRPSU_UnwalkIn_SW 4;
BA_ "UserSigValidity" SG_ 1006 RRPSU_UnwalkIn_SW 0;
BA_ "Version" SG_ 1006 RRPSU_UnwalkIn_SW "19.03.05";
BA_ "Description" SG_ 1006 RRPSU_Folding_Postion "RRPSU Position Information";
BA_ "GenSigSendType" SG_ 1006 RRPSU_Folding_Postion 4;
BA_ "UserSigValidity" SG_ 1006 RRPSU_Folding_Postion 0;
BA_ "Version" SG_ 1006 RRPSU_Folding_Postion "19.03.05";
BA_ "Description" SG_ 1006 RRPSU_Folding_State_Popup "Rear RH seat Folding State information";
BA_ "GenSigSendType" SG_ 1006 RRPSU_Folding_State_Popup 4;
BA_ "UserSigValidity" SG_ 1006 RRPSU_Folding_State_Popup 0;
BA_ "Version" SG_ 1006 RRPSU_Folding_State_Popup "18.10.02";
BA_ "Description" SG_ 1006 RRPSU_Relax_State_Popup "Rear RH seat Relax State information";
BA_ "GenSigSendType" SG_ 1006 RRPSU_Relax_State_Popup 4;
BA_ "UserSigValidity" SG_ 1006 RRPSU_Relax_State_Popup 0;
BA_ "Version" SG_ 1006 RRPSU_Relax_State_Popup "18.10.02";
BA_ "Description" SG_ 1006 RRPSU_SlideFwdDis "2nd Right side seat moving state  : Slide Forward";
BA_ "GenSigSendType" SG_ 1006 RRPSU_SlideFwdDis 4;
BA_ "UserSigValidity" SG_ 1006 RRPSU_SlideFwdDis 0;
BA_ "Version" SG_ 1006 RRPSU_SlideFwdDis "19.03.05";
BA_ "Description" SG_ 1006 RRPSU_SlideBwdDis "2nd Right side seat moving state  : Slide Backward";
BA_ "GenSigSendType" SG_ 1006 RRPSU_SlideBwdDis 4;
BA_ "UserSigValidity" SG_ 1006 RRPSU_SlideBwdDis 0;
BA_ "Version" SG_ 1006 RRPSU_SlideBwdDis "19.03.05";
BA_ "Description" SG_ 1006 RRPSU_WalkinDis "2nd Right side seat moving state : Walk In";
BA_ "GenSigSendType" SG_ 1006 RRPSU_WalkinDis 4;
BA_ "UserSigValidity" SG_ 1006 RRPSU_WalkinDis 0;
BA_ "Version" SG_ 1006 RRPSU_WalkinDis "18.09.01";
BA_ "Description" SG_ 1006 RRPSU_WalkInState "2nd Right side seat Walk-in Ready state";
BA_ "GenSigSendType" SG_ 1006 RRPSU_WalkInState 4;
BA_ "UserSigValidity" SG_ 1006 RRPSU_WalkInState 0;
BA_ "Version" SG_ 1006 RRPSU_WalkInState "19.03.05";
BA_ "Description" SG_ 1006 RRPSU_UnwalkinDis "2nd Right side seat moving state : Un Walk In";
BA_ "GenSigSendType" SG_ 1006 RRPSU_UnwalkinDis 4;
BA_ "UserSigValidity" SG_ 1006 RRPSU_UnwalkinDis 0;
BA_ "Version" SG_ 1006 RRPSU_UnwalkinDis "18.09.01";
BA_ "Description" SG_ 1006 RRPSU_TiltUpDis "2nd Right side seat moving state  : Tilt up";
BA_ "GenSigSendType" SG_ 1006 RRPSU_TiltUpDis 4;
BA_ "UserSigValidity" SG_ 1006 RRPSU_TiltUpDis 0;
BA_ "Version" SG_ 1006 RRPSU_TiltUpDis "18.09.01";
BA_ "Description" SG_ 2353206529 CLU_Crc20Val "The data area for CRC calculation is based on the data length (DLC) of the message DB.

The CRC shall be calculated over the entire data block (excluding the CRC bytes) including the user data, alive counter and Data ID



- CRC Polynomial (0x1021) , Ini";
BA_ "GenSigStartValue" SG_ 2353206529 CLU_Crc20Val 65535;
BA_ "UserSigValidity" SG_ 2353206529 CLU_Crc20Val 3;
BA_ "Version" SG_ 2353206529 CLU_Crc20Val "21.09.03";
BA_ "Description" SG_ 2353206529 CLU_AlvCnt20Val "For the first transmission request for a data element the counter shall be initialized with 0 and shall be incremented by 1 for every subsequent send request. 

When the counter reaches the maximum value(0xFF), then it shall restart with 0 for the next s";
BA_ "UserSigValidity" SG_ 2353206529 CLU_AlvCnt20Val 3;
BA_ "Version" SG_ 2353206529 CLU_AlvCnt20Val "21.09.03";
BA_ "Description" SG_ 2353206529 CLU_SndType "This signal is for sound type of Cluster.

The Cluster applied buzzer is can generate only on channel sound

and the Cluster applied speaker can generate multi channel sound.";
BA_ "UserSigValidity" SG_ 2353206529 CLU_SndType 3;
BA_ "Version" SG_ 2353206529 CLU_SndType "19.01.08";
BA_ "Description" SG_ 2353206529 CLU_ClusterUSM "USM application of Cluster

If USM is applied in Cluster, Signal send 0x1";
BA_ "UserSigValidity" SG_ 2353206529 CLU_ClusterUSM 3;
BA_ "Version" SG_ 2353206529 CLU_ClusterUSM "20.06.05";
BA_ "Description" SG_ 992 BCM_Crc2Val "The data area for CRC calculation is based on the data length (DLC) of the message DB.

The CRC shall be calculated over the entire data block (excluding the CRC bytes) including the user data, alive counter and Data ID 

 

- CRC Polynomial (0x1D) , Ini";
BA_ "GenSigSendType" SG_ 992 BCM_Crc2Val 4;
BA_ "UserSigValidity" SG_ 992 BCM_Crc2Val 0;
BA_ "Version" SG_ 992 BCM_Crc2Val "21.09.03";
BA_ "Description" SG_ 992 BCM_AlvCnt2Val "For the first transmission request for a data element the counter shall be initialized with 0 and shall be incremented by 1

for every subsequent send request. When the counter reaches the maximum value(0xE), then it shall restart with 0 for the next sen";
BA_ "GenSigSendType" SG_ 992 BCM_AlvCnt2Val 4;
BA_ "UserSigValidity" SG_ 992 BCM_AlvCnt2Val 0;
BA_ "Version" SG_ 992 BCM_AlvCnt2Val "21.09.03";
BA_ "GenSigSendType" SG_ 992 BAlarm_BglrAlrmCurrentSta 4;
BA_ "UserSigValidity" SG_ 992 BAlarm_BglrAlrmCurrentSta 0;
BA_ "NetworkRequest" SG_ 992 BAlarm_BglrAlrmCurrentSta 0;
BA_ "NetworkRequestHoldingTime" SG_ 992 BAlarm_BglrAlrmCurrentSta 5000;
BA_ "Version" SG_ 992 BAlarm_BglrAlrmCurrentSta "17.12.00";
BA_ "GenSigSendType" SG_ 992 BAlarm_BglrAlrmSta 4;
BA_ "UserSigValidity" SG_ 992 BAlarm_BglrAlrmSta 0;
BA_ "NetworkRequest" SG_ 992 BAlarm_BglrAlrmSta 0;
BA_ "NetworkRequestHoldingTime" SG_ 992 BAlarm_BglrAlrmSta 5000;
BA_ "Version" SG_ 992 BAlarm_BglrAlrmSta "17.12.00";
BA_ "Description" SG_ 992 BAlarm_PncAlrmSta "-For TeleCranking Panic Function

-This signal send to IBOX";
BA_ "GenSigSendType" SG_ 992 BAlarm_PncAlrmSta 4;
BA_ "UserSigValidity" SG_ 992 BAlarm_PncAlrmSta 0;
BA_ "NetworkRequest" SG_ 992 BAlarm_PncAlrmSta 0;
BA_ "NetworkRequestHoldingTime" SG_ 992 BAlarm_PncAlrmSta 5000;
BA_ "Version" SG_ 992 BAlarm_PncAlrmSta "17.12.00";
BA_ "GenSigSendType" SG_ 992 BAlarm_StrtInhbtRlySta 4;
BA_ "UserSigValidity" SG_ 992 BAlarm_StrtInhbtRlySta 0;
BA_ "NetworkRequest" SG_ 992 BAlarm_StrtInhbtRlySta 0;
BA_ "NetworkRequestHoldingTime" SG_ 992 BAlarm_StrtInhbtRlySta 5000;
BA_ "Version" SG_ 992 BAlarm_StrtInhbtRlySta "17.12.00";
BA_ "GenSigSendType" SG_ 992 BAlarm_BrglrHrnRlySta 4;
BA_ "UserSigValidity" SG_ 992 BAlarm_BrglrHrnRlySta 0;
BA_ "NetworkRequest" SG_ 992 BAlarm_BrglrHrnRlySta 0;
BA_ "NetworkRequestHoldingTime" SG_ 992 BAlarm_BrglrHrnRlySta 5000;
BA_ "Version" SG_ 992 BAlarm_BrglrHrnRlySta "17.12.00";
BA_ "Description" SG_ 992 BCM_KeyInSta "Mechanical Key In SW State (If SMK option is On, C_KeyInSw always have  Off

 value)";
BA_ "GenSigSendType" SG_ 992 BCM_KeyInSta 4;
BA_ "UserSigValidity" SG_ 992 BCM_KeyInSta 0;
BA_ "NetworkRequest" SG_ 992 BCM_KeyInSta 0;
BA_ "NetworkRequestHoldingTime" SG_ 992 BCM_KeyInSta 5000;
BA_ "Version" SG_ 992 BCM_KeyInSta "17.12.00";
BA_ "GenSigSendType" SG_ 992 BCM_AccInSta 4;
BA_ "UserSigValidity" SG_ 992 BCM_AccInSta 0;
BA_ "NetworkRequest" SG_ 992 BCM_AccInSta 0;
BA_ "NetworkRequestHoldingTime" SG_ 992 BCM_AccInSta 5000;
BA_ "Version" SG_ 992 BCM_AccInSta "17.12.00";
BA_ "GenSigSendType" SG_ 992 BCM_Ign1InSta 4;
BA_ "UserSigValidity" SG_ 992 BCM_Ign1InSta 0;
BA_ "NetworkRequest" SG_ 992 BCM_Ign1InSta 0;
BA_ "NetworkRequestHoldingTime" SG_ 992 BCM_Ign1InSta 5000;
BA_ "Version" SG_ 992 BCM_Ign1InSta "17.12.00";
BA_ "GenSigSendType" SG_ 992 BCM_Ign2InSta 4;
BA_ "UserSigValidity" SG_ 992 BCM_Ign2InSta 0;
BA_ "NetworkRequest" SG_ 992 BCM_Ign2InSta 0;
BA_ "NetworkRequestHoldingTime" SG_ 992 BCM_Ign2InSta 5000;
BA_ "Version" SG_ 992 BCM_Ign2InSta "17.12.00";
BA_ "Description" SG_ 1964 SCM_GST_Byte0 "TP Index : 172";
BA_ "UsrSigPurpose" SG_ 1964 SCM_GST_Byte0 4;
BA_ "UserSigValidity" SG_ 1964 SCM_GST_Byte0 0;
BA_ "NetworkRequest" SG_ 1964 SCM_GST_Byte0 0;
BA_ "NetworkRequestHoldingTime" SG_ 1964 SCM_GST_Byte0 5000;
BA_ "Version" SG_ 1964 SCM_GST_Byte0 "22.07.01";
BA_ "Description" SG_ 1964 SCM_GST_Byte2 "TP Index : 172";
BA_ "UsrSigPurpose" SG_ 1964 SCM_GST_Byte2 4;
BA_ "UserSigValidity" SG_ 1964 SCM_GST_Byte2 0;
BA_ "NetworkRequest" SG_ 1964 SCM_GST_Byte2 0;
BA_ "NetworkRequestHoldingTime" SG_ 1964 SCM_GST_Byte2 5000;
BA_ "Version" SG_ 1964 SCM_GST_Byte2 "22.07.01";
BA_ "Description" SG_ 1964 SCM_GST_Byte3 "TP Index : 172";
BA_ "UsrSigPurpose" SG_ 1964 SCM_GST_Byte3 4;
BA_ "UserSigValidity" SG_ 1964 SCM_GST_Byte3 0;
BA_ "NetworkRequest" SG_ 1964 SCM_GST_Byte3 0;
BA_ "NetworkRequestHoldingTime" SG_ 1964 SCM_GST_Byte3 5000;
BA_ "Version" SG_ 1964 SCM_GST_Byte3 "22.07.01";
BA_ "Description" SG_ 1964 SCM_GST_Byte4 "TP Index : 172";
BA_ "UsrSigPurpose" SG_ 1964 SCM_GST_Byte4 4;
BA_ "UserSigValidity" SG_ 1964 SCM_GST_Byte4 0;
BA_ "NetworkRequest" SG_ 1964 SCM_GST_Byte4 0;
BA_ "NetworkRequestHoldingTime" SG_ 1964 SCM_GST_Byte4 5000;
BA_ "Version" SG_ 1964 SCM_GST_Byte4 "22.07.01";
BA_ "Description" SG_ 1964 SCM_GST_Byte5 "TP Index : 172";
BA_ "UsrSigPurpose" SG_ 1964 SCM_GST_Byte5 4;
BA_ "UserSigValidity" SG_ 1964 SCM_GST_Byte5 0;
BA_ "NetworkRequest" SG_ 1964 SCM_GST_Byte5 0;
BA_ "NetworkRequestHoldingTime" SG_ 1964 SCM_GST_Byte5 5000;
BA_ "Version" SG_ 1964 SCM_GST_Byte5 "22.07.01";
BA_ "Description" SG_ 1964 SCM_GST_Byte6 "TP Index : 172";
BA_ "UsrSigPurpose" SG_ 1964 SCM_GST_Byte6 4;
BA_ "UserSigValidity" SG_ 1964 SCM_GST_Byte6 0;
BA_ "NetworkRequest" SG_ 1964 SCM_GST_Byte6 0;
BA_ "NetworkRequestHoldingTime" SG_ 1964 SCM_GST_Byte6 5000;
BA_ "Version" SG_ 1964 SCM_GST_Byte6 "22.07.01";
BA_ "Description" SG_ 1964 SCM_GST_Byte7 "TP Index : 172";
BA_ "UsrSigPurpose" SG_ 1964 SCM_GST_Byte7 4;
BA_ "UserSigValidity" SG_ 1964 SCM_GST_Byte7 0;
BA_ "NetworkRequest" SG_ 1964 SCM_GST_Byte7 0;
BA_ "NetworkRequestHoldingTime" SG_ 1964 SCM_GST_Byte7 5000;
BA_ "Version" SG_ 1964 SCM_GST_Byte7 "22.07.01";
BA_ "Description" SG_ 1964 SCM_GST_Byte1 "TP Index : 172";
BA_ "UsrSigPurpose" SG_ 1964 SCM_GST_Byte1 4;
BA_ "UserSigValidity" SG_ 1964 SCM_GST_Byte1 0;
BA_ "NetworkRequest" SG_ 1964 SCM_GST_Byte1 0;
BA_ "NetworkRequestHoldingTime" SG_ 1964 SCM_GST_Byte1 5000;
BA_ "Version" SG_ 1964 SCM_GST_Byte1 "22.07.01";
BA_ "Description" SG_ 1967 SWRC_GST_Byte0 "TP Index : 175";
BA_ "UsrSigPurpose" SG_ 1967 SWRC_GST_Byte0 4;
BA_ "UserSigValidity" SG_ 1967 SWRC_GST_Byte0 0;
BA_ "NetworkRequest" SG_ 1967 SWRC_GST_Byte0 0;
BA_ "NetworkRequestHoldingTime" SG_ 1967 SWRC_GST_Byte0 5000;
BA_ "Version" SG_ 1967 SWRC_GST_Byte0 "22.07.01";
BA_ "Description" SG_ 1967 SWRC_GST_Byte2 "TP Index : 175";
BA_ "UsrSigPurpose" SG_ 1967 SWRC_GST_Byte2 4;
BA_ "UserSigValidity" SG_ 1967 SWRC_GST_Byte2 0;
BA_ "NetworkRequest" SG_ 1967 SWRC_GST_Byte2 0;
BA_ "NetworkRequestHoldingTime" SG_ 1967 SWRC_GST_Byte2 5000;
BA_ "Version" SG_ 1967 SWRC_GST_Byte2 "22.07.01";
BA_ "Description" SG_ 1967 SWRC_GST_Byte3 "TP Index : 175";
BA_ "UsrSigPurpose" SG_ 1967 SWRC_GST_Byte3 4;
BA_ "UserSigValidity" SG_ 1967 SWRC_GST_Byte3 0;
BA_ "NetworkRequest" SG_ 1967 SWRC_GST_Byte3 0;
BA_ "NetworkRequestHoldingTime" SG_ 1967 SWRC_GST_Byte3 5000;
BA_ "Version" SG_ 1967 SWRC_GST_Byte3 "22.07.01";
BA_ "Description" SG_ 1967 SWRC_GST_Byte4 "TP Index : 175";
BA_ "UsrSigPurpose" SG_ 1967 SWRC_GST_Byte4 4;
BA_ "UserSigValidity" SG_ 1967 SWRC_GST_Byte4 0;
BA_ "NetworkRequest" SG_ 1967 SWRC_GST_Byte4 0;
BA_ "NetworkRequestHoldingTime" SG_ 1967 SWRC_GST_Byte4 5000;
BA_ "Version" SG_ 1967 SWRC_GST_Byte4 "22.07.01";
BA_ "Description" SG_ 1967 SWRC_GST_Byte5 "TP Index : 175";
BA_ "UsrSigPurpose" SG_ 1967 SWRC_GST_Byte5 4;
BA_ "UserSigValidity" SG_ 1967 SWRC_GST_Byte5 0;
BA_ "NetworkRequest" SG_ 1967 SWRC_GST_Byte5 0;
BA_ "NetworkRequestHoldingTime" SG_ 1967 SWRC_GST_Byte5 5000;
BA_ "Version" SG_ 1967 SWRC_GST_Byte5 "22.07.01";
BA_ "Description" SG_ 1967 SWRC_GST_Byte6 "TP Index : 175";
BA_ "UsrSigPurpose" SG_ 1967 SWRC_GST_Byte6 4;
BA_ "UserSigValidity" SG_ 1967 SWRC_GST_Byte6 0;
BA_ "NetworkRequest" SG_ 1967 SWRC_GST_Byte6 0;
BA_ "NetworkRequestHoldingTime" SG_ 1967 SWRC_GST_Byte6 5000;
BA_ "Version" SG_ 1967 SWRC_GST_Byte6 "22.07.01";
BA_ "Description" SG_ 1967 SWRC_GST_Byte7 "TP Index : 175";
BA_ "UsrSigPurpose" SG_ 1967 SWRC_GST_Byte7 4;
BA_ "UserSigValidity" SG_ 1967 SWRC_GST_Byte7 0;
BA_ "NetworkRequest" SG_ 1967 SWRC_GST_Byte7 0;
BA_ "NetworkRequestHoldingTime" SG_ 1967 SWRC_GST_Byte7 5000;
BA_ "Version" SG_ 1967 SWRC_GST_Byte7 "22.07.01";
BA_ "Description" SG_ 1967 SWRC_GST_Byte1 "TP Index : 175";
BA_ "UsrSigPurpose" SG_ 1967 SWRC_GST_Byte1 4;
BA_ "UserSigValidity" SG_ 1967 SWRC_GST_Byte1 0;
BA_ "NetworkRequest" SG_ 1967 SWRC_GST_Byte1 0;
BA_ "NetworkRequestHoldingTime" SG_ 1967 SWRC_GST_Byte1 5000;
BA_ "Version" SG_ 1967 SWRC_GST_Byte1 "22.07.01";
BA_ "Description" SG_ 994 BCM_Crc4Val "The data area for CRC calculation is based on the data length (DLC) of the message DB.

The CRC shall be calculated over the entire data block (excluding the CRC bytes) including the user data, alive counter and Data ID 

 

- CRC Polynomial (0x1D) , Ini";
BA_ "GenSigSendType" SG_ 994 BCM_Crc4Val 4;
BA_ "UserSigValidity" SG_ 994 BCM_Crc4Val 0;
BA_ "Version" SG_ 994 BCM_Crc4Val "21.09.03";
BA_ "Description" SG_ 994 BCM_AlvCnt4Val "For the first transmission request for a data element the counter shall be initialized with 0 and shall be incremented by 1

for every subsequent send request. When the counter reaches the maximum value(0xE), then it shall restart with 0 for the next sen";
BA_ "GenSigSendType" SG_ 994 BCM_AlvCnt4Val 4;
BA_ "UserSigValidity" SG_ 994 BCM_AlvCnt4Val 0;
BA_ "Version" SG_ 994 BCM_AlvCnt4Val "21.09.03";
BA_ "Description" SG_ 994 Warn_BzrWrngSta "-(Old)C_WngBuzzer";
BA_ "GenSigSendType" SG_ 994 Warn_BzrWrngSta 4;
BA_ "UserSigValidity" SG_ 994 Warn_BzrWrngSta 0;
BA_ "NetworkRequest" SG_ 994 Warn_BzrWrngSta 0;
BA_ "NetworkRequestHoldingTime" SG_ 994 Warn_BzrWrngSta 5000;
BA_ "Version" SG_ 994 Warn_BzrWrngSta "17.12.00";
BA_ "Description" SG_ 994 Warn_BCMWrngSta "Warning command og BCM";
BA_ "GenSigSendType" SG_ 994 Warn_BCMWrngSta 4;
BA_ "UserSigValidity" SG_ 994 Warn_BCMWrngSta 0;
BA_ "NetworkRequest" SG_ 994 Warn_BCMWrngSta 0;
BA_ "NetworkRequestHoldingTime" SG_ 994 Warn_BCMWrngSta 5000;
BA_ "Version" SG_ 994 Warn_BCMWrngSta "17.12.00";
BA_ "Description" SG_ 994 ROA_RrBlwAutoOffReq "This signal is used for a request to Rear Blow Off (Auto Cut)";
BA_ "GenSigSendType" SG_ 994 ROA_RrBlwAutoOffReq 4;
BA_ "UserSigValidity" SG_ 994 ROA_RrBlwAutoOffReq 0;
BA_ "NetworkRequest" SG_ 994 ROA_RrBlwAutoOffReq 0;
BA_ "NetworkRequestHoldingTime" SG_ 994 ROA_RrBlwAutoOffReq 5000;
BA_ "Version" SG_ 994 ROA_RrBlwAutoOffReq "21.04.00";
BA_ "Description" SG_ 994 ROA_RegionOpt "A Euro NCAP Option signal (BDC only)";
BA_ "GenSigSendType" SG_ 994 ROA_RegionOpt 4;
BA_ "UserSigValidity" SG_ 994 ROA_RegionOpt 0;
BA_ "NetworkRequest" SG_ 994 ROA_RegionOpt 0;
BA_ "NetworkRequestHoldingTime" SG_ 994 ROA_RegionOpt 5000;
BA_ "Version" SG_ 994 ROA_RegionOpt "21.11.07";
BA_ "Description" SG_ 994 Warn_RrStRmndOpt "Rear Seat Reminder System Appled Option

(BDC Only Use 0x0 and 0x2 in Signal Value Table)";
BA_ "GenSigSendType" SG_ 994 Warn_RrStRmndOpt 4;
BA_ "UserSigValidity" SG_ 994 Warn_RrStRmndOpt 0;
BA_ "NetworkRequest" SG_ 994 Warn_RrStRmndOpt 0;
BA_ "NetworkRequestHoldingTime" SG_ 994 Warn_RrStRmndOpt 5000;
BA_ "Version" SG_ 994 Warn_RrStRmndOpt "21.04.00";
BA_ "Description" SG_ 994 Warn_RrStRmndAlrmOnReq "Rear Seat Reminder Alarm State";
BA_ "GenSigSendType" SG_ 994 Warn_RrStRmndAlrmOnReq 4;
BA_ "UserSigValidity" SG_ 994 Warn_RrStRmndAlrmOnReq 0;
BA_ "NetworkRequest" SG_ 994 Warn_RrStRmndAlrmOnReq 0;
BA_ "NetworkRequestHoldingTime" SG_ 994 Warn_RrStRmndAlrmOnReq 5000;
BA_ "Version" SG_ 994 Warn_RrStRmndAlrmOnReq "17.12.00";
BA_ "Description" SG_ 994 Warn_RrStRmndSysSta "Rear Seat Reminder Alarm System Enable(On)/Disable(Off) state";
BA_ "GenSigSendType" SG_ 994 Warn_RrStRmndSysSta 4;
BA_ "UserSigValidity" SG_ 994 Warn_RrStRmndSysSta 0;
BA_ "NetworkRequest" SG_ 994 Warn_RrStRmndSysSta 0;
BA_ "NetworkRequestHoldingTime" SG_ 994 Warn_RrStRmndSysSta 5000;
BA_ "Version" SG_ 994 Warn_RrStRmndSysSta "17.12.00";
BA_ "Description" SG_ 994 Warn_RrStRmndAlrmInfo "Rear Seat Reminder Warning request signal";
BA_ "GenSigSendType" SG_ 994 Warn_RrStRmndAlrmInfo 4;
BA_ "UserSigValidity" SG_ 994 Warn_RrStRmndAlrmInfo 0;
BA_ "NetworkRequest" SG_ 994 Warn_RrStRmndAlrmInfo 0;
BA_ "NetworkRequestHoldingTime" SG_ 994 Warn_RrStRmndAlrmInfo 5000;
BA_ "Version" SG_ 994 Warn_RrStRmndAlrmInfo "22.03.04";
BA_ "Description" SG_ 994 Warn_RoaErr "ROA SENSOR Error(Malfunction)  signal";
BA_ "GenSigSendType" SG_ 994 Warn_RoaErr 4;
BA_ "UserSigValidity" SG_ 994 Warn_RoaErr 0;
BA_ "NetworkRequest" SG_ 994 Warn_RoaErr 0;
BA_ "NetworkRequestHoldingTime" SG_ 994 Warn_RoaErr 5000;
BA_ "Version" SG_ 994 Warn_RoaErr "18.07.01";
BA_ "Description" SG_ 994 WAL_FobSearching "IBU Walk Away Lock Fob Searching State for Radar ROA

(LIN_IBU_WAL_FobSearching for UIP ROA)";
BA_ "GenSigSendType" SG_ 994 WAL_FobSearching 4;
BA_ "UserSigValidity" SG_ 994 WAL_FobSearching 0;
BA_ "NetworkRequest" SG_ 994 WAL_FobSearching 0;
BA_ "NetworkRequestHoldingTime" SG_ 994 WAL_FobSearching 5000;
BA_ "Version" SG_ 994 WAL_FobSearching "19.06.00";
BA_ "GenSigSendType" SG_ 994 Warn_RrStRmndDelay 4;
BA_ "TimeoutValue" SG_ 994 Warn_RrStRmndDelay "0x0";
BA_ "UserSigValidity" SG_ 994 Warn_RrStRmndDelay 0;
BA_ "NetworkRequest" SG_ 994 Warn_RrStRmndDelay 0;
BA_ "NetworkRequestHoldingTime" SG_ 994 Warn_RrStRmndDelay 5000;
BA_ "Version" SG_ 994 Warn_RrStRmndDelay "22.03.04";
BA_ "GenSigSendType" SG_ 994 Warn_RrStRmndSysAct 4;
BA_ "TimeoutValue" SG_ 994 Warn_RrStRmndSysAct "0x0";
BA_ "UserSigValidity" SG_ 994 Warn_RrStRmndSysAct 0;
BA_ "NetworkRequest" SG_ 994 Warn_RrStRmndSysAct 0;
BA_ "NetworkRequestHoldingTime" SG_ 994 Warn_RrStRmndSysAct 5000;
BA_ "Version" SG_ 994 Warn_RrStRmndSysAct "22.03.04";
BA_ "GenSigSendType" SG_ 994 Warn_RrStRmndSysOffIND 4;
BA_ "TimeoutValue" SG_ 994 Warn_RrStRmndSysOffIND "0x0";
BA_ "UserSigValidity" SG_ 994 Warn_RrStRmndSysOffIND 0;
BA_ "NetworkRequest" SG_ 994 Warn_RrStRmndSysOffIND 0;
BA_ "NetworkRequestHoldingTime" SG_ 994 Warn_RrStRmndSysOffIND 5000;
BA_ "Version" SG_ 994 Warn_RrStRmndSysOffIND "22.08.01";
BA_REL_ "GenSigTimeoutTime" BU_SG_REL_ ARS SG_ 913 PSD_LHPSDLatchState 1500;
BA_REL_ "GenSigTimeoutTime" BU_SG_REL_ PFSU SG_ 913 PSD_LHPSDLatchState 1500;
BA_REL_ "GenSigTimeoutTime" BU_SG_REL_ WPC2 SG_ 913 PSD_LHPSDLatchState 1500;
BA_REL_ "GenSigTimeoutTime" BU_SG_REL_ ARS SG_ 913 PSD_RHPSDLatchState 1500;
BA_REL_ "GenSigTimeoutTime" BU_SG_REL_ PFSU SG_ 913 PSD_RHPSDLatchState 1500;
BA_REL_ "GenSigTimeoutTime" BU_SG_REL_ WPC2 SG_ 913 PSD_RHPSDLatchState 1500;
BA_REL_ "GenSigTimeoutTime" BU_SG_REL_ CGW_CCU SG_ 911 ATS_RearLock_Set 0;
BA_REL_ "GenSigTimeoutTime" BU_SG_REL_ CGW_CCU SG_ 911 ATS_RrCurtainBtn 0;
BA_REL_ "GenSigTimeoutTime" BU_SG_REL_ RCM SG_ 911 ATS_RRSunBlind 0;
BA_REL_ "GenSigTimeoutTime" BU_SG_REL_ CGW_CCU SG_ 911 ATS_RRSunBlind 0;
BA_REL_ "GenSigTimeoutTime" BU_SG_REL_ FCS SG_ 911 ATS_FCS_LockTrayIniPwSet 0;
BA_REL_ "GenSigTimeoutTime" BU_SG_REL_ FCS SG_ 911 ATS_FCS_LockTrayKeyPadNo 0;
BA_REL_ "GenSigTimeoutTime" BU_SG_REL_ FCS SG_ 911 ATS_FCS_LockTrayNoDel 0;
BA_REL_ "GenSigTimeoutTime" BU_SG_REL_ FCS SG_ 911 ATS_FCS_LockTrayNoClr 0;
BA_REL_ "GenSigTimeoutTime" BU_SG_REL_ FCS SG_ 911 ATS_FCS_LockTrayPwChange 0;
BA_REL_ "GenSigTimeoutTime" BU_SG_REL_ FCS SG_ 911 ATS_FCS_LockTrayPwReset 0;
BA_REL_ "GenSigTimeoutTime" BU_SG_REL_ FCS SG_ 911 ATS_FCS_LockTrayCancel 0;
BA_REL_ "GenSigTimeoutTime" BU_SG_REL_ PSB SG_ 1985 GST_PSB_Byte0 0;
BA_REL_ "GenSigTimeoutTime" BU_SG_REL_ PSB SG_ 1985 GST_PSB_Byte2 0;
BA_REL_ "GenSigTimeoutTime" BU_SG_REL_ PSB SG_ 1985 GST_PSB_Byte3 0;
BA_REL_ "GenSigTimeoutTime" BU_SG_REL_ PSB SG_ 1985 GST_PSB_Byte4 0;
BA_REL_ "GenSigTimeoutTime" BU_SG_REL_ PSB SG_ 1985 GST_PSB_Byte5 0;
BA_REL_ "GenSigTimeoutTime" BU_SG_REL_ PSB SG_ 1985 GST_PSB_Byte6 0;
BA_REL_ "GenSigTimeoutTime" BU_SG_REL_ PSB SG_ 1985 GST_PSB_Byte7 0;
BA_REL_ "GenSigTimeoutTime" BU_SG_REL_ PSB SG_ 1985 GST_PSB_Byte1 0;
BA_REL_ "GenSigTimeoutTime" BU_SG_REL_ ATS SG_ 2382594817 DATC_SyncDis 1500;
BA_REL_ "GenSigTimeoutTime" BU_SG_REL_ ATS SG_ 2382594817 DATC_OpSta 1500;
BA_REL_ "GenSigTimeoutTime" BU_SG_REL_ ATS SG_ 2382594817 DATC_ArClnIND 1500;
BA_REL_ "GenSigTimeoutTime" BU_SG_REL_ BLTN_CAM SG_ 905 RR_CrashUnlockCmd 1500;
BA_REL_ "GenSigTimeoutTime" BU_SG_REL_ WPC SG_ 905 Warn_RrRtDrSwSta_SBCM 1500;
BA_REL_ "GenSigTimeoutTime" BU_SG_REL_ RWPC SG_ 905 Warn_RrRtDrSwSta_SBCM 1500;
BA_REL_ "GenSigTimeoutTime" BU_SG_REL_ APSU SG_ 905 Warn_RrRtDrSwSta_SBCM 1500;
BA_REL_ "GenSigTimeoutTime" BU_SG_REL_ RRPSU SG_ 905 Warn_RrRtDrSwSta_SBCM 1500;
BA_REL_ "GenSigTimeoutTime" BU_SG_REL_ ATS SG_ 905 Warn_RrRtDrSwSta_SBCM 1500;
BA_REL_ "GenSigTimeoutTime" BU_SG_REL_ BLTN_CAM SG_ 905 Warn_RrRtDrSwSta_SBCM 1500;
BA_REL_ "GenSigTimeoutTime" BU_SG_REL_ WPC2 SG_ 905 Warn_RrRtDrSwSta_SBCM 1500;
BA_REL_ "GenSigTimeoutTime" BU_SG_REL_ ATS SG_ 905 DoorLock_RrRtDrUnLkSta_SBCM 1500;
BA_REL_ "GenSigTimeoutTime" BU_SG_REL_ CGW_CCU SG_ 904 PSM_DrvReclinePosition 1500;
BA_REL_ "GenSigTimeoutTime" BU_SG_REL_ DLBCU SG_ 904 PSM_EsyAcsGetOffSta 1500;
BA_REL_ "GenSigTimeoutTime" BU_SG_REL_ DSAU SG_ 904 PSM_EsyAcsGetOffSta 1500;
BA_REL_ "GenSigTimeoutTime" BU_SG_REL_ DLBCU SG_ 904 PSM_EsyAcsStpSta 1500;
BA_REL_ "GenSigTimeoutTime" BU_SG_REL_ DSAU SG_ 904 PSM_EsyAcsStpSta 1500;
BA_REL_ "GenSigTimeoutTime" BU_SG_REL_ CGW_CCU SG_ 904 PSM_SWVerMajor1 1500;
BA_REL_ "GenSigTimeoutTime" BU_SG_REL_ CGW_CCU SG_ 904 PSM_SWVerMinor1 1500;
BA_REL_ "GenSigTimeoutTime" BU_SG_REL_ CGW_CCU SG_ 904 PSM_SWVerMinor2 1500;
BA_REL_ "GenSigTimeoutTime" BU_SG_REL_ CGW_CCU SG_ 904 PSM_HDPSpprtSWVer 1500;
BA_REL_ "GenSigTimeoutTime" BU_SG_REL_ CGW_CCU SG_ 904 PSM_DrvHeightPosition 1500;
BA_REL_ "GenSigTimeoutTime" BU_SG_REL_ CGW_CCU SG_ 904 PSM_DrvSlidePosition 1500;
BA_REL_ "GenSigTimeoutTime" BU_SG_REL_ DLBCU SG_ 904 PSM_EsyAcsGetOnSta 1500;
BA_REL_ "GenSigTimeoutTime" BU_SG_REL_ DSAU SG_ 904 PSM_EsyAcsGetOnSta 1500;
BA_REL_ "GenSigTimeoutTime" BU_SG_REL_ CGW_CCU SG_ 903 PSM_DrvStSldFwdDis 1500;
BA_REL_ "GenSigTimeoutTime" BU_SG_REL_ CGW_CCU SG_ 903 PSM_DrvStTiltDnDis 1500;
BA_REL_ "GenSigTimeoutTime" BU_SG_REL_ CGW_CCU SG_ 903 PSM_DrvStHghtUpDis 1500;
BA_REL_ "GenSigTimeoutTime" BU_SG_REL_ CGW_CCU SG_ 903 PSM_DrvStHghtDnDis 1500;
BA_REL_ "GenSigTimeoutTime" BU_SG_REL_ CGW_CCU SG_ 903 PSM_DrvStCushExtBckwdDis 1500;
BA_REL_ "GenSigTimeoutTime" BU_SG_REL_ CGW_CCU SG_ 903 PSM_DrvStCushExtFwdDis 1500;
BA_REL_ "GenSigTimeoutTime" BU_SG_REL_ CGW_CCU SG_ 903 PSM_DrvStSldBckwdDis 1500;
BA_REL_ "GenSigTimeoutTime" BU_SG_REL_ CGW_CCU SG_ 903 PSM_DrvStHdRstUpDis 1500;
BA_REL_ "GenSigTimeoutTime" BU_SG_REL_ CGW_CCU SG_ 903 PSM_DrvStHdRstDnDis 1500;
BA_REL_ "GenSigTimeoutTime" BU_SG_REL_ CGW_CCU SG_ 903 PSM_DrvStHdRstFwdDis 1500;
BA_REL_ "GenSigTimeoutTime" BU_SG_REL_ CGW_CCU SG_ 903 PSM_DrvStHdRstBckwdDis 1500;
BA_REL_ "GenSigTimeoutTime" BU_SG_REL_ CGW_CCU SG_ 903 PSM_DrvStLmbrDefDis 1500;
BA_REL_ "GenSigTimeoutTime" BU_SG_REL_ CGW_CCU SG_ 903 PSM_DrvStLmbrLoDis 1500;
BA_REL_ "GenSigTimeoutTime" BU_SG_REL_ CGW_CCU SG_ 903 PSM_DrvStLmbrMdlDis 1500;
BA_REL_ "GenSigTimeoutTime" BU_SG_REL_ CGW_CCU SG_ 903 PSM_DrvStLmbrUpDis 1500;
BA_REL_ "GenSigTimeoutTime" BU_SG_REL_ CGW_CCU SG_ 903 PSM_DrvStReclneFwdDis 1500;
BA_REL_ "GenSigTimeoutTime" BU_SG_REL_ CGW_CCU SG_ 903 PSM_DrvStBlstrDefDis 1500;
BA_REL_ "GenSigTimeoutTime" BU_SG_REL_ CGW_CCU SG_ 903 PSM_DrvStBlstrInfDis 1500;
BA_REL_ "GenSigTimeoutTime" BU_SG_REL_ CGW_CCU SG_ 903 PSM_DrvStReclneBckwdDis 1500;
BA_REL_ "GenSigTimeoutTime" BU_SG_REL_ CGW_CCU SG_ 903 PSM_DrvStTiltUpDis 1500;
BA_REL_ "GenSigTimeoutTime" BU_SG_REL_ DLBCU SG_ 902 PSM_DrvStEsyAcsUSMSta 1500;
BA_REL_ "GenSigTimeoutTime" BU_SG_REL_ DSAU SG_ 902 PSM_DrvStEsyAcsUSMSta 1500;
BA_REL_ "GenSigTimeoutTime" BU_SG_REL_ CGW_CCU SG_ 902 PSM_DrvStEsyAcsUSMSta 1500;
BA_REL_ "GenSigTimeoutTime" BU_SG_REL_ CGW_CCU SG_ 902 PSM_SeatPosSldLmt_Sta 1500;
BA_REL_ "GenSigTimeoutTime" BU_SG_REL_ CGW_CCU SG_ 902 PSM_SeatPosRclnLmt_Sta 1500;
BA_REL_ "GenSigTimeoutTime" BU_SG_REL_ CGW_CCU SG_ 902 SmrtIMS_StatureRspVal 1500;
BA_REL_ "GenSigTimeoutTime" BU_SG_REL_ CGW_CCU SG_ 902 SmrtIMS_SeatedHghtRspVal 1500;
BA_REL_ "GenSigTimeoutTime" BU_SG_REL_ CGW_CCU SG_ 902 SmrtIMS_WghtRspVal 1500;
BA_REL_ "GenSigTimeoutTime" BU_SG_REL_ CGW_CCU SG_ 902 SmartIMS_DisReq 1500;
BA_REL_ "GenSigTimeoutTime" BU_SG_REL_ CGW_CCU SG_ 902 SmrtIMS_ExitSta 1500;
BA_REL_ "GenSigTimeoutTime" BU_SG_REL_ CGW_CCU SG_ 902 PSM_DrvStRlxTiltUpDis 1500;
BA_REL_ "GenSigTimeoutTime" BU_SG_REL_ CGW_CCU SG_ 902 PSM_DrvStRlxTiltDnDis 1500;
BA_REL_ "GenSigTimeoutTime" BU_SG_REL_ CGW_CCU SG_ 902 PSM_DrvStLegUpDis 1500;
BA_REL_ "GenSigTimeoutTime" BU_SG_REL_ CGW_CCU SG_ 902 PSM_DrvStLegDnDis 1500;
BA_REL_ "GenSigTimeoutTime" BU_SG_REL_ RLPSU SG_ 902 Drv_2ndStAutoRlxEnable 1500;
BA_REL_ "GenSigTimeoutTime" BU_SG_REL_ RRPSU SG_ 902 Drv_2ndStAutoRlxEnable 1500;
BA_REL_ "GenSigTimeoutTime" BU_SG_REL_ RLPSU SG_ 902 Drv_AutoRlxSta 1500;
BA_REL_ "GenSigTimeoutTime" BU_SG_REL_ RRPSU SG_ 902 Drv_AutoRlxSta 1500;
BA_REL_ "GenSigTimeoutTime" BU_SG_REL_ CGW_CCU SG_ 902 Drv_AutoRlxSta 1500;
BA_REL_ "GenSigTimeoutTime" BU_SG_REL_ CGW_CCU SG_ 902 Drv_AutoReturnSta 1500;
BA_REL_ "GenSigTimeoutTime" BU_SG_REL_ CGW_CCU SG_ 902 PSM_IMSOptTyp 1500;
BA_REL_ "GenSigTimeoutTime" BU_SG_REL_ CGW_CCU SG_ 1993 PSB_GST_Byte0 0;
BA_REL_ "GenSigTimeoutTime" BU_SG_REL_ CGW_CCU SG_ 1993 PSB_GST_Byte2 0;
BA_REL_ "GenSigTimeoutTime" BU_SG_REL_ CGW_CCU SG_ 1993 PSB_GST_Byte3 0;
BA_REL_ "GenSigTimeoutTime" BU_SG_REL_ CGW_CCU SG_ 1993 PSB_GST_Byte4 0;
BA_REL_ "GenSigTimeoutTime" BU_SG_REL_ CGW_CCU SG_ 1993 PSB_GST_Byte5 0;
BA_REL_ "GenSigTimeoutTime" BU_SG_REL_ CGW_CCU SG_ 1993 PSB_GST_Byte6 0;
BA_REL_ "GenSigTimeoutTime" BU_SG_REL_ CGW_CCU SG_ 1993 PSB_GST_Byte7 0;
BA_REL_ "GenSigTimeoutTime" BU_SG_REL_ CGW_CCU SG_ 1993 PSB_GST_Byte1 0;
BA_REL_ "GenSigTimeoutTime" BU_SG_REL_ BLTN_CAM SG_ 1016 GNSS_MM_type 5000;
BA_REL_ "GenSigTimeoutTime" BU_SG_REL_ DSAU SG_ 1019 HU_MoodTherapyDrSeat 0;
BA_REL_ "GenSigTimeoutTime" BU_SG_REL_ ASAU SG_ 1019 HU_MoodTherapyPsSeat 0;
BA_REL_ "GenSigTimeoutTime" BU_SG_REL_ DSAU SG_ 1019 HU_CareMassage 0;
BA_REL_ "GenSigTimeoutTime" BU_SG_REL_ ASAU SG_ 1019 HU_CareMassage 0;
BA_REL_ "GenSigTimeoutTime" BU_SG_REL_ DSAU SG_ 1019 HU_ComfortMassage 0;
BA_REL_ "GenSigTimeoutTime" BU_SG_REL_ ASAU SG_ 1019 HU_ComfortMassage 0;
BA_REL_ "GenSigTimeoutTime" BU_SG_REL_ DSAU SG_ 1019 HU_MoodTherapyMode 0;
BA_REL_ "GenSigTimeoutTime" BU_SG_REL_ ASAU SG_ 1019 HU_MoodTherapyMode 0;
BA_REL_ "GenSigTimeoutTime" BU_SG_REL_ BLTN_CAM SG_ 1015 HU_MM_Altitude 5000;
BA_REL_ "GenSigTimeoutTime" BU_SG_REL_ BLTN_CAM SG_ 1015 HU_MM_Heading 5000;
BA_REL_ "GenSigTimeoutTime" BU_SG_REL_ SCM SG_ 1956 GST_SCM_Byte0 0;
BA_REL_ "GenSigTimeoutTime" BU_SG_REL_ SCM SG_ 1956 GST_SCM_Byte2 0;
BA_REL_ "GenSigTimeoutTime" BU_SG_REL_ SCM SG_ 1956 GST_SCM_Byte3 0;
BA_REL_ "GenSigTimeoutTime" BU_SG_REL_ SCM SG_ 1956 GST_SCM_Byte4 0;
BA_REL_ "GenSigTimeoutTime" BU_SG_REL_ SCM SG_ 1956 GST_SCM_Byte5 0;
BA_REL_ "GenSigTimeoutTime" BU_SG_REL_ SCM SG_ 1956 GST_SCM_Byte6 0;
BA_REL_ "GenSigTimeoutTime" BU_SG_REL_ SCM SG_ 1956 GST_SCM_Byte7 0;
BA_REL_ "GenSigTimeoutTime" BU_SG_REL_ SCM SG_ 1956 GST_SCM_Byte1 0;
BA_REL_ "GenSigTimeoutTime" BU_SG_REL_ SWRC SG_ 1959 GST_SWRC_Byte0 0;
BA_REL_ "GenSigTimeoutTime" BU_SG_REL_ SWRC SG_ 1959 GST_SWRC_Byte2 0;
BA_REL_ "GenSigTimeoutTime" BU_SG_REL_ SWRC SG_ 1959 GST_SWRC_Byte3 0;
BA_REL_ "GenSigTimeoutTime" BU_SG_REL_ SWRC SG_ 1959 GST_SWRC_Byte4 0;
BA_REL_ "GenSigTimeoutTime" BU_SG_REL_ SWRC SG_ 1959 GST_SWRC_Byte5 0;
BA_REL_ "GenSigTimeoutTime" BU_SG_REL_ SWRC SG_ 1959 GST_SWRC_Byte6 0;
BA_REL_ "GenSigTimeoutTime" BU_SG_REL_ SWRC SG_ 1959 GST_SWRC_Byte7 0;
BA_REL_ "GenSigTimeoutTime" BU_SG_REL_ SWRC SG_ 1959 GST_SWRC_Byte1 0;
BA_REL_ "GenSigTimeoutTime" BU_SG_REL_ ATS SG_ 1003 PSM_BzrOnRLReq 1500;
BA_REL_ "GenSigTimeoutTime" BU_SG_REL_ DPSU SG_ 1003 PSM_BzrOnRLReq 1500;
BA_REL_ "GenSigTimeoutTime" BU_SG_REL_ APSU SG_ 1003 RLPSM_RearModeState 1500;
BA_REL_ "GenSigTimeoutTime" BU_SG_REL_ ATS SG_ 1003 RLPSM_RearModeState 1500;
BA_REL_ "GenSigTimeoutTime" BU_SG_REL_ DPSU SG_ 1003 RLPSM_RearModeState 1500;
BA_REL_ "GenSigTimeoutTime" BU_SG_REL_ OHCL SG_ 1003 RLPSM_RearModeState 1500;
BA_REL_ "GenSigTimeoutTime" BU_SG_REL_ CGW_CCU SG_ 1003 RLPSM_RearModeState 1500;
BA_REL_ "GenSigTimeoutTime" BU_SG_REL_ CGW_CCU SG_ 1003 RLPSM_RearModeState 1500;
BA_REL_ "GenSigTimeoutTime" BU_SG_REL_ ATS SG_ 1003 RLPSM_RLStEsyAcsUSMSta 1500;
BA_REL_ "GenSigTimeoutTime" BU_SG_REL_ CGW_CCU SG_ 1003 RLPSM_RLStEsyAcsUSMSta 1500;
BA_REL_ "GenSigTimeoutTime" BU_SG_REL_ APSU SG_ 1003 RLPSM_RLSlidePosition 1500;
BA_REL_ "GenSigTimeoutTime" BU_SG_REL_ RRPSU SG_ 1003 RLPSM_RLSlidePosition 1500;
BA_REL_ "GenSigTimeoutTime" BU_SG_REL_ RRPSU SG_ 1003 RLPSM_SeatPos_Sta 1500;
BA_REL_ "GenSigTimeoutTime" BU_SG_REL_ CGW_CCU SG_ 1002 BLTN_CAM_HU_UI_Mode 1500;
BA_REL_ "GenSigTimeoutTime" BU_SG_REL_ CGW_CCU SG_ 1002 BLTN_CAM_SD_Format_Op_State 1500;
BA_REL_ "GenSigTimeoutTime" BU_SG_REL_ CGW_CCU SG_ 1002 BLTN_CAM_PEV_Recorded 1500;
BA_REL_ "GenSigTimeoutTime" BU_SG_REL_ CGW_CCU SG_ 1002 BLTN_CAM_PEV_Count 1500;
BA_REL_ "GenSigTimeoutTime" BU_SG_REL_ CGW_CCU SG_ 1002 BLTN_CAM_Ind_Req 1500;
BA_REL_ "GenSigTimeoutTime" BU_SG_REL_ CGW_CCU SG_ 1002 BLTN_CAM_LVDS_Mode_State 1500;
BA_REL_ "GenSigTimeoutTime" BU_SG_REL_ CGW_CCU SG_ 1002 BLTN_CAM_PrkOp_Termiate_Info 1500;
BA_REL_ "GenSigTimeoutTime" BU_SG_REL_ CGW_CCU SG_ 1002 BLTN_CAM_Display 1500;
BA_REL_ "GenSigTimeoutTime" BU_SG_REL_ CGW_CCU SG_ 1002 BLTN_CAM_WiFi_State 1500;
BA_REL_ "GenSigTimeoutTime" BU_SG_REL_ CGW_CCU SG_ 1005 RLPSU_FldDis 1500;
BA_REL_ "GenSigTimeoutTime" BU_SG_REL_ CGW_CCU SG_ 1005 RLPSU_TiltDownDis 1500;
BA_REL_ "GenSigTimeoutTime" BU_SG_REL_ CGW_CCU SG_ 1005 RLPSU_RclFwdDis 1500;
BA_REL_ "GenSigTimeoutTime" BU_SG_REL_ CGW_CCU SG_ 1005 RLPSU_RclBwdDis 1500;
BA_REL_ "GenSigTimeoutTime" BU_SG_REL_ CGW_CCU SG_ 1005 RLPSU_Folding_Postion 1500;
BA_REL_ "GenSigTimeoutTime" BU_SG_REL_ CGW_CCU SG_ 1005 RLPSU_SlideFwdDis 1500;
BA_REL_ "GenSigTimeoutTime" BU_SG_REL_ CGW_CCU SG_ 1005 RLPSU_SlideBwdDis 1500;
BA_REL_ "GenSigTimeoutTime" BU_SG_REL_ CGW_CCU SG_ 1005 RLPSU_TiltUpDis 1500;
BA_REL_ "GenSigTimeoutTime" BU_SG_REL_ CGW_CCU SG_ 1004 CF_RCS_SwTyp 1500;
BA_REL_ "GenSigTimeoutTime" BU_SG_REL_ CGW_CCU SG_ 1004 CF_RCS_OffRoad 1500;
BA_REL_ "GenSigTimeoutTime" BU_SG_REL_ CGW_CCU SG_ 1004 CF_RCS_BtnSta 1500;
BA_REL_ "GenSigTimeoutTime" BU_SG_REL_ CGW_CCU SG_ 1004 CF_RCS_RotateEnd 1500;
BA_REL_ "GenSigTimeoutTime" BU_SG_REL_ CGW_CCU SG_ 1004 CF_RCS_4wdLocking 1500;
BA_REL_ "GenSigTimeoutTime" BU_SG_REL_ CGW_CCU SG_ 1004 RCS_Direction_SW 1500;
BA_REL_ "GenSigTimeoutTime" BU_SG_REL_ CGW_CCU SG_ 1004 CF_RCS_DrvMod 1500;
BA_REL_ "GenSigTimeoutTime" BU_SG_REL_ CGW_CCU SG_ 1004 RCS_Mode_SW 1500;
BA_REL_ "GenSigTimeoutTime" BU_SG_REL_ CGW_CCU SG_ 1004 CF_RCS_TowMode 200;
BA_REL_ "GenSigTimeoutTime" BU_SG_REL_ DPSU SG_ 1955 GST_DPSU_Byte0 0;
BA_REL_ "GenSigTimeoutTime" BU_SG_REL_ DPSU SG_ 1955 GST_DPSU_Byte2 0;
BA_REL_ "GenSigTimeoutTime" BU_SG_REL_ DPSU SG_ 1955 GST_DPSU_Byte3 0;
BA_REL_ "GenSigTimeoutTime" BU_SG_REL_ DPSU SG_ 1955 GST_DPSU_Byte4 0;
BA_REL_ "GenSigTimeoutTime" BU_SG_REL_ DPSU SG_ 1955 GST_DPSU_Byte5 0;
BA_REL_ "GenSigTimeoutTime" BU_SG_REL_ DPSU SG_ 1955 GST_DPSU_Byte6 0;
BA_REL_ "GenSigTimeoutTime" BU_SG_REL_ DPSU SG_ 1955 GST_DPSU_Byte7 0;
BA_REL_ "GenSigTimeoutTime" BU_SG_REL_ DPSU SG_ 1955 GST_DPSU_Byte1 0;
BA_REL_ "GenSigTimeoutTime" BU_SG_REL_ OHCL SG_ 1007 ATS_LEDBgtnsUpDn 0;
BA_REL_ "GenSigTimeoutTime" BU_SG_REL_ OHCL SG_ 1007 ATS_FrMoodOn_Req 0;
BA_REL_ "GenSigTimeoutTime" BU_SG_REL_ OHCL SG_ 1007 ATS_DoorOn_Req 0;
BA_REL_ "GenSigTimeoutTime" BU_SG_REL_ OHCL SG_ 1007 ATS_RrMapLftOn_Req 0;
BA_REL_ "GenSigTimeoutTime" BU_SG_REL_ OHCL SG_ 1007 ATS_RrMapRtOn_Req 0;
BA_REL_ "GenSigTimeoutTime" BU_SG_REL_ OHCL SG_ 1007 ATS_RrRoomOn_Req 0;
BA_REL_ "GenSigTimeoutTime" BU_SG_REL_ OHCL SG_ 1007 ATS_LEDClrUpDn 0;
BA_REL_ "GenSigTimeoutTime" BU_SG_REL_ OHCL SG_ 1007 ATS_RrMoodOn_Req 0;
BA_REL_ "GenSigTimeoutTime" BU_SG_REL_ OHCL SG_ 1007 ATS_LEDClr_Set 0;
BA_REL_ "GenSigTimeoutTime" BU_SG_REL_ OHCL SG_ 1007 ATS_LEDBgtns_Set 0;
BA_REL_ "GenSigTimeoutTime" BU_SG_REL_ OHCL SG_ 1007 ATS_FrMapLftOn_Req 0;
BA_REL_ "GenSigTimeoutTime" BU_SG_REL_ OHCL SG_ 1007 ATS_FrMapRtOn_Req 0;
BA_REL_ "GenSigTimeoutTime" BU_SG_REL_ OHCL SG_ 1007 ATS_FrRoomOn_Req 0;
BA_REL_ "GenSigTimeoutTime" BU_SG_REL_ CGW_CCU SG_ 1006 RRPSU_FldDis 1500;
BA_REL_ "GenSigTimeoutTime" BU_SG_REL_ CGW_CCU SG_ 1006 RRPSU_TiltDnDis 1500;
BA_REL_ "GenSigTimeoutTime" BU_SG_REL_ CGW_CCU SG_ 1006 RRPSU_RecFwdDis 1500;
BA_REL_ "GenSigTimeoutTime" BU_SG_REL_ CGW_CCU SG_ 1006 RRPSU_RecBwdDis 1500;
BA_REL_ "GenSigTimeoutTime" BU_SG_REL_ CGW_CCU SG_ 1006 RRPSU_Folding_Postion 1500;
BA_REL_ "GenSigTimeoutTime" BU_SG_REL_ CGW_CCU SG_ 1006 RRPSU_SlideFwdDis 1500;
BA_REL_ "GenSigTimeoutTime" BU_SG_REL_ CGW_CCU SG_ 1006 RRPSU_SlideBwdDis 1500;
BA_REL_ "GenSigTimeoutTime" BU_SG_REL_ CGW_CCU SG_ 1006 RRPSU_TiltUpDis 1500;
BA_REL_ "GenSigTimeoutTime" BU_SG_REL_ WPC SG_ 2353206529 CLU_ClusterUSM 1500;
BA_REL_ "GenSigTimeoutTime" BU_SG_REL_ WPC2 SG_ 2353206529 CLU_ClusterUSM 1500;
BA_REL_ "GenSigTimeoutTime" BU_SG_REL_ BLTN_CAM SG_ 992 BAlarm_BglrAlrmCurrentSta 1500;
BA_REL_ "GenSigTimeoutTime" BU_SG_REL_ SWRC SG_ 992 BCM_KeyInSta 1500;
BA_REL_ "GenSigTimeoutTime" BU_SG_REL_ APSU SG_ 992 BCM_KeyInSta 1500;
BA_REL_ "GenSigTimeoutTime" BU_SG_REL_ RLHV SG_ 992 BCM_KeyInSta 1500;
BA_REL_ "GenSigTimeoutTime" BU_SG_REL_ RRHV SG_ 992 BCM_KeyInSta 1500;
BA_REL_ "GenSigTimeoutTime" BU_SG_REL_ SHVU_FR SG_ 992 BCM_KeyInSta 1500;
BA_REL_ "GenSigTimeoutTime" BU_SG_REL_ SHVU_RR SG_ 992 BCM_KeyInSta 1500;
BA_REL_ "GenSigTimeoutTime" BU_SG_REL_ DPSU SG_ 992 BCM_KeyInSta 1500;
BA_REL_ "GenSigTimeoutTime" BU_SG_REL_ DLBCU SG_ 992 BCM_KeyInSta 1500;
BA_REL_ "GenSigTimeoutTime" BU_SG_REL_ PFSU SG_ 992 BCM_KeyInSta 1500;
BA_REL_ "GenSigTimeoutTime" BU_SG_REL_ RRPSU SG_ 992 BCM_KeyInSta 1500;
BA_REL_ "GenSigTimeoutTime" BU_SG_REL_ RLPSU SG_ 992 BCM_KeyInSta 1500;
BA_REL_ "GenSigTimeoutTime" BU_SG_REL_ SGU SG_ 992 BCM_KeyInSta 1500;
BA_REL_ "GenSigTimeoutTime" BU_SG_REL_ ALBCU SG_ 992 BCM_KeyInSta 1500;
BA_REL_ "GenSigTimeoutTime" BU_SG_REL_ SCM SG_ 992 BCM_AccInSta 1500;
BA_REL_ "GenSigTimeoutTime" BU_SG_REL_ SWRC SG_ 992 BCM_AccInSta 1500;
BA_REL_ "GenSigTimeoutTime" BU_SG_REL_ APSU SG_ 992 BCM_AccInSta 1500;
BA_REL_ "GenSigTimeoutTime" BU_SG_REL_ RLHV SG_ 992 BCM_AccInSta 1500;
BA_REL_ "GenSigTimeoutTime" BU_SG_REL_ RRHV SG_ 992 BCM_AccInSta 1500;
BA_REL_ "GenSigTimeoutTime" BU_SG_REL_ SHVU_FR SG_ 992 BCM_AccInSta 1500;
BA_REL_ "GenSigTimeoutTime" BU_SG_REL_ SHVU_RR SG_ 992 BCM_AccInSta 1500;
BA_REL_ "GenSigTimeoutTime" BU_SG_REL_ DPSU SG_ 992 BCM_AccInSta 1500;
BA_REL_ "GenSigTimeoutTime" BU_SG_REL_ DLBCU SG_ 992 BCM_AccInSta 1500;
BA_REL_ "GenSigTimeoutTime" BU_SG_REL_ PFSU SG_ 992 BCM_AccInSta 1500;
BA_REL_ "GenSigTimeoutTime" BU_SG_REL_ RRPSU SG_ 992 BCM_AccInSta 1500;
BA_REL_ "GenSigTimeoutTime" BU_SG_REL_ RLPSU SG_ 992 BCM_AccInSta 1500;
BA_REL_ "GenSigTimeoutTime" BU_SG_REL_ ATS SG_ 992 BCM_AccInSta 1500;
BA_REL_ "GenSigTimeoutTime" BU_SG_REL_ DSAU SG_ 992 BCM_AccInSta 1500;
BA_REL_ "GenSigTimeoutTime" BU_SG_REL_ ASAU SG_ 992 BCM_AccInSta 1500;
BA_REL_ "GenSigTimeoutTime" BU_SG_REL_ SGU SG_ 992 BCM_AccInSta 1500;
BA_REL_ "GenSigTimeoutTime" BU_SG_REL_ ALBCU SG_ 992 BCM_AccInSta 1500;
BA_REL_ "GenSigTimeoutTime" BU_SG_REL_ WPC2 SG_ 992 BCM_AccInSta 1500;
BA_REL_ "GenSigTimeoutTime" BU_SG_REL_ SCM SG_ 992 BCM_Ign1InSta 1500;
BA_REL_ "GenSigTimeoutTime" BU_SG_REL_ SWRC SG_ 992 BCM_Ign1InSta 1500;
BA_REL_ "GenSigTimeoutTime" BU_SG_REL_ APSU SG_ 992 BCM_Ign1InSta 1500;
BA_REL_ "GenSigTimeoutTime" BU_SG_REL_ RLHV SG_ 992 BCM_Ign1InSta 1500;
BA_REL_ "GenSigTimeoutTime" BU_SG_REL_ RRHV SG_ 992 BCM_Ign1InSta 1500;
BA_REL_ "GenSigTimeoutTime" BU_SG_REL_ SHVU_FR SG_ 992 BCM_Ign1InSta 1500;
BA_REL_ "GenSigTimeoutTime" BU_SG_REL_ SHVU_RR SG_ 992 BCM_Ign1InSta 1500;
BA_REL_ "GenSigTimeoutTime" BU_SG_REL_ DPSU SG_ 992 BCM_Ign1InSta 1500;
BA_REL_ "GenSigTimeoutTime" BU_SG_REL_ DLBCU SG_ 992 BCM_Ign1InSta 1500;
BA_REL_ "GenSigTimeoutTime" BU_SG_REL_ PFSU SG_ 992 BCM_Ign1InSta 1500;
BA_REL_ "GenSigTimeoutTime" BU_SG_REL_ RRPSU SG_ 992 BCM_Ign1InSta 1500;
BA_REL_ "GenSigTimeoutTime" BU_SG_REL_ RLPSU SG_ 992 BCM_Ign1InSta 1500;
BA_REL_ "GenSigTimeoutTime" BU_SG_REL_ HOD SG_ 992 BCM_Ign1InSta 1500;
BA_REL_ "GenSigTimeoutTime" BU_SG_REL_ ATS SG_ 992 BCM_Ign1InSta 1500;
BA_REL_ "GenSigTimeoutTime" BU_SG_REL_ DSAU SG_ 992 BCM_Ign1InSta 1500;
BA_REL_ "GenSigTimeoutTime" BU_SG_REL_ ASAU SG_ 992 BCM_Ign1InSta 1500;
BA_REL_ "GenSigTimeoutTime" BU_SG_REL_ RCM SG_ 992 BCM_Ign1InSta 1500;
BA_REL_ "GenSigTimeoutTime" BU_SG_REL_ SGU SG_ 992 BCM_Ign1InSta 1500;
BA_REL_ "GenSigTimeoutTime" BU_SG_REL_ ALBCU SG_ 992 BCM_Ign1InSta 1500;
BA_REL_ "GenSigTimeoutTime" BU_SG_REL_ SCM SG_ 992 BCM_Ign2InSta 1500;
BA_REL_ "GenSigTimeoutTime" BU_SG_REL_ SWRC SG_ 992 BCM_Ign2InSta 1500;
BA_REL_ "GenSigTimeoutTime" BU_SG_REL_ APSU SG_ 992 BCM_Ign2InSta 1500;
BA_REL_ "GenSigTimeoutTime" BU_SG_REL_ RLHV SG_ 992 BCM_Ign2InSta 1500;
BA_REL_ "GenSigTimeoutTime" BU_SG_REL_ RRHV SG_ 992 BCM_Ign2InSta 1500;
BA_REL_ "GenSigTimeoutTime" BU_SG_REL_ SHVU_FR SG_ 992 BCM_Ign2InSta 1500;
BA_REL_ "GenSigTimeoutTime" BU_SG_REL_ SHVU_RR SG_ 992 BCM_Ign2InSta 1500;
BA_REL_ "GenSigTimeoutTime" BU_SG_REL_ DPSU SG_ 992 BCM_Ign2InSta 1500;
BA_REL_ "GenSigTimeoutTime" BU_SG_REL_ DLBCU SG_ 992 BCM_Ign2InSta 1500;
BA_REL_ "GenSigTimeoutTime" BU_SG_REL_ PFSU SG_ 992 BCM_Ign2InSta 1500;
BA_REL_ "GenSigTimeoutTime" BU_SG_REL_ RRPSU SG_ 992 BCM_Ign2InSta 1500;
BA_REL_ "GenSigTimeoutTime" BU_SG_REL_ RLPSU SG_ 992 BCM_Ign2InSta 1500;
BA_REL_ "GenSigTimeoutTime" BU_SG_REL_ ATS SG_ 992 BCM_Ign2InSta 1500;
BA_REL_ "GenSigTimeoutTime" BU_SG_REL_ DSAU SG_ 992 BCM_Ign2InSta 1500;
BA_REL_ "GenSigTimeoutTime" BU_SG_REL_ ASAU SG_ 992 BCM_Ign2InSta 1500;
BA_REL_ "GenSigTimeoutTime" BU_SG_REL_ RCM SG_ 992 BCM_Ign2InSta 1500;
BA_REL_ "GenSigTimeoutTime" BU_SG_REL_ SGU SG_ 992 BCM_Ign2InSta 1500;
BA_REL_ "GenSigTimeoutTime" BU_SG_REL_ ALBCU SG_ 992 BCM_Ign2InSta 1500;
BA_REL_ "GenSigTimeoutTime" BU_SG_REL_ CGW_CCU SG_ 1964 SCM_GST_Byte0 0;
BA_REL_ "GenSigTimeoutTime" BU_SG_REL_ CGW_CCU SG_ 1964 SCM_GST_Byte2 0;
BA_REL_ "GenSigTimeoutTime" BU_SG_REL_ CGW_CCU SG_ 1964 SCM_GST_Byte3 0;
BA_REL_ "GenSigTimeoutTime" BU_SG_REL_ CGW_CCU SG_ 1964 SCM_GST_Byte4 0;
BA_REL_ "GenSigTimeoutTime" BU_SG_REL_ CGW_CCU SG_ 1964 SCM_GST_Byte5 0;
BA_REL_ "GenSigTimeoutTime" BU_SG_REL_ CGW_CCU SG_ 1964 SCM_GST_Byte6 0;
BA_REL_ "GenSigTimeoutTime" BU_SG_REL_ CGW_CCU SG_ 1964 SCM_GST_Byte7 0;
BA_REL_ "GenSigTimeoutTime" BU_SG_REL_ CGW_CCU SG_ 1964 SCM_GST_Byte1 0;
BA_REL_ "GenSigTimeoutTime" BU_SG_REL_ CGW_CCU SG_ 1967 SWRC_GST_Byte0 0;
BA_REL_ "GenSigTimeoutTime" BU_SG_REL_ CGW_CCU SG_ 1967 SWRC_GST_Byte2 0;
BA_REL_ "GenSigTimeoutTime" BU_SG_REL_ CGW_CCU SG_ 1967 SWRC_GST_Byte3 0;
BA_REL_ "GenSigTimeoutTime" BU_SG_REL_ CGW_CCU SG_ 1967 SWRC_GST_Byte4 0;
BA_REL_ "GenSigTimeoutTime" BU_SG_REL_ CGW_CCU SG_ 1967 SWRC_GST_Byte5 0;
BA_REL_ "GenSigTimeoutTime" BU_SG_REL_ CGW_CCU SG_ 1967 SWRC_GST_Byte6 0;
BA_REL_ "GenSigTimeoutTime" BU_SG_REL_ CGW_CCU SG_ 1967 SWRC_GST_Byte7 0;
BA_REL_ "GenSigTimeoutTime" BU_SG_REL_ CGW_CCU SG_ 1967 SWRC_GST_Byte1 0;
BA_REL_ "GenSigTimeoutTime" BU_SG_REL_ SWRC SG_ 994 Warn_RrStRmndAlrmInfo 1500;
VAL_ 913 PSD_USMSetSta 0 "Default" 1 "Power Mode" 2 "Manual Mode" 3 "Invalid" ;
VAL_ 913 Lamp_HzrdSta 0 "Off" 1 "On" 2 "Inactive" 3 "RESERVED" ;
VAL_ 913 PSD_OptTyp 0 "Off" 1 "On(PSD is applied)" 2 "RESERVED" 3 "Error Indicator" ;
VAL_ 913 PSD_LHSEAActivated 0 "Inactivated" 1 "Activated" ;
VAL_ 913 PSD_RHSEAActivated 0 "Inactivated" 1 "Activated" ;
VAL_ 913 PSD_LHPSDLatchState 0 "Latch Primary position" 1 "Latch Before Primary position" 2 "Latch Secondary position" 3 "Latch Secondary mid position" 4 "Latch Unlatched position" 5 "Latch Unknown position" 6 "Latch Error position" 7 "RESERVED" ;
VAL_ 913 PSD_RHPSDLatchState 0 "Latch Primary position" 1 "Latch Before primary position" 2 "Latch Secondary position" 3 "Latch Secondary mid positon" 4 "Latch Unlatched position" 5 "Latch Unknown position" 6 "Latch Error position" 7 "RESERVED" ;
VAL_ 913 C_PSDOptLHRH 0 "Not applied" 1 "Both side" 2 "RH" 3 "LH" ;
VAL_ 913 PSD_AllDrOpnSetRValue 0 "Default" 1 "Off" 2 "PSD Open" 3 "PSD PTG Open" 4 "RESERVED" 5 "RESERVED" 6 "RESERVED" 7 "Invalid" ;
VAL_ 913 PSD_USMAllDrOpenSet 0 "Default" 1 "Off" 2 "All Door Open" 3 "Invalid" ;
VAL_ 913 PSD_ModSta 0 "Power Mode" 1 "Manual Mode" 2 "RESERVED" 3 "Error Indicator" ;
VAL_ 913 PSD_AutoWashModeSta 0 "Default" 1 "PSD Auto Wash Mode Off (Ready)" 2 "PSD Auto Wash Mode Off (Error)" 3 "PSD Auto Wash Mode On" 4 "RESERVED" 5 "RESERVED" 6 "RESERVED" 7 "Invalid" ;
VAL_ 911 ATS_RearLock_Set 0 "Unlock" 1 "LockON" 2 "Reserved" 3 "Invalid" ;
VAL_ 911 ATS_RrCurtainBtn 0 "Default" 1 "Open ON" 2 "Close ON" 3 "Invaild" ;
VAL_ 911 ATS_RrDrCurtainBtn 0 "Default" 1 "Open ON" 2 "Close ON" 3 "Invalid" ;
VAL_ 911 ATS_RLDrCurtainBtn 0 "Default" 1 "Open ON" 2 "Close ON" 3 "Invaild" ;
VAL_ 911 ATS_RRSunBlind 0 "Default" 1 "Open ON" 2 "Close ON" 3 "Stop ON" 4 "Reserved" 5 "Reserved" 6 "Reserved" 7 "Reserved" 8 "Reserved" 9 "Reserved" 10 "Reserved" 11 "Reserved" 12 "Reserved" 13 "Reserved" 14 "Reserved" 15 "Invalid" ;
VAL_ 911 ATS_FCS_LockTrayIniPwSet 0 "Default (Initial Value)" 1 "Initial Pw Set" 2 "reserved" 3 "Invaild" ;
VAL_ 911 ATS_FCS_LockTrayKeyPadNo 0 "0" 1 "1" 2 "2" 3 "3" 4 "4" 5 "5" 6 "6" 7 "7" 8 "8" 9 "9" 10 "reserved" 11 "reserved" 12 "reserved" 13 "reserved" 14 "reserved" 15 "Invalid" ;
VAL_ 911 ATS_FCS_LockTrayNoDel 0 "Default (Initial Value)" 1 "Number Delete" 2 "reserved" 3 "Invaild" ;
VAL_ 911 ATS_FCS_LockTrayNoClr 0 "Default (Initial Value)" 1 "Number Clear" 2 "reserved" 3 "Invaild" ;
VAL_ 911 ATS_FCS_LockTrayPwChange 0 "Default (Initial Value)" 1 "Password Change" 2 "reserved" 3 "Invaild" ;
VAL_ 911 ATS_FCS_LockTrayPwReset 0 "Default (Initial Value)" 1 "Password Reset" 2 "reserved" 3 "Invaild" ;
VAL_ 911 ATS_FCS_LockTrayCancel 0 "Default (Initial Value)" 1 "Cancel" 2 "reserved" 3 "Invaild" ;
VAL_ 2382594817 DATC_Crc6Val 0 "0x0x0~0xFFFF:CRCValue" 65535 "0x0x0~0xFFFF:CRCValue" ;
VAL_ 2382594817 DATC_AlvCnt6Val 0 "0x0x0~0xFF:AlvCntValue" 255 "0x0x0~0xFF:AlvCntValue" ;
VAL_ 2382594817 DATC_RrAcDis 0 "Default" 1 "OFF" 2 "ON" 3 "Error Indicator" ;
VAL_ 2382594817 DATC_MaxAcDis 0 "Off" 1 "On" 2 "Not used" 3 "Error Indicator" ;
VAL_ 2382594817 DATC_SyncDis 0 "SYNC Off" 1 "SYNC On" 2 "Not used" 3 "Error Indicator" ;
VAL_ 2382594817 DATC_OpSta 0 "DATC Off (Power Down)" 1 "DATC Normal" 2 "DATC System Off (Blower Off)" 3 "DATC Self Diagnosis" 4 "Not used" 5 "Not used" 6 "Not used" 7 "Error Indicator" ;
VAL_ 2382594817 DATC_FrDfgSta 0 "Off" 1 "On" 2 "Not used" 3 "Error Indicator" ;
VAL_ 2382594817 DATC_SmrtVntDis 0 "Off" 1 "Smart Ventilation" 2 "Smart CO2" 3 "Error Indicator" ;
VAL_ 2382594817 DATC_AutoDfgBlnkDis 0 "AutoDefogBlink Non Request" 1 "AutoDefogBlink Request" 2 "Not used" 3 "Error Indicator" ;
VAL_ 2382594817 DATC_AutoDfgSysOffDis 0 "'ADS OFF' display Off" 1 "'ADS OFF' display On" 2 "Not Used(Non-ADS)" 3 "Error Indicator" ;
VAL_ 2382594817 DATC_SchdldVntOpSta 0 "Default" 1 "Not Operation Status" 2 "Operation Status" 3 "Error Indicator" ;
VAL_ 2382594817 DATC_3rdAcDis 0 "Default" 1 "OFF" 2 "ON" 3 "Error Indicator" ;
VAL_ 2382594817 DATC_ArClnIND 0 "Default" 1 "OFF" 2 "ON" 3 "Error Indicator" ;
VAL_ 2382594817 DATC_RrDfgInd 0 "Default" 1 "OFF" 2 "ON" 3 "Error Indicator" ;
VAL_ 2382594817 DATC_FrModDEFInd 0 "Default" 1 "OFF" 2 "ON" 3 "Error Indicator" ;
VAL_ 2382594817 DATC_FrModVentInd 0 "Default" 1 "OFF" 2 "ON" 3 "Error Indicator" ;
VAL_ 2382594817 DATC_FrModFloorInd 0 "Default" 1 "OFF" 2 "ON" 3 "Error Indicaotr" ;
VAL_ 905 RR_CrashUnlockCmd 0 "Off" 1 "Unlock (Crash)" ;
VAL_ 905 Warn_RrRtDrSwSta_SBCM 0 "Close" 1 "Open" 2 "RESERVED" 3 "Error Indicator" ;
VAL_ 905 DoorLock_RrRtDrUnLkSta_SBCM 0 "Lock" 1 "Unlock" 2 "Not Used" 3 "Error Indicator" ;
VAL_ 905 RR_SEAActivated 0 "InActivated" 1 "Activated" 2 "Not Used" 3 "Error Indicator" ;
VAL_ 905 RR_SEAWarn 0 "SEA Right Warning OFF" 1 "SEA Right Warning ON" 2 "Reserved" 3 "Invalid" ;
VAL_ 905 RR_SEWWarn 0 "SEW Right Warning OFF" 1 "SEW Right Warning ON" 2 "Reserved" 3 "Invalid" ;
VAL_ 905 RR_ReleaseWarn 0 "Release Warning OFF" 1 "Release Warning ON" 2 "Reserved" 3 "Invalid" ;
VAL_ 905 RR_SWFailAlarm 0 "Off" 1 "On" 2 "Not Used" 3 "Error Indicator" ;
VAL_ 905 RR_ChildLock_ActnFlSta 0 "OK" 1 "Failed" 2 "Not Used" 3 "Error Indicator" ;
VAL_ 905 RR_MRActivationAlarm 0 "Off" 1 "On" 2 "Not Used" 3 "Error Indicator" ;
VAL_ 905 RR_ChildLock_Status 0 "ChildLock On" 1 "ChildLock Off" 2 "RESERVED" 3 "RESERVED" ;
VAL_ 905 USM_RRGhostDoorSta 0 "Default" 1 "Off" 2 "On" 3 "Invalid" ;
VAL_ 905 DoorLock_PDSLkSwSta_RR 0 "Lock" 1 "Unlock" 2 "Not Used" 3 "Error Indicator" ;
VAL_ 905 PDS_TypeOption_RR 0 "Off" 1 "On" 2 "Not Used" 3 "Error Indicator" ;
VAL_ 905 RRDoorPushAlarm 0 "Off" 1 "On" 2 "Not Used" 3 "Error Indicator" ;
VAL_ 904 PSM_DrvReclinePosition 0 "0x0x00~0xFE:POSITION" 254 "0x0x00~0xFE:POSITION" 255 "invalid" ;
VAL_ 904 PSM_EsyAcsGetOffSta 0 "off" 1 "on" 2 "Not Used" 3 "Error Indicator" ;
VAL_ 904 PSM_EsyAcsStpSta 0 "off" 1 "on" 2 "Not Used" 3 "Error Indicator" ;
VAL_ 904 PSM_SWVerMajor1 0 "0x0x0~0x7F:ASCII Code Value (HEX)" 127 "0x0x0~0x7F:ASCII Code Value (HEX)" ;
VAL_ 904 PSM_SWVerMinor1 0 "0x0x0~0x7F:ASCII Code Value (HEX)" 127 "0x0x0~0x7F:ASCII Code Value (HEX)" ;
VAL_ 904 PSM_SWVerMinor2 0 "0x0x0~0x7F:ASCII Code Value (HEX)" 127 "0x0x0~0x7F:ASCII Code Value (HEX)" ;
VAL_ 904 PSM_HDPSpprtSWVer 0 "Requirement Spec Version" 1 "Requirement Spec Version" 2 "Requirement Spec Version" 3 "Requirement Spec Version" 4 "Requirement Spec Version" 5 "Requirement Spec Version" 6 "Requirement Spec Version" 7 "Requirement Spec Version" 8 "Requirement Spec Version" 9 "Requirement Spec Version" 10 "Requirement Spec Version" 11 "Requirement Spec Version" 12 "Requirement Spec Version" 13 "Requirement Spec Version" 14 "Requirement Spec Version" 15 "Requirement Spec Version" 16 "Requirement Spec Version" 17 "Requirement Spec Version" 18 "Requirement Spec Version" 19 "Requirement Spec Version" 20 "Requirement Spec Version" 21 "Requirement Spec Version" 22 "Requirement Spec Version" 23 "Requirement Spec Version" 24 "Requirement Spec Version" 25 "Requirement Spec Version" 26 "Requirement Spec Version" 27 "Requirement Spec Version" 28 "Requirement Spec Version" 29 "Requirement Spec Version" 30 "Requirement Spec Version" 31 "Requirement Spec Version" ;
VAL_ 904 PSM_DrvHeightPosition 0 "0x0x00~0xFE:POSITION" 254 "0x0x00~0xFE:POSITION" 255 "invalid" ;
VAL_ 904 PSM_DrvSlidePosition 0 "0x0x00~0xFE:POSITION" 254 "0x0x00~0xFE:POSITION" 255 "invalid" ;
VAL_ 904 PSM_EsyAcsGetOnSta 0 "off" 1 "on" 2 "Not Used" 3 "Error Indicator" ;
VAL_ 903 PSM_DrvStSldFwdDis 0 "default" 1 "off" 2 "on" 3 "invalid" ;
VAL_ 903 PSM_DrvStTiltDnDis 0 "default" 1 "off" 2 "on" 3 "invalid" ;
VAL_ 903 PSM_DrvStHghtUpDis 0 "default" 1 "off" 2 "on" 3 "invalid" ;
VAL_ 903 PSM_DrvStHghtDnDis 0 "default" 1 "off" 2 "on" 3 "invalid" ;
VAL_ 903 PSM_DrvStCushExtBckwdDis 0 "default" 1 "off" 2 "on" 3 "invalid" ;
VAL_ 903 PSM_DrvStCushExtFwdDis 0 "default" 1 "off" 2 "on" 3 "invalid" ;
VAL_ 903 PSM_DrvStSldBckwdDis 0 "default" 1 "off" 2 "on" 3 "invalid" ;
VAL_ 903 PSM_DrvStHdRstUpDis 0 "default" 1 "off" 2 "on" 3 "invalid" ;
VAL_ 903 PSM_DrvStHdRstDnDis 0 "default" 1 "off" 2 "on" 3 "invalid" ;
VAL_ 903 PSM_DrvStHdRstFwdDis 0 "default" 1 "off" 2 "on" 3 "invalid" ;
VAL_ 903 PSM_DrvStHdRstBckwdDis 0 "default" 1 "off" 2 "on" 3 "invalid" ;
VAL_ 903 PSM_DrvStLmbrDefDis 0 "default" 1 "off" 2 "on" 3 "invalid" ;
VAL_ 903 PSM_DrvStLmbrLoDis 0 "default" 1 "off" 2 "on" 3 "invalid" ;
VAL_ 903 PSM_DrvStLmbrMdlDis 0 "default" 1 "off" 2 "on" 3 "invalid" ;
VAL_ 903 PSM_DrvStLmbrUpDis 0 "default" 1 "off" 2 "on" 3 "invalid" ;
VAL_ 903 PSM_DrvStReclneFwdDis 0 "default" 1 "off" 2 "on" 3 "invalid" ;
VAL_ 903 PSM_DrvStBlstrDefDis 0 "default" 1 "off" 2 "on" 3 "invalid" ;
VAL_ 903 PSM_DrvStBlstrInfDis 0 "default" 1 "off" 2 "on" 3 "invalid" ;
VAL_ 903 PSM_DrvStReclneBckwdDis 0 "default" 1 "off" 2 "on" 3 "invalid" ;
VAL_ 903 PSM_DrvStTiltUpDis 0 "default" 1 "off" 2 "on" 3 "invalid" ;
VAL_ 902 PSM_DrvStEsyAcsUSMSta 0 "Default Value" 1 "Off (Disable)" 2 "50mmOn (Enable)" 3 "75mmOn (Enable)" 4 "Reserved" 5 "Reserved" 6 "Reserved" 7 "Invalid" ;
VAL_ 902 PSM_SeatPosPlyBck_Sta 0 "Default" 1 "Moving" 2 "Moving Finish" 3 "Moving not Finish" 4 "Not Used" 5 "Not Used" 6 "STOP" 7 "Not Used" ;
VAL_ 902 PSM_SeatPos_Sta 0 "Default" 1 "Memory1" 2 "Memory2" 3 "Memory3" 4 "Not Used" 5 "Not Used" 6 "Not Used" 7 "Any Postion" ;
VAL_ 902 PSM_SeatPosSldLmt_Sta 0 "Default" 1 "Slide Fwd Limit" 2 "Slide Bwd Limit" 3 "Not Initialized" ;
VAL_ 902 PSM_SeatPosRclnLmt_Sta 0 "Default" 1 "Recline Fwd Limit" 2 "Recline Bwd Limit" 3 "Not Initialized" ;
VAL_ 902 SmrtIMS_StatureRspVal 0 "Default" 1 "Less than 147.5cm" 2 "147.5~152.4cm" 3 "152.5~157.4cm" 4 "157.5~162.4cm" 5 "162.5~167.4cm" 6 "167.5~172.4cm" 7 "172.5~177.4cm" 8 "177.5~182.4cm" 9 "182.5~187.4cm" 10 "187.5~192.4cm" 11 "192.5~197.4cm" 12 "More than 197.5cm" 13 "Reserved" 14 "Reserved" 15 "Invalid" ;
VAL_ 902 SmrtIMS_SeatedHghtRspVal 0 "Default" 1 "Tall" 2 "Middle" 3 "Short" 4 "Reserved" 5 "Reserved" 6 "Reserved" 7 "Reserved" 8 "Reserved" 9 "Reserved" 10 "Reserved" 11 "Reserved" 12 "Reserved" 13 "Reserved" 14 "Reserved" 15 "Invalid" ;
VAL_ 902 SmrtIMS_WghtRspVal 0 "Default" 1 "Under 49.4kg" 2 "49.5~59.4kg" 3 "59.5~69.4kg" 4 "69.5~79.4kg" 5 "79.5~89.4kg" 6 "89.5~99.4kg" 7 "99.5~109.4kg" 8 "109.5~119.4kg" 9 "More than119.5kg" 10 "Reserved" 11 "Reserved" 12 "Reserved" 13 "Reserved" 14 "Reserved" 15 "Invalid" ;
VAL_ 902 SmartIMS_DisReq 0 "Stop" 1 "Moving(recommend position)" 2 "Moving(manual switch, IMS)" 3 "Current Position Analysis" 4 "Move to setting page" 5 "Reserved" 6 "Reserved" 7 "Invalid" ;
VAL_ 902 SmrtIMS_ExitSta 0 "normal" 1 "not IGN" 2 "not P or over 3km/h" 3 "cranking" 4 "seat moving" 5 "PSM is not initialized" 6 "low voltage" 7 "reserved" ;
VAL_ 902 PSM_DrvStRlxTiltUpDis 0 "Default" 1 "Off" 2 "On" 3 "Invalid" ;
VAL_ 902 PSM_DrvStRlxTiltDnDis 0 "Default" 1 "Off" 2 "On" 3 "Invalid" ;
VAL_ 902 PSM_DrvStLegUpDis 0 "Default" 1 "Off" 2 "On" 3 "Invalid" ;
VAL_ 902 PSM_DrvStLegDnDis 0 "Default" 1 "Off" 2 "On" 3 "Invalid" ;
VAL_ 902 Drv_2ndStAutoRlxEnable 0 "Default" 1 "Enable" 2 "Disable" 3 "Invalid" ;
VAL_ 902 Drv_AutoRlxSta 0 "Default" 1 "Auto Relaxion moving" 2 "Reserved" 3 "Invalid" ;
VAL_ 902 Drv_AutoReturnSta 0 "Default" 1 "Auto Return moving" 2 "RESERVED" 3 "Invalid" ;
VAL_ 902 PSM_IMSOptTyp 0 "Default" 1 "IMS Option" 2 "IMS&Smart IMS Option" 3 "Error Indicator" ;
VAL_ 1016 GNSS_MM_type 0 "WGS84" 1 "Bessel" 2 "Coordshift(for china)" 15 "invalid" ;
VAL_ 1019 HU_MoodTherapyDrSeat 0 "Default" 1 "Off" 2 "On" 3 "Invalid" ;
VAL_ 1019 HU_VitalityFragrance 0 "Default" 1 "Off" 2 "On" 3 "Invalid" ;
VAL_ 1019 HU_VitalityCurtain 0 "Default" 1 "Off" 2 "On" 3 "Invalid" ;
VAL_ 1019 HU_DelightMoodLamp 0 "Default" 1 "Off" 2 "On" 3 "Invalid" ;
VAL_ 1019 HU_DelightFragrance 0 "Default" 1 "Off" 2 "On" 3 "Invalid" ;
VAL_ 1019 HU_DelightCurtain 0 "Default" 1 "Off" 2 "On" 3 "Invalid" ;
VAL_ 1019 HU_MoodTherapyPsSeat 0 "Default" 1 "Off" 2 "On" 3 "Invalid" ;
VAL_ 1019 HU_CareMoodLamp 0 "Default" 1 "Off" 2 "On" 3 "Invalid" ;
VAL_ 1019 HU_CareFragrance 0 "Default" 1 "Off" 2 "On" 3 "Invalid" ;
VAL_ 1019 HU_CareMassage 0 "Default" 1 "Off" 2 "On" 3 "Invalid" ;
VAL_ 1019 HU_CareCurtain 0 "Default" 1 "Off" 2 "On" 3 "Invalid" ;
VAL_ 1019 HU_ComfortMoodLamp 0 "Default" 1 "Off" 2 "On" 3 "Invalid" ;
VAL_ 1019 HU_ComfortFragrance 0 "Default" 1 "Off" 2 "On" 3 "Invalid" ;
VAL_ 1019 HU_ComfortMassage 0 "Default" 1 "Off" 2 "On" 3 "Invalid" ;
VAL_ 1019 HU_ComfortCurtain 0 "Default" 1 "Off" 2 "On" 3 "Invalid" ;
VAL_ 1019 HU_MoodTherapyMode 0 "Default" 1 "Off" 2 "Vitality" 3 "Delight" 4 "Care" 5 "Comfort" 6 "Reserved" 7 "Invalid" ;
VAL_ 1019 HU_MoodTherapyRlSeat 0 "Default" 1 "Off" 2 "On" 3 "Invalid" ;
VAL_ 1019 HU_MoodTherapyRrSeat 0 "Default" 1 "Off" 2 "On" 3 "Invalid" ;
VAL_ 1019 HU_VitalityMoodLamp 0 "Default" 1 "Off" 2 "On" 3 "Invalid" ;
VAL_ 2235651329 APSB_Crc1Val 0 "0x0x0~0xFFFF:CRCValue" 65535 "0x0x0~0xFFFF:CRCValue" ;
VAL_ 2235651329 APSB_AlvCnt1Val 0 "0x0x0~0xFF:AlvCntValue" 255 "0x0x0~0xFF:AlvCntValue" ;
VAL_ 2235651329 APSB_CrashActvSta 0 "APSB Inactive" 1 "APSB is active" 2 "Rserved" 3 "Rserved" ;
VAL_ 2235651329 APSB_RRDrvImpt 0 "Rough Road Impact is Inactive" 1 "Rough Road  Impact is PSB Front Active" 2 "Rough Road  Impact is PSB Rear Active" 3 "Rough Road  Impact is Failure" 4 "Reserved" 5 "Reserved" 6 "Reserved" 7 "Reserved" ;
VAL_ 2235651329 APSB_FCAFrImpt 0 "FCA Impact is Inactive" 1 "FCA Impact is PSB Front Active" 2 "FCA Impact is PSB Rear Active" 3 "FCA Impact is Failure" 4 "Reserved" 5 "Reserved" 6 "Reserved" 7 "Reserved" ;
VAL_ 2235651329 APSB_MinFrImpt 0 "Minor Front Impact is Inactive" 1 "Minor Front Impact is PSB Front Active" 2 "Minor Front Impact is PSB Rear Active" 3 "Minor Front Impact is Failure" 4 "Reserved" 5 "Reserved" 6 "Reserved" 7 "Reserved" ;
VAL_ 2235651329 APSB_MinSidImpt 0 "Minor Side Impact is Inactive" 1 "Minor Side Impact is PSB Front Active" 2 "Minor Side Impact is PSB Rear Active" 3 "Minor Side Impact is Failure" 4 "Reserved" 5 "Reserved" 6 "Reserved" 7 "Reserved" ;
VAL_ 2235651329 APSB_MinRollDetn 0 "Minor Roll Detection is Inactive" 1 "Minor Roll Detection  is PSB Front Active" 2 "Minor Roll Detection  is PSB Rear Active" 3 "Minor Roll Detection  is Failure" 4 "Reserved" 5 "Reserved" 6 "Reserved" 7 "Reserved" ;
VAL_ 2235651329 APSB_MinRearImpt 0 "Minor Rear Impact is Inactive" 1 "Minor Rear Impact is PSB Front Active" 2 "Minor Rear Impact is PSB Rear Active" 3 "Minor Rear Impact is Failure" 4 "Reserved" 5 "Reserved" 6 "Reserved" 7 "Reserved" ;
VAL_ 1003 PSM_BzrOnRLReq 0 "off" 1 "on" 2 "Not Used" 3 "Error Indicator" ;
VAL_ 1003 RLPSM_RearModeState 0 "Default" 1 "Off" 2 "Relax Mode" 3 "Return Mode" 4 "RESERVED" 5 "RESERVED" 6 "RESERVED" 7 "Invalid" ;
VAL_ 1003 RLPSM_RLStEsyAcsUSMSta 0 "Default" 1 "Off" 2 "On" 3 "Invalid" ;
VAL_ 1003 RLPSM_RLSlidePosition 0 "0x0x00~0xFE:POSITION" 254 "0x0x00~0xFE:POSITION" 255 "invalid" ;
VAL_ 1003 RLPSM_SeatPos_Sta 0 "Default" 1 "Memory1" 2 "Memory2" 3 "Memory3" 4 "Not Used" 5 "Not Used" 6 "Not Used" 7 "Any Postion" ;
VAL_ 1003 RLPSM_SeatPosSldLmt_Sta 0 "Default" 1 "Slide Fwd Limit" 2 "Slide Bwd Limit" 3 "Not Initialized" ;
VAL_ 1003 RLPSM_LimSetSta 0 "Default" 1 "Initialized" 2 "Not Initialized" 3 "Reserved" ;
VAL_ 1002 BLTN_CAM_HU_UI_Mode 0 "HU UI mode." 1 "BLTN_CAM mode" 2 "Preparing BLTN_CAM Mode" 3 "BLTN_CAM Setting Mode" 4 "RESERVED" 5 "RESERVED" 6 "RESERVED" 7 "RESERVED" 8 "RESERVED" 9 "RESERVED" 10 "RESERVED" 11 "RESERVED" 12 "RESERVED" 13 "BLTN_CAM Not Ready to be HU UI Mode" 14 "BLTN_CAM is in Error mode." 15 "Invalid" ;
VAL_ 1002 BLTN_CAM_SD_Format_Op_State 0 "Default" 1 "Formatting" 2 "Format Complete." 3 "invalid" ;
VAL_ 1002 BLTN_CAM_PEV_Recorded 0 "Default" 1 "Off" 2 "Park Event Recorded" 3 "invalid" ;
VAL_ 1002 BLTN_CAM_PEV_Count 0 "0x0x0~0xC8:the number of the Park Event Record(0~200)" 200 "0x0x0~0xC8:the number of the Park Event Record(0~200)" 201 "Reserved" 202 "Reserved" 203 "Reserved" 204 "Reserved" 205 "Reserved" 206 "Reserved" 207 "Reserved" 208 "Reserved" 209 "Reserved" 210 "Reserved" 211 "Reserved" 212 "Reserved" 213 "Reserved" 214 "Reserved" 215 "Reserved" 216 "Reserved" 217 "Reserved" 218 "Reserved" 219 "Reserved" 220 "Reserved" 221 "Reserved" 222 "Reserved" 223 "Reserved" 224 "Reserved" 225 "Reserved" 226 "Reserved" 227 "Reserved" 228 "Reserved" 229 "Reserved" 230 "Reserved" 231 "Reserved" 232 "Reserved" 233 "Reserved" 234 "Reserved" 235 "Reserved" 236 "Reserved" 237 "Reserved" 238 "Reserved" 239 "Reserved" 240 "Reserved" 241 "Reserved" 242 "Reserved" 243 "Reserved" 244 "Reserved" 245 "Reserved" 246 "Reserved" 247 "Reserved" 248 "Reserved" 249 "Reserved" 250 "Reserved" 251 "Reserved" 252 "Reserved" 253 "Over than 200 count" 254 "the park event record is not recorded" 255 "invalid" ;
VAL_ 1002 BLTN_CAM_Ind_Req 0 "Default" 1 "Built-in Cam System or Camera Error" 2 "Manual Recording or Event Recording" 3 "Time-lapse Recording" 4 "Built-in Cam SD Card Replace Warning or SD Card Error" 5 "On while Driving Recording" 6 "On while Parked Recording" 7 "Reserved" 8 "Reserved" 9 "Reserved" 10 "Reserved" 11 "Reserved" 12 "Reserved" 13 "Reserved" 14 "Reserved" 15 "Reserved" 16 "Reserved" 17 "Reserved" 18 "Reserved" 19 "Reserved" 20 "Reserved" 21 "Reserved" 22 "Reserved" 23 "Reserved" 24 "Reserved" 25 "Reserved" 26 "Reserved" 27 "Reserved" 28 "Reserved" 29 "Reserved" 30 "Reserved" 31 "Invalid" ;
VAL_ 1002 BLTN_CAM_LVDS_Mode_State 0 "Front and Rear Camera" 1 "Front Camera for AR Navi." 2 "Built-In Cam Engineer Mode" 3 "Reserved" ;
VAL_ 1002 BLTN_CAM_PrkOp_Termiate_Info 0 "Default" 1 "Park operation terminated earlier than user set because of Bat. SoC" 2 "Park operation terminated earlier than user set because of SD Card Problem" 3 "Park operation terminated earlier than user set because of Built-in Cam internal Error" 4 "Park operation terminated earlier than user set because of SD Card removed or not detected" 5 "Park operation started because of SD Card inserted" 6 "Park operation terminate on time which user set." 7 "Invalid" ;
VAL_ 1002 BLTN_CAM_Display 0 "HU mode" 1 "Built-in Cam mode" 2 "popup mode" 3 "Built-in Cam mode Terminate Request by Home-button" 4 "Built-in Cam mode Terminate Request by Back-button" 5 "Built-in Cam update mode" 6 "Ready to update" 7 "Update complete" 8 "USB removed" 9 "Update fail (USB error)" 10 "Reserved" 11 "Reserved" 12 "Reserved" 13 "Reserved" 14 "Built-in Cam is in error mode" 15 "Invalid" ;
VAL_ 1002 BLTN_CAM_WiFi_State 0 "Off" 1 "On, Ready to Connect Mobile Phone." 2 "On, Mobile Phone Connected." 3 "Off - Password is not Set." 4 "Reserved" 5 "Reserved" 6 "Reserved" 7 "Reserved" 8 "Reserved" 9 "Reserved" 10 "Reserved" 11 "Reserved" 12 "Reserved" 13 "Reserved" 14 "Reserved" 15 "invalid" ;
VAL_ 1005 RLPSU_FldDis 0 "default" 1 "Off" 2 "On" 3 "Invalid" ;
VAL_ 1005 RLPSU_TiltDownDis 0 "default" 1 "Off" 2 "On" 3 "Invalid" ;
VAL_ 1005 RLPSU_RclFwdDis 0 "default" 1 "Off" 2 "On" 3 "Invalid" ;
VAL_ 1005 RLPSU_RclBwdDis 0 "default" 1 "Off" 2 "On" 3 "Invalid" ;
VAL_ 1005 RLPSU_RlxModeDis 0 "default" 1 "Off" 2 "On" 3 "Invalid" ;
VAL_ 1005 RLPSU_Folding_SW 0 "default" 1 "Off" 2 "On" 3 "Invalid" ;
VAL_ 1005 RLPSU_UnFldDis 0 "default" 1 "Off" 2 "On" 3 "Invalid" ;
VAL_ 1005 RLPSU_Unfolding_SW 0 "default" 1 "Off" 2 "On" 3 "Invalid" ;
VAL_ 1005 RLPSU_WalkIn_SW 0 "default" 1 "Off" 2 "On" 3 "Invalid" ;
VAL_ 1005 RLPSU_UnwalkIn_SW 0 "default" 1 "Off" 2 "On" 3 "Invalid" ;
VAL_ 1005 RLPSU_Folding_Postion 0 "deafult" 1 "Walk In" 2 "Unwalk In" 3 "Walk In(Moving)" 4 "Unwalk In(Moving)" 5 "Folded" 6 "UnFolded" 7 "Folding (Moving)" 8 "UnFolding (Moving)" 9 "RESERVED" 10 "RESERVED" 11 "RESERVED" 12 "RESERVED" 13 "RESERVED" 14 "RESERVED" 15 "Invalid" ;
VAL_ 1005 RLPSU_Folding_State_PopUp 0 "Default" 1 "Folded(finished)" 2 "Unfolded(finished)" 3 "Mode-fail (anti-pinch)" 4 "Mode-fail (TGS&Break Condition)" 5 "Mode-fail (system error)" 6 "RESERVED" 7 "Invalid" ;
VAL_ 1005 RLPSU_Relax_State_Popup 0 "Default" 1 "Relaxed(finished)" 2 "Unrelaxed(finished)" 3 "Relax (Relaxing)" 4 "Return (Returning)" 5 "RESERVED" 6 "RESERVED" 7 "Invalid" ;
VAL_ 1005 RLPSU_SlideFwdDis 0 "default" 1 "Off" 2 "On" 3 "Invalid" ;
VAL_ 1005 RLPSU_SlideBwdDis 0 "default" 1 "Off" 2 "On" 3 "Invalid" ;
VAL_ 1005 RLPSU_WalkInDis 0 "default" 1 "Off" 2 "On" 3 "Inavlid" ;
VAL_ 1005 RLPSU_WalkInState 0 "default" 1 "Enable" 2 "Disable" 3 "Invalid" ;
VAL_ 1005 RLPSU_UnWalkInDis 0 "default" 1 "Off" 2 "On" 3 "Invalid" ;
VAL_ 1005 RLPSU_TiltUpDis 0 "default" 1 "Off" 2 "On" 3 "Invalid" ;
VAL_ 1004 CF_RCS_SwTyp 0 "Not Endless Dial" 1 "Endless Dial (CAN)" ;
VAL_ 1004 CF_RCS_OffRoad 0 "DEFAULT" 1 "SNOW" 2 "SAND" 3 "MUD" 4 "AUTO" ;
VAL_ 1004 CF_RCS_BtnSta 0 "OnRoad" 1 "OffRoad" ;
VAL_ 1004 CF_RCS_RotateEnd 0 "Default" 1 "Rotate End" ;
VAL_ 1004 CF_RCS_4wdLocking 0 "Off" 1 "On" ;
VAL_ 1004 RCS_Direction_SW 0 "Default" 1 "+, Right, Up, Push" 2 "-, Left, Down" 3 "Invalid" ;
VAL_ 1004 CF_RCS_DrvMod 0 "NORMAL(COMFORT)" 1 "ECO" 2 "SPORT" 3 "SMART" ;
VAL_ 1004 RCS_Mode_SW 0 "Default" 1 "Push" 2 "Invalid" 3 "RESERVED" ;
VAL_ 1004 CF_RCS_TowMode 0 "Default" 1 "Off" 2 "On" 3 "Invalid" ;
VAL_ 1007 ATS_LEDBgtnsUpDn 0 "Reserved" 1 "Brightness Up" 2 "Brightness Down" 3 "Invalid" ;
VAL_ 1007 ATS_FrMoodOn_Req 0 "Default" 1 "Off" 2 "On" 3 "Invalid" ;
VAL_ 1007 ATS_DoorOn_Req 0 "Default" 1 "Off" 2 "On" 3 "Invalid" ;
VAL_ 1007 ATS_RrMapLftOn_Req 0 "Default" 1 "Off" 2 "On" 3 "Invalid" ;
VAL_ 1007 ATS_RrMapRtOn_Req 0 "Default" 1 "Off" 2 "On" 3 "Invalid" ;
VAL_ 1007 ATS_RrRoomOn_Req 0 "Default" 1 "Off" 2 "On" 3 "Invalid" ;
VAL_ 1007 ATS_LEDClrUpDn 0 "Reserved" 1 "Color Up" 2 "Color Down" 3 "Invalid" ;
VAL_ 1007 ATS_RrMoodOn_Req 0 "Default" 1 "Off" 2 "On" 3 "Invalid" ;
VAL_ 1007 ATS_LEDClr_Set 0 "Color 1Step" 1 "Color 2Step" 2 "Color 3Step" 3 "Not Used" 4 "Not Used" 5 "Not Used" 6 "Invalid" 7 "System Fail" ;
VAL_ 1007 ATS_LEDBgtns_Set 0 "Brightness 1Step" 1 "Brightness 2Step" 2 "Brightness 3Step" 3 "Not Used" 4 "Not Used" 5 "Not Used" 6 "Invalid" 7 "System Fail" ;
VAL_ 1007 ATS_LEDClrUpDnBtn 0 "Button Off" 1 "Color Up" 2 "Color Down" 3 "Invalid" ;
VAL_ 1007 ATS_LEDBgtnsUpDnBtn 0 "Button Off" 1 "Brightness Up" 2 "Brightness Down" 3 "Invalid" ;
VAL_ 1007 ATS_FrMapLftOn_Req 0 "Default" 1 "Off" 2 "On" 3 "Invalid" ;
VAL_ 1007 ATS_FrMapRtOn_Req 0 "Default" 1 "Off" 2 "On" 3 "Invalid" ;
VAL_ 1007 ATS_FrRoomOn_Req 0 "Default" 1 "Off" 2 "On" 3 "Invalid" ;
VAL_ 1006 RRPSU_FldDis 0 "default" 1 "Off" 2 "On" 3 "Invalid" ;
VAL_ 1006 RRPSU_TiltDnDis 0 "default" 1 "Off" 2 "On" 3 "Invalid" ;
VAL_ 1006 RRPSU_RecFwdDis 0 "default" 1 "Off" 2 "On" 3 "Invalid" ;
VAL_ 1006 RRPSU_RecBwdDis 0 "default" 1 "Off" 2 "On" 3 "Invalid" ;
VAL_ 1006 RRPSU_RlxModeDis 0 "default" 1 "Off" 2 "On" 3 "Invalid" ;
VAL_ 1006 RRPSU_Folding_SW 0 "default" 1 "Off" 2 "On" 3 "Invalid" ;
VAL_ 1006 RRPSU_UnFldDis 0 "default" 1 "Off" 2 "On" 3 "Invalid" ;
VAL_ 1006 RRPSU_Unfolding_SW 0 "default" 1 "Off" 2 "On" 3 "Invalid" ;
VAL_ 1006 RRPSU_WalkIn_SW 0 "default" 1 "Off" 2 "On" 3 "Invalid" ;
VAL_ 1006 RRPSU_UnwalkIn_SW 0 "default" 1 "Off" 2 "On" 3 "Invalid" ;
VAL_ 1006 RRPSU_Folding_Postion 0 "deafult" 1 "Walk In" 2 "Unwalk In" 3 "Walk In(Moving)" 4 "Unwalk In(Moving)" 5 "Folded" 6 "UnFolded" 7 "Folding (Moving)" 8 "UnFolding (Moving)" 9 "Unused" 10 "Unused" 11 "Unused" 12 "Unused" 13 "Unused" 14 "Unused" 15 "Invalid" ;
VAL_ 1006 RRPSU_Folding_State_Popup 0 "Default" 1 "Relaxed(finished)" 2 "Unfolded(finished)" 3 "Mode-fail(anti-pinch)" 4 "Mode-Fail(TGS&Break Condition)" 5 "Mode-fail(system error)" 6 "Unused" 7 "Invalid" ;
VAL_ 1006 RRPSU_Relax_State_Popup 0 "Default" 1 "Relaxed(finished)" 2 "UnRelaxed(finished)" 3 "Relax (Relaxing)" 4 "Return(Returning)" 5 "Unused" 6 "Unused" 7 "Invalid" ;
VAL_ 1006 RRPSU_SlideFwdDis 0 "default" 1 "Off" 2 "On" 3 "Invalid" ;
VAL_ 1006 RRPSU_SlideBwdDis 0 "default" 1 "Off" 2 "On" 3 "Invalid" ;
VAL_ 1006 RRPSU_WalkinDis 0 "default" 1 "Off" 2 "On" 3 "Invalid" ;
VAL_ 1006 RRPSU_WalkInState 0 "default" 1 "Enable" 2 "Disable" 3 "Invalid" ;
VAL_ 1006 RRPSU_UnwalkinDis 0 "default" 1 "Off" 2 "On" 3 "Invalid" ;
VAL_ 1006 RRPSU_TiltUpDis 0 "default" 1 "Off" 2 "On" 3 "Invalid" ;
VAL_ 2353206529 CLU_Crc20Val 0 "0x0x0~0xFFFF:CRCValue" 65535 "0x0x0~0xFFFF:CRCValue" ;
VAL_ 2353206529 CLU_AlvCnt20Val 0 "0x0x0~0xFF:AlvCntValue" 255 "0x0x0~0xFF:AlvCntValue" ;
VAL_ 2353206529 CLU_SndType 0 "Cluster applied speaker" 1 "Cluster applied buzzer" 2 "Not used" 3 "Error Indicator" ;
VAL_ 2353206529 CLU_ClusterUSM 0 "Default" 1 "Cluster not applied USM" 2 "Cluster applied USM" 3 "Reserved" ;
VAL_ 992 BCM_Crc2Val 0 "0x0x0~0xFF:CRCValue" 255 "0x0x0~0xFF:CRCValue" ;
VAL_ 992 BCM_AlvCnt2Val 0 "AlvCntValue" 1 "AlvCntValue" 2 "AlvCntValue" 3 "AlvCntValue" 4 "AlvCntValue" 5 "AlvCntValue" 6 "AlvCntValue" 7 "AlvCntValue" 8 "AlvCntValue" 9 "AlvCntValue" 10 "AlvCntValue" 11 "AlvCntValue" 12 "AlvCntValue" 13 "AlvCntValue" 14 "AlvCntValue" 15 "AlvCntValue" ;
VAL_ 992 BAlarm_BglrAlrmCurrentSta 0 "Off" 1 "DisArm" 2 "Arm" 3 "PreArm" 4 "ArmWait" 5 "ArmHold(Trunk)" 6 "ReArm" 7 "AutoLockTimer1" 8 "AutoLockTimer2" 9 "Alarm" 10 "Default" 11 "AutoLockTimer3(Tailgate)" 12 "Reserved" 13 "Reserved" 14 "Not Used" 15 "Error Indicator" ;
VAL_ 992 BAlarm_BglrAlrmSta 0 "DIS-,PRE-,AUTOLOCKTIMER1,2,3(TG)" 1 "ARM,-WAIT,RE-,ALARM,-HD(Trunk)" 2 "Not Used" 3 "Error Indicator" ;
VAL_ 992 BAlarm_PncAlrmSta 0 "Off" 1 "On (Panic Alarm ON)" 2 "Not Used" 3 "Error Indicator" ;
VAL_ 992 BAlarm_StrtInhbtRlySta 0 "Off" 1 "On" 2 "Not Used" 3 "Error Indicator" ;
VAL_ 992 BAlarm_BrglrHrnRlySta 0 "Off" 1 "On" 2 "Not Used" 3 "Error Indicator" ;
VAL_ 992 BCM_KeyInSta 0 "Off (Key removed)" 1 "On (Key inserted)" 2 "Not Used" 3 "Error Indicator" ;
VAL_ 992 BCM_AccInSta 0 "Acc Off" 1 "Acc On" 2 "Not Used" 3 "Error Indicator" ;
VAL_ 992 BCM_Ign1InSta 0 "IGN1 Off" 1 "IGN1 On" 2 "Not Used" 3 "Error Indicator" ;
VAL_ 992 BCM_Ign2InSta 0 "IGN2 Off" 1 "IGN2 On" 2 "Not Used" 3 "Error Indicator" ;
VAL_ 994 BCM_Crc4Val 0 "0x0x0~0xFF:CRCValue" 255 "0x0x0~0xFF:CRCValue" ;
VAL_ 994 BCM_AlvCnt4Val 0 "AlvCntValue" 1 "AlvCntValue" 2 "AlvCntValue" 3 "AlvCntValue" 4 "AlvCntValue" 5 "AlvCntValue" 6 "AlvCntValue" 7 "AlvCntValue" 8 "AlvCntValue" 9 "AlvCntValue" 10 "AlvCntValue" 11 "AlvCntValue" 12 "AlvCntValue" 13 "AlvCntValue" 14 "AlvCntValue" 15 "AlvCntValue" ;
VAL_ 994 Warn_BzrWrngSta 0 "Off" 1 "SeatBelt Warning" 2 "Key Operated Warning" 3 "Parking Brake Warning" 4 "Sun Roof Open Warning" 5 "Key Learning Sound(NoSMKOption" 6 "ICE Warning" 7 "Rear Fog Warning" 8 "Reserved" 9 "Reserved" 10 "Reserved" 11 "Reserved" 12 "Reserved" 13 "Reserved" 14 "Not Used" 15 "Error Indicator" ;
VAL_ 994 Warn_BCMWrngSta 0 "Off" 1 "Power off request warning" 2 "Shift P request Warning" 3 "Reserved" 4 "Reserved" 5 "Reseved" 6 "Reseved" 7 "Reserved" 8 "Reserved" 9 "Reserved" 10 "Reserved" 11 "Reserved" 12 "Reserved" 13 "Reserved" 14 "Not Used" 15 "Error Indicator" ;
VAL_ 994 ROA_RrBlwAutoOffReq 0 "default" 1 "Request of Rear Blow Off (auto Cut)" 2 "Not Used" 3 "Error Indciator" ;
VAL_ 994 ROA_RegionOpt 0 "Non Euro NCAP CPD" 1 "Euro NCAP CPD" 2 "Reserved" 3 "Error Indicator" ;
VAL_ 994 Warn_RrStRmndOpt 0 "Not apply RrSeatRemind" 1 "Apply RrSeatRemind" 2 "Apply Radar ROA sensor" 3 "Error Indicator" ;
VAL_ 994 Warn_RrStRmndAlrmOnReq 0 "Off" 1 "On(Alarm)" 2 "Not Used" 3 "Error Indicator" ;
VAL_ 994 Warn_RrStRmndSysSta 0 "Default" 1 "System ON" 2 "System OFF" 3 "Error Indicator" ;
VAL_ 994 Warn_RrStRmndAlrmInfo 0 "Off" 1 "Rear Seat Reminder" 2 "Rear Seat Reminder 1st Only" 3 "Delayed ROA" 4 "Reserved" 5 "Reseved" 6 "Not Used" 7 "Error Indicator" ;
VAL_ 994 Warn_RoaErr 0 "Off" 1 "SensorError( Malfunction)" 2 "Reserved" 3 "Reserved" 4 "Reserved" 5 "Reseved" 6 "Not Used" 7 "Error Indicator" ;
VAL_ 994 WAL_FobSearching 0 "Not Fob Exist" 1 "Fob Exist" 2 "Reserved" 3 "Error Indicator" ;
VAL_ 994 Warn_RrStRmndDelay 0 "Off" 1 "Delayed ROA" 2 "Not Used" 3 "Error Indicator" ;
VAL_ 994 Warn_RrStRmndSysAct 0 "Default" 1 "Deactivation" 2 "Off" 3 "Error Indicator" ;
VAL_ 994 Warn_RrStRmndSysOffIND 0 "Indicator Off" 1 "Indicator On" 2 "Not Used" 3 "Error Indicator" ;
